VERSION "12.2.7"

NS_ :

BS_:

BU_: AMP CPD EASC HUD MHU XGW_Info PAS_Info PAS_LITE FCAM_Info

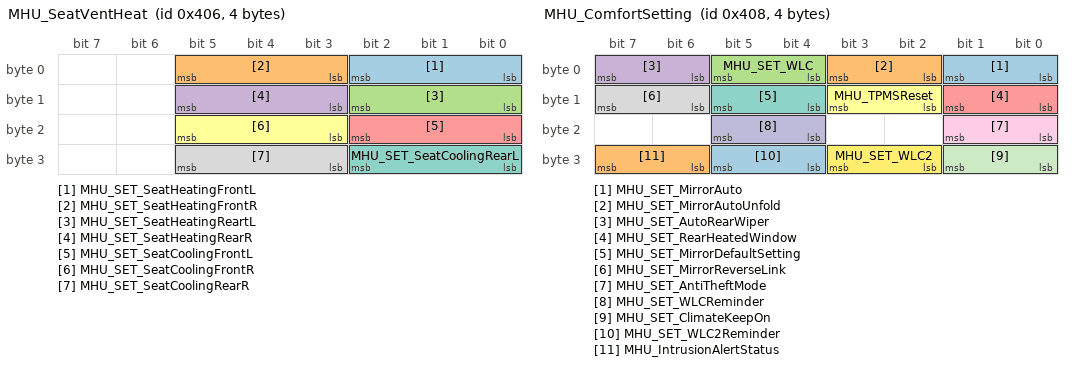
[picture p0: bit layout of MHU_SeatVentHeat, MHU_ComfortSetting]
BO_ 1030 MHU_SeatVentHeat: 4 MHU
  SG_ MHU_SET_SeatHeatingFrontL : 2|3@0+ (1,0) [0|7] "-" XGW_Info
  SG_ MHU_SET_SeatHeatingFrontR : 5|3@0+ (1,0) [0|7] "-" XGW_Info
  SG_ MHU_SET_SeatHeatingReartL : 10|3@0+ (1,0) [0|7] "-" XGW_Info
  SG_ MHU_SET_SeatHeatingRearR : 13|3@0+ (1,0) [0|7] "-" XGW_Info
  SG_ MHU_SET_SeatCoolingFrontL : 18|3@0+ (1,0) [0|7] "-" XGW_Info
  SG_ MHU_SET_SeatCoolingFrontR : 21|3@0+ (1,0) [0|7] "" XGW_Info
  SG_ MHU_SET_SeatCoolingRearL : 26|3@0+ (1,0) [0|7] "" XGW_Info
  SG_ MHU_SET_SeatCoolingRearR : 29|3@0+ (1,0) [0|7] "-" XGW_Info

BO_ 1032 MHU_ComfortSetting: 4 MHU
  SG_ MHU_SET_MirrorAuto : 1|2@0+ (1,0) [0|3] "" XGW_Info
  SG_ MHU_SET_MirrorAutoUnfold : 3|2@0+ (1,0) [0|3] "" XGW_Info
  SG_ MHU_SET_WLC : 5|2@0+ (1,0) [0|3] "-" XGW_Info
  SG_ MHU_SET_AutoRearWiper : 7|2@0+ (1,0) [0|3] "-" XGW_Info
  SG_ MHU_SET_RearHeatedWindow : 9|2@0+ (1,0) [0|3] "" XGW_Info
  SG_ MHU_TPMSReset : 11|2@0+ (1,0) [0|3] "" XGW_Info
  SG_ MHU_SET_MirrorDefaultSetting : 13|2@0+ (1,0) [0|3] "" XGW_Info
  SG_ MHU_SET_MirrorReverseLink : 15|2@0+ (1,0) [0|3] "-" XGW_Info
  SG_ MHU_SET_AntiTheftMode : 17|2@0+ (1,0) [0|3] "" XGW_Info
  SG_ MHU_SET_WLCReminder : 21|2@0+ (1,0) [0|3] "" XGW_Info
  SG_ MHU_SET_ClimateKeepOn : 25|2@0+ (1,0) [0|3] "" XGW_Info
  SG_ MHU_SET_WLC2 : 27|2@0+ (1,0) [0|3] "-" XGW_Info
  SG_ MHU_SET_WLC2Reminder : 29|2@0+ (1,0) [0|3] "-" XGW_Info
  SG_ MHU_IntrusionAlertStatus : 31|2@0+ (1,0) [0|3] "-" XGW_Info

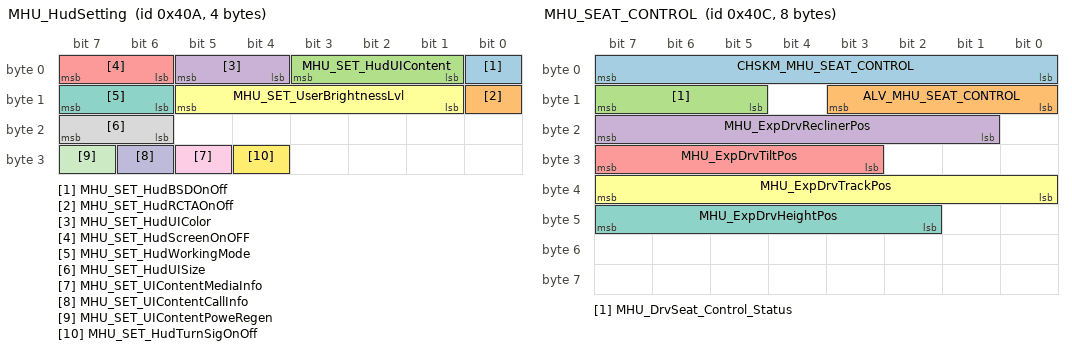
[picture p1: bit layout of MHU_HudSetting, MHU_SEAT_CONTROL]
BO_ 1034 MHU_HudSetting: 4 MHU
  SG_ MHU_SET_HudBSDOnOff : 0|1@0+ (1,0) [0|1] "" HUD
  SG_ MHU_SET_HudRCTAOnOff : 8|1@0+ (1,0) [0|1] "" HUD
  SG_ MHU_SET_HudUIContent : 3|3@0+ (1,0) [0|7] "-" HUD
  SG_ MHU_SET_HudUIColor : 5|2@0+ (1,0) [0|3] "-" HUD
  SG_ MHU_SET_HudScreenOnOFF : 7|2@0+ (1,0) [0|3] "-" HUD
  SG_ MHU_SET_UserBrightnessLvl : 13|5@0+ (1,0) [0|31] "-" HUD
  SG_ MHU_SET_HudWorkingMode : 15|2@0+ (1,0) [0|3] "-" HUD
  SG_ MHU_SET_HudUISize : 23|2@0+ (1,0) [0|3] "-" HUD
  SG_ MHU_SET_UIContentMediaInfo : 29|1@0+ (1,0) [0|1] "" HUD
  SG_ MHU_SET_UIContentCallInfo : 30|1@0+ (1,0) [0|1] "" HUD
  SG_ MHU_SET_UIContentPoweRegen : 31|1@0+ (1,0) [0|1] "" HUD
  SG_ MHU_SET_HudTurnSigOnOff : 28|1@0+ (1,0) [0|1] "" HUD

BO_ 1035 MHU_Avas_Setting: 1 MHU
  SG_ MHU_SET_AvasSound : 1|2@0+ (1,0) [0|3] "-" XGW_Info

BO_ 1036 MHU_SEAT_CONTROL: 8 MHU
  SG_ CHSKM_MHU_SEAT_CONTROL : 7|8@0+ (1,0) [0|255] "" XGW_Info
  SG_ ALV_MHU_SEAT_CONTROL : 11|4@0+ (1,0) [0|14] "" XGW_Info
  SG_ MHU_DrvSeat_Control_Status : 15|3@0+ (1,0) [0|7] "-" XGW_Info
  SG_ MHU_ExpDrvReclinerPos : 23|7@0+ (1,0) [0|127] "degree" XGW_Info
  SG_ MHU_ExpDrvTiltPos : 31|5@0+ (1,0) [0|31] "mm" XGW_Info
  SG_ MHU_ExpDrvTrackPos : 39|8@0+ (1,0) [0|255] "mm" XGW_Info
  SG_ MHU_ExpDrvHeightPos : 47|6@0+ (1,0) [0|63] "mm" XGW_Info

BO_ 1037 MHU_DIGIT_SPEED: 5 MHU
  SG_ CHKSM_MHU_DIGIT_SPEED : 7|8@0+ (1,0) [0|255] "" Vector__XXX,HUD,XGW_Info,PAS_Info,FCAM_Info,PAS_LITE
  SG_ ALV_MHU_DIGIT_SPEED : 11|4@0+ (1,0) [0|14] "" Vector__XXX,HUD,XGW_Info,PAS_Info,FCAM_Info,PAS_LITE
  SG_ MHU_DigitSpeed : 23|9@0+ (1,0) [0|300] "km/h" Vector__XXX,HUD,XGW_Info,PAS_Info,FCAM_Info,PAS_LITE

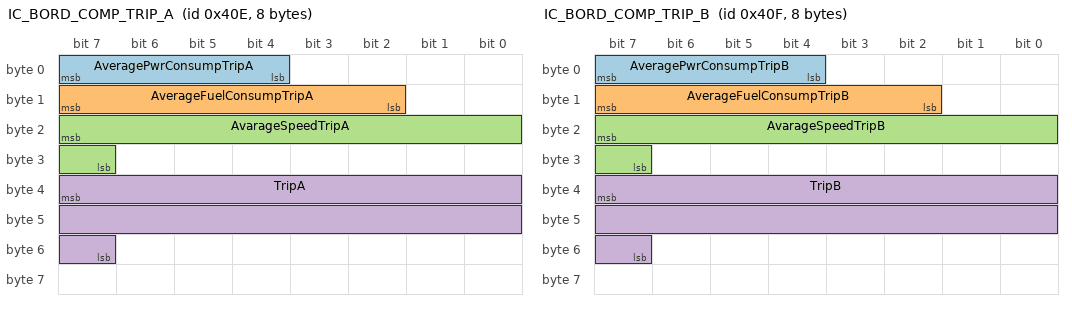
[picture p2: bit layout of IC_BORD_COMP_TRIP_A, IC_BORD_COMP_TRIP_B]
BO_ 1038 IC_BORD_COMP_TRIP_A: 8 MHU
  SG_ AveragePwrConsumpTripA : 7|4@0+ (1,0) [0|10] "km/kWh" Vector__XXX,XGW_Info
  SG_ AverageFuelConsumpTripA : 15|6@0+ (1,0) [0|51] "l/100Km" Vector__XXX,XGW_Info
  SG_ AvarageSpeedTripA : 23|9@0+ (1,0) [0|300] "kmh" Vector__XXX,XGW_Info
  SG_ TripA : 39|17@0+ (0.1,0) [0|9999.9] "km" Vector__XXX,XGW_Info

BO_ 1039 IC_BORD_COMP_TRIP_B: 8 MHU
  SG_ AveragePwrConsumpTripB : 7|4@0+ (1,0) [0|10] "km/kWh" Vector__XXX,XGW_Info
  SG_ AverageFuelConsumpTripB : 15|6@0+ (1,0) [0|51] "l/100Km" Vector__XXX,XGW_Info
  SG_ AvarageSpeedTripB : 23|9@0+ (1,0) [0|300] "kmh" Vector__XXX,XGW_Info
  SG_ TripB : 39|17@0+ (0.1,0) [0|9999.9] "km" Vector__XXX,XGW_Info

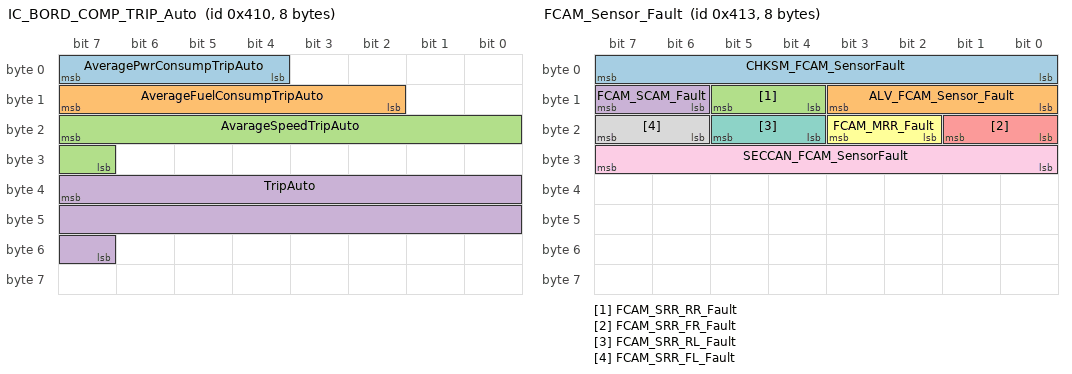
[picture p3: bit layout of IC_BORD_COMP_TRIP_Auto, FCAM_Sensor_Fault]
BO_ 1040 IC_BORD_COMP_TRIP_Auto: 8 MHU
  SG_ AveragePwrConsumpTripAuto : 7|4@0+ (1,0) [0|10] "km/kWh" Vector__XXX,XGW_Info
  SG_ AverageFuelConsumpTripAuto : 15|6@0+ (1,0) [0|51] "l/100Km" Vector__XXX,XGW_Info
  SG_ AvarageSpeedTripAuto : 23|9@0+ (1,0) [0|300] "kmh" Vector__XXX,XGW_Info
  SG_ TripAuto : 39|17@0+ (0.1,0) [0|9999.9] "km" Vector__XXX,XGW_Info

BO_ 1042 MHU_eCall_system_status: 8 MHU
 SG_ eCall_state : 2|3@0+ (1,0) [0|7] ""  XGW_Info,FCAM_Info

BO_ 1043 FCAM_Sensor_Fault: 8 FCAM_Info
 SG_ CHKSM_FCAM_SensorFault : 7|8@0+ (1,0) [0|255] ""  MHU
 SG_ ALV_FCAM_Sensor_Fault : 11|4@0+ (1,0) [0|14] ""  MHU
 SG_ FCAM_SRR_RR_Fault : 13|2@0+ (1,0) [0|3] ""  MHU
 SG_ FCAM_SCAM_Fault : 15|2@0+ (1,0) [0|3] ""  MHU
 SG_ FCAM_SRR_FR_Fault : 17|2@0+ (1,0) [0|3] ""  MHU
 SG_ FCAM_MRR_Fault : 19|2@0+ (1,0) [0|3] ""  MHU
 SG_ FCAM_SRR_RL_Fault : 21|2@0+ (1,0) [0|3] ""  MHU
 SG_ FCAM_SRR_FL_Fault : 23|2@0+ (1,0) [0|3] ""  MHU
 SG_ SECCAN_FCAM_SensorFault : 31|8@0+ (1,0) [0|255] ""  MHU

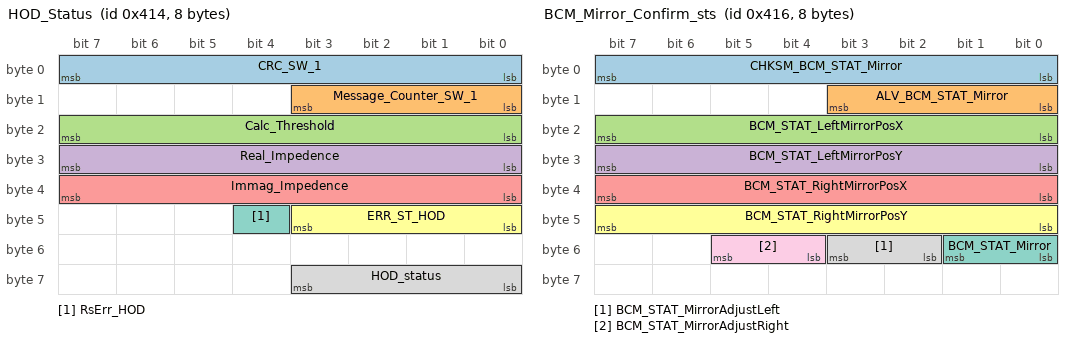
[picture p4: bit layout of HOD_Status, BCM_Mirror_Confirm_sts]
BO_ 1044 HOD_Status: 8 XGW_Info
 SG_ CRC_SW_1 : 7|8@0+ (1,0) [0|255] ""  FCAM_Info
 SG_ Message_Counter_SW_1 : 11|4@0+ (1,0) [0|14] ""  FCAM_Info
 SG_ Calc_Threshold : 23|8@0+ (1,0) [0|255] ""  Vector__XXX
 SG_ Real_Impedence : 31|8@0+ (1,0) [0|255] ""  Vector__XXX
 SG_ Immag_Impedence : 39|8@0+ (1,0) [0|255] ""  Vector__XXX
 SG_ ERR_ST_HOD : 43|4@0+ (1,0) [0|15] ""  FCAM_Info
 SG_ RsErr_HOD : 44|1@0+ (1,0) [0|1] ""  FCAM_Info
 SG_ HOD_status : 59|4@0+ (1,0) [0|15] ""  FCAM_Info

BO_ 1046 BCM_Mirror_Confirm_sts: 8 XGW_Info
  SG_ CHKSM_BCM_STAT_Mirror : 7|8@0+ (1,0) [0|255] ""  PAS_Info
  SG_ ALV_BCM_STAT_Mirror : 11|4@0+ (1,0) [0|14] ""  PAS_Info
  SG_ BCM_STAT_LeftMirrorPosX : 23|8@0+ (1,-15) [-15|15] "deg"  MHU,PAS_Info
  SG_ BCM_STAT_LeftMirrorPosY : 31|8@0+ (1,-15) [-15|15] "deg"  MHU,PAS_Info
  SG_ BCM_STAT_RightMirrorPosX : 39|8@0+ (1,-15) [-15|15] "deg"  MHU
  SG_ BCM_STAT_RightMirrorPosY : 47|8@0+ (1,-15) [-15|15] "deg"  MHU
  SG_ BCM_STAT_Mirror : 49|2@0+ (1,0) [0|3] ""  MHU,PAS_Info
  SG_ BCM_STAT_MirrorAdjustLeft : 51|2@0+ (1,0) [0|3] "-"  MHU
  SG_ BCM_STAT_MirrorAdjustRight : 53|2@0+ (1,0) [0|3] ""  MHU

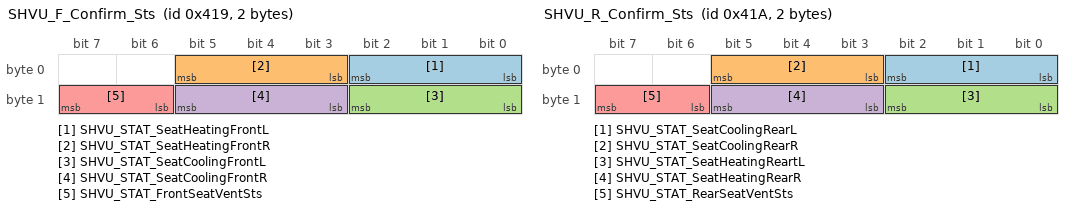
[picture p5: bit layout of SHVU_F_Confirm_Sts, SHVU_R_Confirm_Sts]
BO_ 1049 SHVU_F_Confirm_Sts: 2 XGW_Info
  SG_ SHVU_STAT_SeatHeatingFrontL : 2|3@0+ (1,0) [0|7] "-" MHU
  SG_ SHVU_STAT_SeatHeatingFrontR : 5|3@0+ (1,0) [0|7] "-" MHU
  SG_ SHVU_STAT_SeatCoolingFrontL : 10|3@0+ (1,0) [0|7] "-" MHU
  SG_ SHVU_STAT_SeatCoolingFrontR : 13|3@0+ (1,0) [0|7] "" MHU
  SG_ SHVU_STAT_FrontSeatVentSts : 15|2@0+ (1,0) [0|3] "" MHU

BO_ 1050 SHVU_R_Confirm_Sts: 2 XGW_Info
  SG_ SHVU_STAT_SeatCoolingRearL : 2|3@0+ (1,0) [0|7] "-" MHU
  SG_ SHVU_STAT_SeatCoolingRearR : 5|3@0+ (1,0) [0|7] "" MHU
  SG_ SHVU_STAT_SeatHeatingReartL : 10|3@0+ (1,0) [0|7] "" MHU
  SG_ SHVU_STAT_SeatHeatingRearR : 13|3@0+ (1,0) [0|7] "" MHU
  SG_ SHVU_STAT_RearSeatVentSts : 15|2@0+ (1,0) [0|3] "" MHU

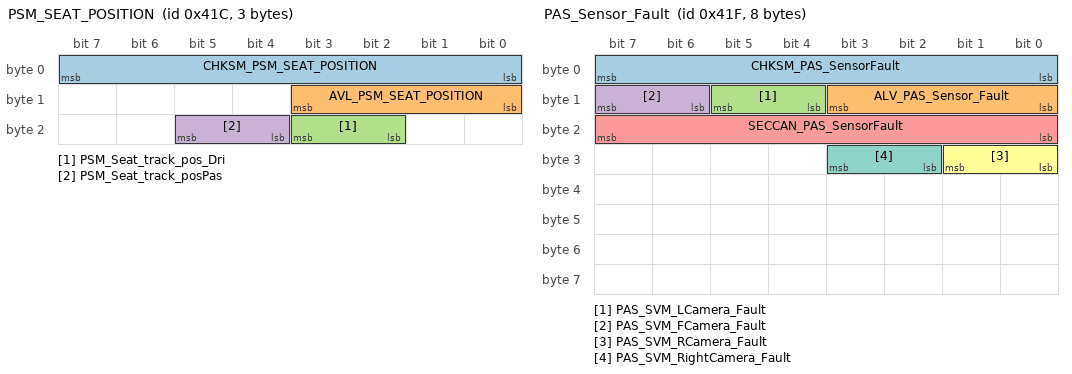
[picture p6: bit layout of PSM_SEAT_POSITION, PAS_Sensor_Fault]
BO_ 1052 PSM_SEAT_POSITION: 3 XGW_Info
  SG_ CHKSM_PSM_SEAT_POSITION : 7|8@0+ (1,0) [0|255] "" MHU
  SG_ AVL_PSM_SEAT_POSITION : 11|4@0+ (1,0) [0|14] "-" MHU
  SG_ PSM_Seat_track_pos_Dri : 19|2@0+ (1,0) [0|3] "" MHU
  SG_ PSM_Seat_track_posPas : 21|2@0+ (1,0) [0|3] "" MHU

BO_ 1053 BCM_Comfort_Confirm_sts: 8 XGW_Info
  SG_ BCM_STAT_AutoRearWiper : 1|2@0+ (1,0) [0|3] "-" MHU
  SG_ BCM_STAT_MirrorFoldSetting : 3|2@0+ (1,0) [0|3] "" MHU
  SG_ BCM_STAT_IMMO_KeyfobID2 : 7|3@0+ (1,0) [0|7] "" MHU
  SG_ BCM_STAT_MirrorAutoUnfold : 9|2@0+ (1,0) [0|3] "-" MHU
  SG_ BCM_STAT_MirrorReverseLink : 11|2@0+ (1,0) [0|3] "" MHU
  SG_ BCM_STAT_MirrorDefaultSTATting : 13|2@0+ (1,0) [0|3] "-" MHU
  SG_ BCM_STAT_WelcomeTriggerCondition : 15|2@0+ (1,0) [0|3] "" MHU
  SG_ BCM_STAT_FrontDomeLamp : 17|2@0+ (1,0) [0|3] "-" MHU
  SG_ BCM_STAT_FollowMeHome : 20|3@0+ (1,0) [0|7] "-" MHU
  SG_ BCM_STAT_ExteriorLight : 23|3@0+ (1,0) [0|7] "-" MHU
  SG_ BCM_STAT_RemoteLockFeedback : 26|3@0+ (1,0) [0|7] "-" MHU
  SG_ BCM_STAT_RemoteDoorUnlock : 28|2@0+ (1,0) [0|3] "" MHU
  SG_ BCM_STAT_AutoDoorUnlock : 30|2@0+ (1,0) [0|3] "" MHU
  SG_ BCM_STAT_WalkawayDoorLock : 31|1@0+ (1,0) [0|1] "" MHU
  SG_ BCM_STAT_AmbientLightBrighness : 39|7@0+ (1,0) [0|100] "%" MHU
  SG_ BCM_STAT_WiperServiceMode : 42|2@0+ (1,0) [0|3] "" MHU
  SG_ BCM_STAT_IMMO_KeyfobID : 45|2@0+ (1,0) [0|3] "" MHU
  SG_ BCM_STAT_RearHeatedWindowMirror : 47|2@0+ (1,0) [0|3] "" MHU
  SG_ BCM_STAT_AntiTheftMode : 50|3@0+ (1,0) [0|7] "-" MHU
  SG_ BCM_STAT_ClimateKeepOnSts : 53|2@0+ (1,0) [0|3] "" MHU
  SG_ BCM_STAT_FKSfeedback : 55|2@0+ (1,0) [0|3] "" MHU
  SG_ SECCAN_CmftCnfrm : 63|8@0+ (1,0) [0|255] "" MHU

BO_ 1054 HUD_State: 8 HUD
  SG_ HUD_BSDOnOff_Feed : 0|1@0+ (1,0) [0|1] "-" MHU
  SG_ HUD_RCTAOnOff_Feed : 8|1@0+ (1,0) [0|1] "-" MHU
  SG_ HUD_UIColor : 2|2@0+ (1,0) [0|3] "-" MHU
  SG_ HUD_UIContent : 5|3@0+ (1,0) [0|7] "-" MHU
  SG_ HUD_OperationState : 7|2@0+ (1,0) [0|3] "-" MHU
  SG_ HUD_HeightLvl : 13|5@0+ (1,0) [0|31] "-" MHU
  SG_ HUD_UI_Size : 15|2@0+ (1,0) [0|3] "-" MHU
  SG_ HUD_UIContentMediaInfo : 16|1@0+ (1,0) [0|1] "" MHU
  SG_ HUD_UIContentCallInfor : 17|1@0+ (1,0) [0|1] "" MHU
  SG_ HUD_UIContentPowerRegen : 18|1@0+ (1,0) [0|1] "" MHU
  SG_ HUD_UIModeSignal : 21|3@0+ (1,0) [0|7] "-" MHU
  SG_ HUD_WorkingMode : 23|2@0+ (1,0) [0|3] "-" MHU
  SG_ HUD_ActualBrightnes : 31|14@0+ (1,0) [0|12000] "cd/m2" MHU
  SG_ HUD_RotateAngleLvl : 42|4@0+ (1,0) [0|15] "-" MHU
  SG_ HUD_UserSetBrightnessLvl : 47|5@0+ (1,0) [0|31] "-" MHU
  SG_ HUD_Language : 54|5@0+ (1,0) [0|31] "-" MHU
  SG_ HUD_TurnSigOnOff_Feed : 56|1@0+ (1,0) [0|1] "-" MHU
  SG_ HUD_Mileage_Unit : 57|1@0+ (1,0) [0|1] "-" MHU
  SG_ HUD_UserProfileId : 61|4@0+ (1,0) [0|15] "-" MHU
  SG_ HUD_DimmingDelayTime : 63|2@0+ (1,0) [0|3] "-" MHU

BO_ 1055 PAS_Sensor_Fault: 8 PAS_Info
 SG_ CHKSM_PAS_SensorFault : 7|8@0+ (1,0) [0|255] ""  MHU
 SG_ ALV_PAS_Sensor_Fault : 11|4@0+ (1,0) [0|14] ""  MHU
 SG_ PAS_SVM_LCamera_Fault : 13|2@0+ (1,0) [0|3] ""  MHU
 SG_ PAS_SVM_FCamera_Fault : 15|2@0+ (1,0) [0|3] ""  MHU
 SG_ SECCAN_PAS_SensorFault : 23|8@0+ (1,0) [0|255] ""  MHU
 SG_ PAS_SVM_RCamera_Fault : 25|2@0+ (1,0) [0|3] ""  MHU
 SG_ PAS_SVM_RightCamera_Fault : 27|2@0+ (1,0) [0|3] ""  MHU

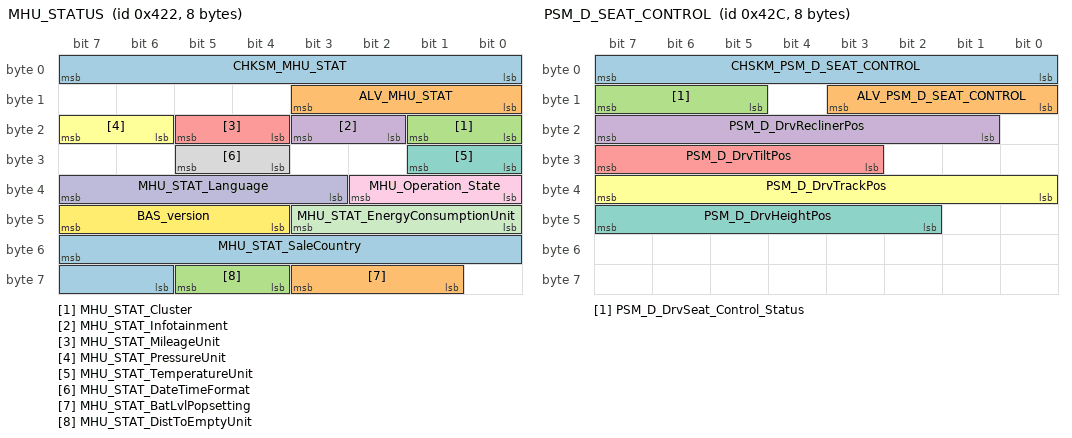
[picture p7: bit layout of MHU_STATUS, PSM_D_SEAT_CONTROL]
BO_ 1058 MHU_STATUS: 8 MHU
  SG_ CHKSM_MHU_STAT : 7|8@0+ (1,0) [0|255] "" Vector__XXX,HUD,XGW_Info,FCAM_Info
  SG_ ALV_MHU_STAT : 11|4@0+ (1,0) [0|14] "" Vector__XXX,HUD,XGW_Info,FCAM_Info
  SG_ MHU_STAT_Cluster : 17|2@0+ (1,0) [0|3] "-" Vector__XXX,HUD,XGW_Info,FCAM_Info
  SG_ MHU_STAT_Infotainment : 19|2@0+ (1,0) [0|3] "" Vector__XXX,HUD,XGW_Info,FCAM_Info
  SG_ MHU_STAT_MileageUnit : 21|2@0+ (1,0) [0|3] "" Vector__XXX,HUD,XGW_Info,FCAM_Info
  SG_ MHU_STAT_PressureUnit : 23|2@0+ (1,0) [0|3] "-" HUD,XGW_Info
  SG_ MHU_STAT_TemperatureUnit : 25|2@0+ (1,0) [0|3] "-" HUD,XGW_Info
  SG_ MHU_STAT_DateTimeFormat : 29|2@0+ (1,0) [0|3] "-" HUD,XGW_Info
  SG_ MHU_Operation_State : 34|3@0+ (1,0) [0|7] "" Vector__XXX,HUD,XGW_Info,FCAM_Info
  SG_ MHU_STAT_Language : 39|5@0+ (1,0) [0|31] "-" HUD,XGW_Info
  SG_ MHU_STAT_EnergyConsumptionUnit : 43|4@0+ (1,0) [0|15] "-" Vector__XXX,HUD,XGW_Info,FCAM_Info
  SG_ BAS_version : 47|4@0+ (1,0) [0|15] "" XGW_Info
  SG_ MHU_STAT_SaleCountry : 55|10@0+ (1,0) [0|1023] "-" Vector__XXX,HUD,XGW_Info,FCAM_Info
  SG_ MHU_STAT_BatLvlPopsetting : 59|3@0+ (1,0) [0|7] "-" HUD
  SG_ MHU_STAT_DistToEmptyUnit : 61|2@0+ (1,0) [0|3] "-" HUD

BO_ 1059 AVAS_STATUS: 8 XGW_Info
  SG_ AVAS_BatteryUnderVoltage : 0|1@0+ (1,0) [0|1] "-" MHU
  SG_ AVAS_BatteryOverVoltage : 1|1@0+ (1,0) [0|1] "-" MHU
  SG_ AVAS_VINInfoNotPrgm : 2|1@0+ (1,0) [0|1] "" MHU
  SG_ AVAS_AMPVoltSplDrvOperationFail : 3|1@0+ (1,0) [0|1] "-" MHU
  SG_ AVAS_AMPIntFaultOverCurr : 4|1@0+ (1,0) [0|1] "" MHU
  SG_ AVAS_AMPInternalFaultDCError : 5|1@0+ (1,0) [0|1] "" MHU
  SG_ AVAS_AMPInternalFaultOverTemp : 6|1@0+ (1,0) [0|1] "" MHU
  SG_ AVAS_AMPInternalFaultClockError : 7|1@0+ (1,0) [0|1] "-" MHU
  SG_ AVAS_SpkrMntPwrSwDrvHighFlt : 8|1@0+ (1,0) [0|1] "-" MHU
  SG_ AVAS_SpkrMntPwrSwDrvLowFlt : 9|1@0+ (1,0) [0|1] "-" MHU
  SG_ AVAS_InternalSpeakerOpen : 10|1@0+ (1,0) [0|1] "" MHU
  SG_ AVAS_ECUMalFlshOperationErr : 11|1@0+ (1,0) [0|1] "" MHU
  SG_ AVAS_ECUMalfunctionRamFailure : 12|1@0+ (1,0) [0|1] "-" MHU
  SG_ AVAS_ECUMalEEPROMFailure : 13|1@0+ (1,0) [0|1] "" MHU
  SG_ AVAS_CANBusOff : 14|1@0+ (1,0) [0|1] "-" MHU
  SG_ AVAS_LossCommVehicleSpeed : 15|1@0+ (1,0) [0|1] "" MHU
  SG_ AVAS_LossCommGearPosition : 16|1@0+ (1,0) [0|1] "-" MHU
  SG_ AVAS_LossCommAVASCloseCmd : 17|1@0+ (1,0) [0|1] "-" MHU

BO_ 1064 XGW_CH_1: 1 XGW_Info
 SG_ TRMFitted : 2|2@0+ (1,0) [0|3] "" PAS_LITE

BO_ 1068 PSM_D_SEAT_CONTROL: 8 XGW_Info
  SG_ CHSKM_PSM_D_SEAT_CONTROL : 7|8@0+ (1,0) [0|255] "" MHU
  SG_ ALV_PSM_D_SEAT_CONTROL : 11|4@0+ (1,0) [0|14] "" MHU
  SG_ PSM_D_DrvSeat_Control_Status : 15|3@0+ (1,0) [0|7] "" MHU
  SG_ PSM_D_DrvReclinerPos : 23|7@0+ (1,0) [0|127] "degree" MHU
  SG_ PSM_D_DrvTiltPos : 31|5@0+ (1,0) [0|31] "mm" MHU
  SG_ PSM_D_DrvTrackPos : 39|8@0+ (1,0) [0|255] "mm" MHU
  SG_ PSM_D_DrvHeightPos : 47|6@0+ (1,0) [0|63] "mm" MHU

BO_ 1069 XGW_Info_Collect: 3 XGW_Info
  SG_ XGW_WasherFluid_LevelSwitch : 1|2@0+ (1,0) [0|3] "Bit" MHU

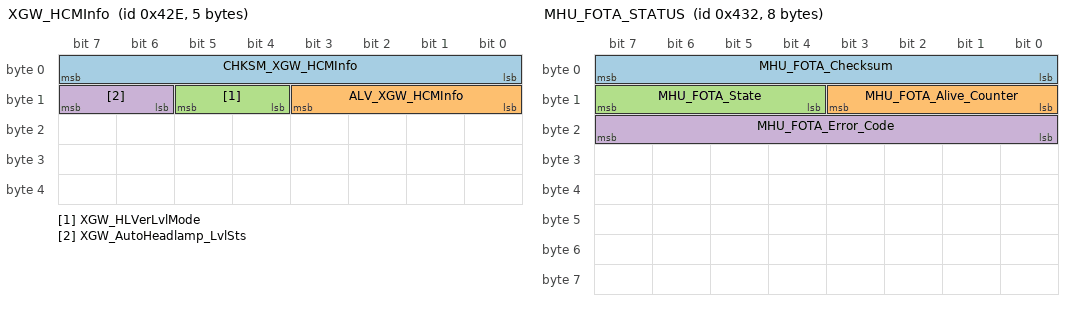
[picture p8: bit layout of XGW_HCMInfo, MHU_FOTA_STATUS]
BO_ 1070 XGW_HCMInfo: 5 XGW_Info
  SG_ CHKSM_XGW_HCMInfo : 7|8@0+ (1,0) [0|255] "" MHU
  SG_ ALV_XGW_HCMInfo : 11|4@0+ (1,0) [0|14] "" MHU
  SG_ XGW_HLVerLvlMode : 13|2@0+ (1,0) [0|3] "-" MHU
  SG_ XGW_AutoHeadlamp_LvlSts : 15|2@0+ (1,0) [0|3] "-" MHU

BO_ 1073 HUD_ECU_Status: 2 HUD
  SG_ HUD_ECU_Check : 7|8@0+ (1,0) [0|255] "-" XGW_Info
  SG_ HUD_ECU_Fault : 15|8@0+ (1,0) [0|255] "-" XGW_Info

BO_ 1074 MHU_FOTA_STATUS: 8 MHU
  SG_ MHU_FOTA_Checksum : 7|8@0+ (1,0) [0|255] "" AMP,FCAM_Info,CPD,EASC,HUD,PAS_Info,XGW_Info
  SG_ MHU_FOTA_Alive_Counter : 11|4@0+ (1,0) [0|14] "" AMP,FCAM_Info,CPD,EASC,HUD,PAS_Info,XGW_Info
  SG_ MHU_FOTA_State : 15|4@0+ (1,0) [0|14] "-" AMP,FCAM_Info,CPD,EASC,HUD,PAS_Info,XGW_Info
  SG_ MHU_FOTA_Error_Code : 23|8@0+ (1,0) [0|255] "-" AMP,FCAM_Info,CPD,EASC,HUD,PAS_Info,XGW_Info

BO_ 1075 MHU_HEADLAMP_CTL: 2 MHU
  SG_ MHU_Headlamp_Chksm : 7|8@0+ (1,0) [0|255] "-" XGW_Info
  SG_ MHU_Headlamp_Aliv : 11|4@0+ (1,0) [0|14] "-" XGW_Info
  SG_ MHU_HLVerLvlMode : 15|2@0+ (1,0) [0|3] "-" XGW_Info

BO_ 1077 BCM_SCM_LIN_Info: 1 XGW_Info
  SG_ BCM_SCM_BC_Button : 1|2@0+ (1,0) [0|3] "-" HUD,MHU

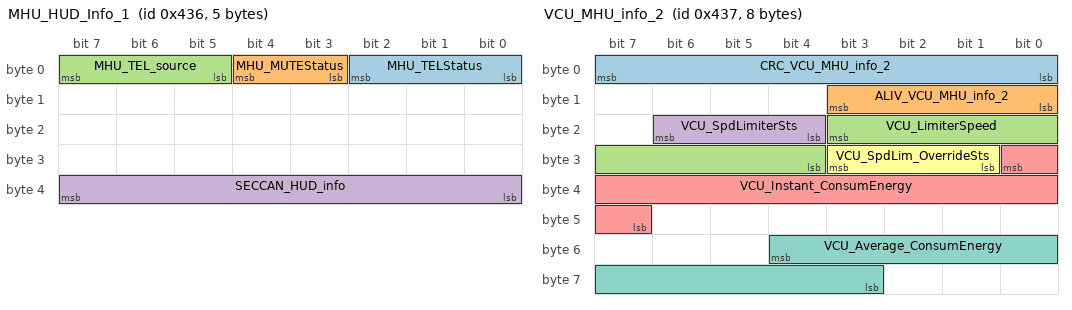
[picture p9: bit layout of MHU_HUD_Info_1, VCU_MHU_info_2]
BO_ 1078 MHU_HUD_Info_1: 5 MHU
  SG_ MHU_TELStatus : 2|3@0+ (1,0) [0|7] "-" HUD
  SG_ MHU_MUTEStatus : 4|2@0+ (1,0) [0|3] "-" HUD
  SG_ MHU_TEL_source : 7|3@0+ (1,0) [0|7] "-" HUD
  SG_ SECCAN_HUD_info : 39|8@0+ (1,0) [0|255] "" HUD

BO_ 1079 VCU_MHU_info_2: 8 XGW_Info
  SG_ CRC_VCU_MHU_info_2 : 7|8@0+ (1,0) [0|255] "" MHU,HUD
  SG_ ALIV_VCU_MHU_info_2 : 11|4@0+ (1,0) [0|14] "" MHU,HUD
  SG_ VCU_LimiterSpeed : 19|8@0+ (1,0) [0|200] "km/h"  MHU,HUD
  SG_ VCU_SpdLimiterSts : 22|3@0+ (1,0) [0|7] ""  MHU,HUD
  SG_ VCU_Instant_ConsumEnergy : 24|10@0+ (0.1,0) [0|100] "kWh/100km" MHU
  SG_ VCU_SpdLim_OverrideSts : 27|3@0+ (10,0) [0|30] "km/h"  MHU
  SG_ VCU_Average_ConsumEnergy : 52|10@0+ (0.1,0) [0|100] "kWh/100km" MHU

BO_ 1080 EDS_Error_FR_A: 8 XGW_Info
  SG_ CHKSM_EDS_Error_FR_A : 7|8@0+ (1,0) [0|255] "" MHU
  SG_ ALV_EDS_Error_FR_A : 11|4@0+ (1,0) [0|14] "" MHU
  SG_ EDS_FailNum_ERR_FWD : 23|8@0+ (1,0) [0|255] "" MHU
  SG_ EDS_FailGrade_ERR_FWD : 26|3@0+ (1,0) [0|7] "" MHU
  SG_ EDS_MotOverTempAlarm_FWD : 27|1@0+ (1,0) [0|1] "" MHU
  SG_ EDS_MotOverTempFault_FWD : 28|1@0+ (1,0) [0|1] "" MHU
  SG_ EDS_MotTempSenFault_FWD : 29|1@0+ (1,0) [0|1] "" MHU
  SG_ EDS_EDSOverTempUFault_FWD : 30|1@0+ (1,0) [0|1] "" MHU
  SG_ EDS_EDSOverTempVFault_FWD : 31|1@0+ (1,0) [0|1] "" MHU
  SG_ EDS_EDSOverTempWFault_FWD : 32|1@0+ (1,0) [0|1] "" MHU
  SG_ EDS_EDSOverTempAlarm_FWD : 33|1@0+ (1,0) [0|1] "" MHU
  SG_ EDS_TCoolantOvHi_FWD : 34|1@0+ (1,0) [0|1] "" MHU
  SG_ EDS_EDSTempCmpAlarm_FWD : 35|1@0+ (1,0) [0|1] "" MHU
  SG_ EDS_EDSPhaOvCurentHWFault_FWD : 36|1@0+ (1,0) [0|1] "" MHU
  SG_ EDS_EDSphaOffCalFault_FWD : 37|1@0+ (1,0) [0|1] "" MHU
  SG_ EDS_EDSOverIdcLnkAlarm_FWD : 38|1@0+ (1,0) [0|1] "" MHU
  SG_ EDS_EDSHVOverVoltageAlarm_FWD : 39|1@0+ (1,0) [0|1] "" MHU
  SG_ EDS_EDSHVOverVoltageFault_FWD : 40|1@0+ (1,0) [0|1] "" MHU
  SG_ EDS_EDSHVUnderVoltageAlarm_FWD : 41|1@0+ (1,0) [0|1] "" MHU
  SG_ EDS_EDSHVUnderVoltageFault_FWD : 42|1@0+ (1,0) [0|1] "" MHU
  SG_ EDS_RunToDischaErr_FWD : 43|1@0+ (1,0) [0|1] "" MHU
  SG_ EDS_12VOverVoltageAlarm_FWD : 44|1@0+ (1,0) [0|1] "" MHU
  SG_ EDS_12VUnderVoltageAlarm_FWD : 45|1@0+ (1,0) [0|1] "" MHU
  SG_ EDS_MotOverAlarm_FWD : 46|1@0+ (1,0) [0|1] "" MHU
  SG_ EDS_MotOverFault_FWD : 47|1@0+ (1,0) [0|1] "" MHU
  SG_ EDS_ResolverOffsetAngle_FWD : 48|1@0+ (1,0) [0|1] "" MHU
  SG_ SECCAN_EDS_Error_FR_A : 63|8@0+ (1,0) [0|255] "" MHU

BO_ 1081 EDS_Error_RR_A: 8 XGW_Info
  SG_ CHKSM_EDS_Error_RR_A : 7|8@0+ (1,0) [0|255] "" MHU
  SG_ ALV_EDS_Error_RR_A : 11|4@0+ (1,0) [0|14] "" MHU
  SG_ EDS_FailNum_ERR_RWD : 23|8@0+ (1,0) [0|255] "" MHU
  SG_ EDS_FailGrade_ERR_RWD : 26|3@0+ (1,0) [0|7] "" MHU
  SG_ EDS_MotOverTempAlarm_RWD : 27|1@0+ (1,0) [0|1] "" MHU
  SG_ EDS_MotOverTempFault_RWD : 28|1@0+ (1,0) [0|1] "" MHU
  SG_ EDS_MotTempSenFault_RWD : 29|1@0+ (1,0) [0|1] "" MHU
  SG_ EDS_EDSOverTempUFault_RWD : 30|1@0+ (1,0) [0|1] "" MHU
  SG_ EDS_EDSOverTempVFault_RWD : 31|1@0+ (1,0) [0|1] "" MHU
  SG_ EDS_EDSOverTempWFault_RWD : 32|1@0+ (1,0) [0|1] "" MHU
  SG_ EDS_EDSOverTempAlarm_RWD : 33|1@0+ (1,0) [0|1] "" MHU
  SG_ EDS_TCoolantOvHi_RWD : 34|1@0+ (1,0) [0|1] "" MHU
  SG_ EDS_EDSTempCmpAlarm_RWD : 35|1@0+ (1,0) [0|1] "" MHU
  SG_ EDS_EDSPhaOvCurentHWFault_RWD : 36|1@0+ (1,0) [0|1] "" MHU
  SG_ EDS_EDSphaOffCalFault_RWD : 37|1@0+ (1,0) [0|1] "" MHU
  SG_ EDS_EDSOverIdcLnkAlarm_RWD : 38|1@0+ (1,0) [0|1] "" MHU
  SG_ EDS_EDSHVOverVoltageAlarm_RWD : 39|1@0+ (1,0) [0|1] "" MHU
  SG_ EDS_EDSHVOverVoltageFault_RWD : 40|1@0+ (1,0) [0|1] "" MHU
  SG_ EDS_EDSHVUnderVoltageAlarm_RWD : 41|1@0+ (1,0) [0|1] "" MHU
  SG_ EDS_EDSHVUnderVoltageFault_RWD : 42|1@0+ (1,0) [0|1] "" MHU
  SG_ EDS_RunToDischaErr_RWD : 43|1@0+ (1,0) [0|1] "" MHU
  SG_ EDS_12VOverVoltageAlarm_RWD : 44|1@0+ (1,0) [0|1] "" MHU
  SG_ EDS_12VUnderVoltageAlarm_RWD : 45|1@0+ (1,0) [0|1] "" MHU
  SG_ EDS_MotOverAlarm_RWD : 46|1@0+ (1,0) [0|1] "" MHU
  SG_ EDS_MotOverFault_RWD : 47|1@0+ (1,0) [0|1] "" MHU
  SG_ EDS_ResolverOffsetAngle_RWD : 48|1@0+ (1,0) [0|1] "" MHU
  SG_ SECCAN_EDS_Error_RR_A : 63|8@0+ (1,0) [0|255] "" MHU

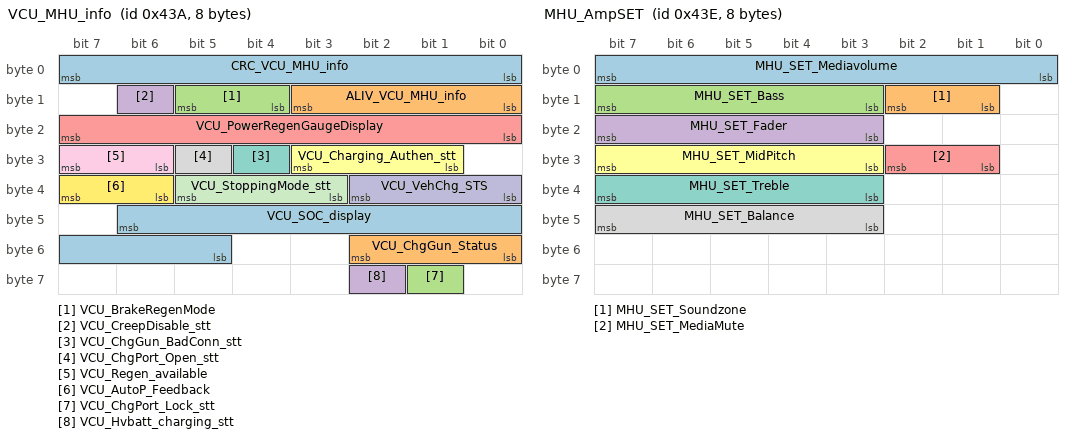
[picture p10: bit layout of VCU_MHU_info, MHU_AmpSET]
BO_ 1082 VCU_MHU_info: 8 XGW_Info
  SG_ CRC_VCU_MHU_info : 7|8@0+ (1,0) [0|255] "" HUD,MHU
  SG_ ALIV_VCU_MHU_info : 11|4@0+ (1,0) [0|14] "" HUD,MHU
  SG_ VCU_BrakeRegenMode : 13|2@0+ (1,0) [0|3] "-" HUD,MHU
  SG_ VCU_CreepDisable_stt : 14|1@0+ (1,0) [0|1] "" HUD,MHU
  SG_ VCU_PowerRegenGaugeDisplay : 23|8@0+ (1,-100) [-100|100] "%" HUD,MHU
  SG_ VCU_Charging_Authen_stt : 27|3@0+ (1,0) [0|7] "-" HUD,MHU
  SG_ VCU_ChgGun_BadConn_stt : 28|1@0+ (1,0) [0|1] "" HUD,MHU
  SG_ VCU_ChgPort_Open_stt : 29|1@0+ (1,0) [0|1] "" HUD,MHU
  SG_ VCU_Regen_available : 31|2@0+ (1,0) [0|3] "" HUD,MHU
  SG_ VCU_VehChg_STS : 34|3@0+ (1,0) [0|7] "" HUD,MHU
  SG_ VCU_StoppingMode_stt : 37|3@0+ (1,0) [0|7] "" MHU
  SG_ VCU_AutoP_Feedback : 39|2@0+ (1,0) [0|3] ""  MHU
  SG_ VCU_SOC_display : 46|10@0+ (0.1,0) [0|100] "%" HUD,MHU
  SG_ VCU_ChgGun_Status : 50|3@0+ (1,0) [0|7] "" HUD,MHU
  SG_ VCU_ChgPort_Lock_stt : 57|1@0+ (1,0) [0|1] "" HUD,MHU
  SG_ VCU_Hvbatt_charging_stt : 58|1@0+ (1,0) [0|1] "-" HUD,MHU

BO_ 1083 MHU_SteeringAdjust: 3 MHU
  SG_ MHU_SET_TiltPos : 7|8@0+ (1,0) [0|100] "%" EASC
  SG_ MHU_SET_TelePos : 15|8@0+ (1,0) [0|100] "%" EASC
  SG_ MHU_SET_SteeringAdjust : 23|2@0+ (1,0) [0|3] "-" EASC

BO_ 1084 EASC_Confirm_sts: 3 EASC
  SG_ EASC_TiltPos : 7|8@0+ (1,0) [0|100] "%" MHU
  SG_ EASC_TelePos : 15|8@0+ (1,0) [0|100] "%" MHU
  SG_ EASC_SteeringAdjust : 23|2@0+ (1,0) [0|3] "-" MHU

BO_ 1086 MHU_AmpSET: 8 MHU
  SG_ MHU_SET_Mediavolume : 7|8@0+ (1,0) [0|40] "-" AMP
  SG_ MHU_SET_Soundzone : 10|2@0+ (1,0) [0|3] "-" AMP
  SG_ MHU_SET_Bass : 15|5@0+ (1,-6) [-6|6] "-" AMP
  SG_ MHU_SET_Fader : 23|5@0+ (1,-10) [-10|10] "-" AMP
  SG_ MHU_SET_MediaMute : 26|2@0+ (1,0) [1|3] "-" AMP
  SG_ MHU_SET_MidPitch : 31|5@0+ (1,-6) [-6|6] "-" AMP
  SG_ MHU_SET_Treble : 39|5@0+ (1,-6) [-6|6] "-" AMP
  SG_ MHU_SET_Balance : 47|5@0+ (1,-10) [-10|10] "-" AMP

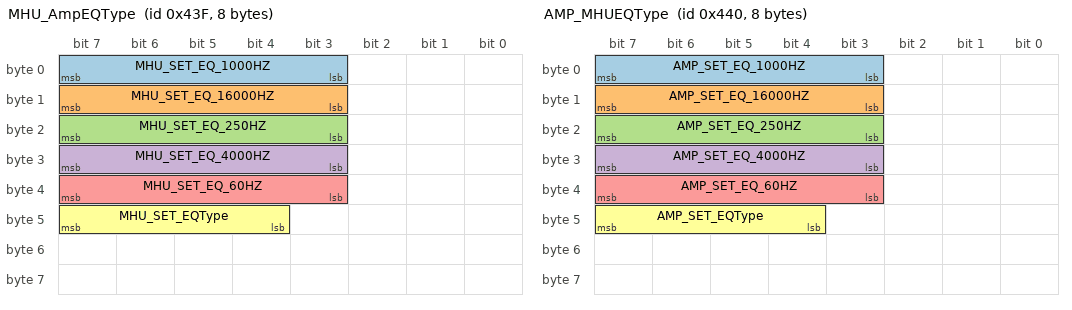
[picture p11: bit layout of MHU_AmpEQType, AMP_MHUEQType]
BO_ 1087 MHU_AmpEQType: 8 MHU
  SG_ MHU_SET_EQ_1000HZ : 7|5@0+ (1,-6) [-6|6] "-" AMP
  SG_ MHU_SET_EQ_16000HZ : 15|5@0+ (1,-6) [-6|6] "-" AMP
  SG_ MHU_SET_EQ_250HZ : 23|5@0+ (1,-6) [-6|6] "-" AMP
  SG_ MHU_SET_EQ_4000HZ : 31|5@0+ (1,-6) [-6|6] "-" AMP
  SG_ MHU_SET_EQ_60HZ : 39|5@0+ (1,-6) [-6|6] "-" AMP
  SG_ MHU_SET_EQType : 47|4@0+ (1,0) [0|15] "-" AMP

BO_ 1088 AMP_MHUEQType: 8 AMP
  SG_ AMP_SET_EQ_1000HZ : 7|5@0+ (1,-6) [-6|6] "-" MHU
  SG_ AMP_SET_EQ_16000HZ : 15|5@0+ (1,-6) [-6|6] "-" MHU
  SG_ AMP_SET_EQ_250HZ : 23|5@0+ (1,-6) [-6|6] "-" MHU
  SG_ AMP_SET_EQ_4000HZ : 31|5@0+ (1,-6) [-6|6] "-" MHU
  SG_ AMP_SET_EQ_60HZ : 39|5@0+ (1,-6) [-6|6] "-" MHU
  SG_ AMP_SET_EQType : 47|4@0+ (1,0) [0|15] "-" MHU

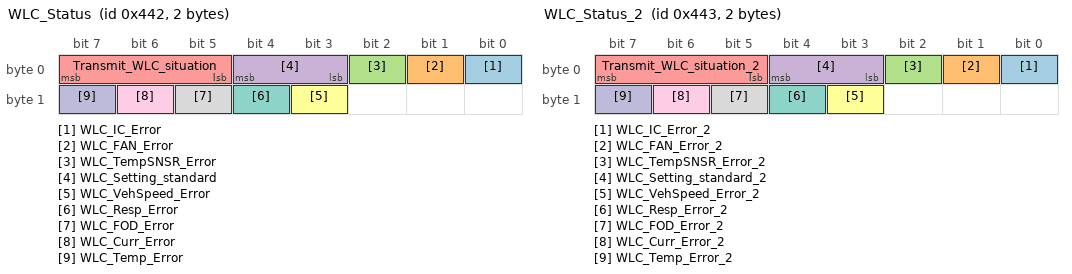
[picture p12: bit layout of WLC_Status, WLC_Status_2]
BO_ 1090 WLC_Status: 2 XGW_Info
  SG_ WLC_IC_Error : 0|1@0+ (1,0) [0|1] "" MHU
  SG_ WLC_FAN_Error : 1|1@0+ (1,0) [0|1] "-" MHU
  SG_ WLC_TempSNSR_Error : 2|1@0+ (1,0) [0|1] "-" MHU
  SG_ WLC_Setting_standard : 4|2@0+ (1,0) [0|3] "-" MHU
  SG_ Transmit_WLC_situation : 7|3@0+ (1,0) [0|7] "" MHU
  SG_ WLC_VehSpeed_Error : 11|1@0+ (1,0) [0|1] "" MHU
  SG_ WLC_Resp_Error : 12|1@0+ (1,0) [0|1] "" MHU
  SG_ WLC_FOD_Error : 13|1@0+ (1,0) [0|1] "-" MHU
  SG_ WLC_Curr_Error : 14|1@0+ (1,0) [0|1] "-" MHU
  SG_ WLC_Temp_Error : 15|1@0+ (1,0) [0|1] "" MHU

BO_ 1091 WLC_Status_2: 2 XGW_Info
  SG_ WLC_IC_Error_2 : 0|1@0+ (1,0) [0|1] "-" MHU
  SG_ WLC_FAN_Error_2 : 1|1@0+ (1,0) [0|1] "" MHU
  SG_ WLC_TempSNSR_Error_2 : 2|1@0+ (1,0) [0|1] "-" MHU
  SG_ WLC_Setting_standard_2 : 4|2@0+ (1,0) [0|3] "" MHU
  SG_ Transmit_WLC_situation_2 : 7|3@0+ (1,0) [0|7] "" MHU
  SG_ WLC_VehSpeed_Error_2 : 11|1@0+ (1,0) [0|1] "" MHU
  SG_ WLC_Resp_Error_2 : 12|1@0+ (1,0) [0|1] "-" MHU
  SG_ WLC_FOD_Error_2 : 13|1@0+ (1,0) [0|1] "-" MHU
  SG_ WLC_Curr_Error_2 : 14|1@0+ (1,0) [0|1] "-" MHU
  SG_ WLC_Temp_Error_2 : 15|1@0+ (1,0) [0|1] "" MHU

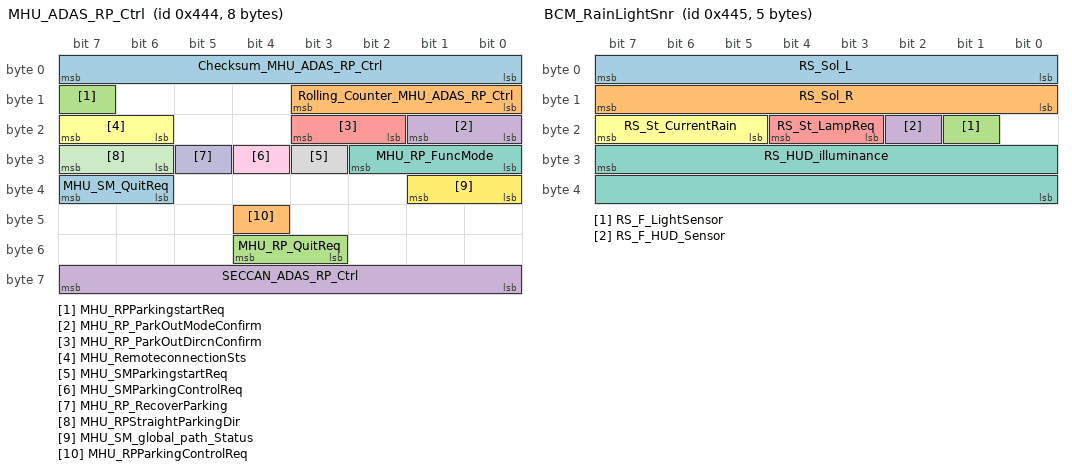
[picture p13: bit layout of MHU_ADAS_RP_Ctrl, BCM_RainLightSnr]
BO_ 1092 MHU_ADAS_RP_Ctrl: 8 MHU
  SG_ Checksum_MHU_ADAS_RP_Ctrl : 7|8@0+ (1,0) [0|255] "" Vector__XXX,PAS_Info
  SG_ Rolling_Counter_MHU_ADAS_RP_Ctrl : 11|4@0+ (1,0) [0|14] "" Vector__XXX,PAS_Info
  SG_ MHU_RPParkingstartReq : 15|1@0+ (1,0) [0|1] "-" Vector__XXX,PAS_Info
  SG_ MHU_RP_ParkOutModeConfirm : 17|2@0+ (1,0) [0|3] "-" Vector__XXX,PAS_Info
  SG_ MHU_RP_ParkOutDircnConfirm : 19|2@0+ (1,0) [0|3] "-" Vector__XXX,PAS_Info
  SG_ MHU_RemoteconnectionSts : 23|2@0+ (1,0) [0|3] "-" Vector__XXX,PAS_Info
  SG_ MHU_RP_FuncMode : 26|3@0+ (1,0) [0|7] "-" Vector__XXX,PAS_Info
  SG_ MHU_SMParkingstartReq : 27|1@0+ (1,0) [0|1] "" Vector__XXX,PAS_Info
  SG_ MHU_SMParkingControlReq : 28|1@0+ (1,0) [0|1] "" Vector__XXX,PAS_Info
  SG_ MHU_RP_RecoverParking : 29|1@0+ (1,0) [0|1] "-" Vector__XXX,PAS_Info
  SG_ MHU_RPStraightParkingDir : 31|2@0+ (1,0) [0|3] "-" Vector__XXX,PAS_Info
  SG_ MHU_SM_global_path_Status : 33|2@0+ (1,0) [0|3] "" Vector__XXX,PAS_Info
  SG_ MHU_SM_QuitReq : 39|2@0+ (1,0) [0|3] "" Vector__XXX,PAS_Info
  SG_ MHU_RPParkingControlReq : 44|1@0+ (1,0) [0|1] "-" Vector__XXX,PAS_Info
  SG_ MHU_RP_QuitReq : 52|2@0+ (1,0) [0|3] "-" Vector__XXX,PAS_Info
  SG_ SECCAN_ADAS_RP_Ctrl : 63|8@0+ (1,0) [0|255] "" Vector__XXX,PAS_Info

BO_ 1093 BCM_RainLightSnr: 5 XGW_Info
  SG_ RS_Sol_L : 7|8@0+ (5,0) [0|1000] "W/m^2" MHU
  SG_ RS_Sol_R : 15|8@0+ (5,0) [0|1000] "W/m^2" MHU
  SG_ RS_F_LightSensor : 17|1@0+ (1,0) [0|1] "" HUD,MHU
  SG_ RS_F_HUD_Sensor : 18|1@0+ (1,0) [0|1] "cd/m2" HUD,MHU
  SG_ RS_St_LampReq : 20|2@0+ (1,0) [0|3] "" MHU
  SG_ RS_St_CurrentRain : 23|3@0+ (1,0) [0|7] "" MHU
  SG_ RS_HUD_illuminance : 31|16@0+ (1,0) [0|10000] "cd/m2" HUD,MHU

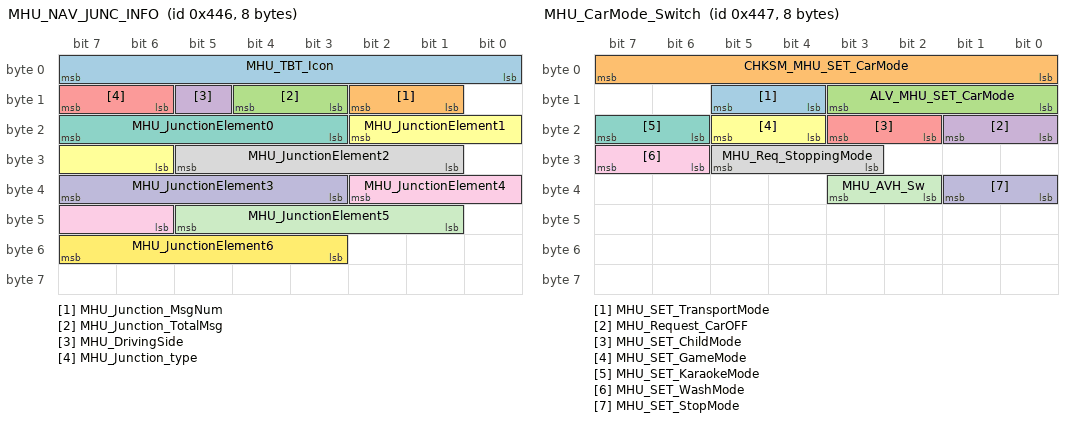
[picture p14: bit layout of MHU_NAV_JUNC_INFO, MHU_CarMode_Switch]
BO_ 1094 MHU_NAV_JUNC_INFO: 8 MHU
  SG_ MHU_TBT_Icon : 7|8@0+ (1,0) [0|255] "-" HUD
  SG_ MHU_Junction_MsgNum : 10|2@0+ (1,0) [0|3] "-" HUD
  SG_ MHU_Junction_TotalMsg : 12|2@0+ (1,0) [0|3] "-" HUD
  SG_ MHU_DrivingSide : 13|1@0+ (1,0) [0|1] "-" HUD
  SG_ MHU_Junction_type : 15|2@0+ (1,0) [0|3] "-" HUD
  SG_ MHU_JunctionElement1 : 18|5@0+ (1,0) [0|31] "-" HUD
  SG_ MHU_JunctionElement0 : 23|5@0+ (1,0) [0|31] "-" HUD
  SG_ MHU_JunctionElement2 : 29|5@0+ (1,0) [0|31] "-" HUD
  SG_ MHU_JunctionElement4 : 34|5@0+ (1,0) [0|31] "-" HUD
  SG_ MHU_JunctionElement3 : 39|5@0+ (1,0) [0|31] "-" HUD
  SG_ MHU_JunctionElement5 : 45|5@0+ (1,0) [0|31] "-" HUD
  SG_ MHU_JunctionElement6 : 55|5@0+ (1,0) [0|31] "-" HUD

BO_ 1095 MHU_CarMode_Switch: 8 MHU
  SG_ MHU_SET_TransportMode : 13|2@0+ (1,0) [0|3] ""  XGW_Info
  SG_ CHKSM_MHU_SET_CarMode : 7|8@0+ (1,0) [0|255] "" XGW_Info,PAS_LITE,PAS_Info
  SG_ ALV_MHU_SET_CarMode : 11|4@0+ (1,0) [0|14] "" XGW_Info,PAS_LITE,PAS_Info
  SG_ MHU_Request_CarOFF : 17|2@0+ (1,0) [0|3] "-" XGW_Info
  SG_ MHU_SET_ChildMode : 19|2@0+ (1,0) [0|3] "" XGW_Info
  SG_ MHU_SET_GameMode : 21|2@0+ (1,0) [0|3] "" XGW_Info
  SG_ MHU_SET_KaraokeMode : 23|2@0+ (1,0) [0|3] "" XGW_Info
  SG_ MHU_Req_StoppingMode : 29|3@0+ (1,0) [0|7] "" XGW_Info
  SG_ MHU_SET_WashMode : 31|2@0+ (1,0) [0|3] "" XGW_Info,PAS_LITE,PAS_Info
  SG_ MHU_SET_StopMode : 33|2@0+ (1,0) [0|3] "" XGW_Info
  SG_ MHU_AVH_Sw : 35|2@0+ (1,0) [0|3] "" XGW_Info

BO_ 1096 EDS_Error_FR_B: 8 XGW_Info
  SG_ CHKSM_EDS_Error_FR_B : 7|8@0+ (1,0) [0|255] "" MHU
  SG_ ALV_EDS_Error_FR_B : 11|4@0+ (1,0) [0|14] "" MHU
  SG_ EDS_iDcLnkOvCLimFail_FWD : 16|1@0+ (1,0) [0|1] "" MHU
  SG_ EDS_MotBlockedFault_FWD : 17|1@0+ (1,0) [0|1] "" MHU
  SG_ EDS_RSLErr_FWD : 18|1@0+ (1,0) [0|1] "" MHU
  SG_ EDS_MotTrqLimFault_FWD : 19|1@0+ (1,0) [0|1] "" MHU
  SG_ EDS_VCUChksumFault_FWD : 20|1@0+ (1,0) [0|1] "" MHU
  SG_ EDS_IGBTFault_FWD : 22|1@0+ (1,0) [0|1] "" MHU
  SG_ EDS_CANBusoffFault_FWD : 23|1@0+ (1,0) [0|1] "" MHU
  SG_ EDS_TDrvBoardOvHiWarn_FWD : 24|1@0+ (1,0) [0|1] "" MHU
  SG_ EDS_TIGBTOvHiFault_FWD : 25|1@0+ (1,0) [0|1] "" MHU
  SG_ EDS_TIGBTOvHiWarn_FWD : 26|1@0+ (1,0) [0|1] "" MHU
  SG_ EDS_IOHWABSampFail_FWD : 27|1@0+ (1,0) [0|1] "" MHU
  SG_ EDS_EDSOpenFault_FWD : 28|1@0+ (1,0) [0|1] "" MHU
  SG_ EDS_MotorOpenFault_FWD : 29|1@0+ (1,0) [0|1] "" MHU
  SG_ EDS_EparkSampFail_FWD : 30|1@0+ (1,0) [0|1] "" MHU
  SG_ EDS_EmacBlkdWarn_FWD : 31|1@0+ (1,0) [0|1] "" MHU
  SG_ EDS_VerMatchFailureErr_FWD : 32|1@0+ (1,0) [0|1] "" MHU
  SG_ EDS_DiashCirNoPsblErr_FWD : 33|1@0+ (1,0) [0|1] "" MHU
  SG_ EDS_OperOutdRngErr_FWD : 34|1@0+ (1,0) [0|1] "" MHU
  SG_ EDS_PhaseLossFaultErr_FWD : 35|1@0+ (1,0) [0|1] "" MHU
  SG_ EDS_CPLDFault_FWD : 36|1@0+ (1,0) [0|1] "" MHU
  SG_ EDS_CPLDFaultBaseSpd_FWD : 37|1@0+ (1,0) [0|1] "" MHU
  SG_ EDS_IOHWABNen33Fail_FWD : 38|1@0+ (1,0) [0|1] "" MHU
  SG_ EDS_HvMcuSlightFault_FWD : 39|1@0+ (1,0) [0|1] "" MHU
  SG_ EDS_HvMcuSevFault_FWD : 40|1@0+ (1,0) [0|1] "" MHU
  SG_ EDS_EDSPhaSampHWFault_FWD : 41|1@0+ (1,0) [0|1] "" MHU
  SG_ EDS_IsOvHiErr_FWD : 42|1@0+ (1,0) [0|1] "" MHU
  SG_ EDS_CanRollingCounterErr_FWD : 43|1@0+ (1,0) [0|1] "" MHU
  SG_ EDS_CanTimeoutErr_FWD : 44|1@0+ (1,0) [0|1] "" MHU
  SG_ EDS_CrashFault_FWD : 45|1@0+ (1,0) [0|1] "" MHU
  SG_ EDS_PCFSlightFault_FWD : 46|1@0+ (1,0) [0|1] "" MHU
  SG_ EDS_PCFSerFault_FWD : 47|1@0+ (1,0) [0|1] "" MHU
  SG_ SECCAN_EDS_Error_FR_B : 63|8@0+ (1,0) [0|255] "" MHU

BO_ 1097 EDS_Error_RR_B: 8 XGW_Info
  SG_ CHKSM_EDS_Error_RR_B : 7|8@0+ (1,0) [0|255] "" MHU
  SG_ ALV_EDS_Error_RR_B : 11|4@0+ (1,0) [0|14] "" MHU
  SG_ EDS_iDcLnkOvCLimFail_RWD : 16|1@0+ (1,0) [0|1] "" MHU
  SG_ EDS_MotBlockedFault_RWD : 17|1@0+ (1,0) [0|1] "" MHU
  SG_ EDS_RSLErr_RWD : 18|1@0+ (1,0) [0|1] "" MHU
  SG_ EDS_MotTrqLimFault_RWD : 19|1@0+ (1,0) [0|1] "" MHU
  SG_ EDS_VCUChksumFault_RWD : 20|1@0+ (1,0) [0|1] "" MHU
  SG_ EDS_IGBTFault_RWD : 22|1@0+ (1,0) [0|1] "" MHU
  SG_ EDS_CANBusoffFault_RWD : 23|1@0+ (1,0) [0|1] "" MHU
  SG_ EDS_TDrvBoardOvHiWarn_RWD : 24|1@0+ (1,0) [0|1] "" MHU
  SG_ EDS_TIGBTOvHiFault_RWD : 25|1@0+ (1,0) [0|1] "" MHU
  SG_ EDS_TIGBTOvHiWarn_RWD : 26|1@0+ (1,0) [0|1] "" MHU
  SG_ EDS_IOHWABSampFail_RWD : 27|1@0+ (1,0) [0|1] "" MHU
  SG_ EDS_EDSOpenFault_RWD : 28|1@0+ (1,0) [0|1] "" MHU
  SG_ EDS_MotorOpenFault_RWD : 29|1@0+ (1,0) [0|1] "" MHU
  SG_ EDS_EparkSampFail_RWD : 30|1@0+ (1,0) [0|1] "" MHU
  SG_ EDS_EmacBlkdWarn_RWD : 31|1@0+ (1,0) [0|1] "" MHU
  SG_ EDS_VerMatchFailureErr_RWD : 32|1@0+ (1,0) [0|1] "" MHU
  SG_ EDS_DiashCirNoPsblErr_RWD : 33|1@0+ (1,0) [0|1] "" MHU
  SG_ EDS_OperOutdRngErr_RWD : 34|1@0+ (1,0) [0|1] "" MHU
  SG_ EDS_PhaseLossFaultErr_RWD : 35|1@0+ (1,0) [0|1] "" MHU
  SG_ EDS_CPLDFault_RWD : 36|1@0+ (1,0) [0|1] "" MHU
  SG_ EDS_CPLDFaultBaseSpd_RWD : 37|1@0+ (1,0) [0|1] "" MHU
  SG_ EDS_IOHWABNen33Fail_RWD : 38|1@0+ (1,0) [0|1] "" MHU
  SG_ EDS_HvMcuSlightFault_RWD : 39|1@0+ (1,0) [0|1] "" MHU
  SG_ EDS_HvMcuSevFault_RWD : 40|1@0+ (1,0) [0|1] "" MHU
  SG_ EDS_EDSPhaSampHWFault_RWD : 41|1@0+ (1,0) [0|1] "" MHU
  SG_ EDS_IsOvHiErr_RWD : 42|1@0+ (1,0) [0|1] "" MHU
  SG_ EDS_CanRollingCounterErr_RWD : 43|1@0+ (1,0) [0|1] "" MHU
  SG_ EDS_CanTimeoutErr_RWD : 44|1@0+ (1,0) [0|1] "" MHU
  SG_ EDS_CrashFault_RWD : 45|1@0+ (1,0) [0|1] "" MHU
  SG_ EDS_PCFSlightFault_RWD : 46|1@0+ (1,0) [0|1] "" MHU
  SG_ EDS_PCFSerFault_RWD : 47|1@0+ (1,0) [0|1] "" MHU

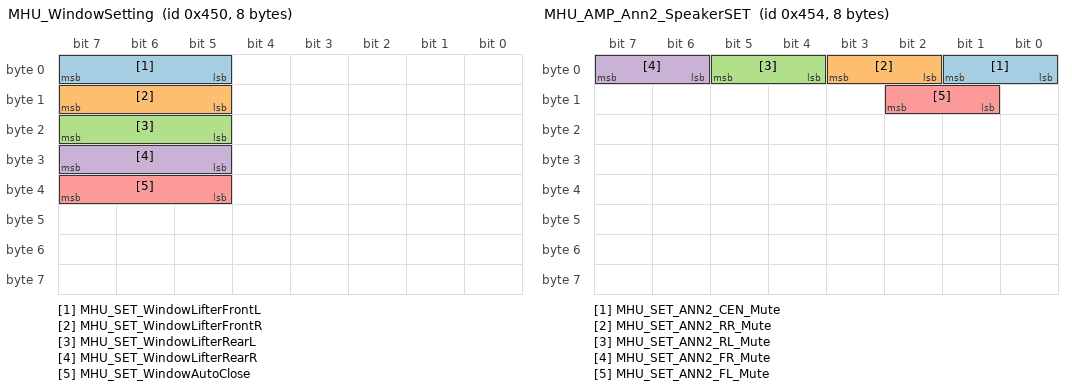
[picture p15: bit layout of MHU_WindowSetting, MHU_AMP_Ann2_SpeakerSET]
BO_ 1104 MHU_WindowSetting: 8 MHU
  SG_ MHU_SET_WindowLifterFrontL : 7|3@0+ (1,0) [0|7] "" XGW_Info
  SG_ MHU_SET_WindowLifterFrontR : 15|3@0+ (1,0) [0|7] "" XGW_Info
  SG_ MHU_SET_WindowLifterRearL : 23|3@0+ (1,0) [0|7] "" XGW_Info
  SG_ MHU_SET_WindowLifterRearR : 31|3@0+ (1,0) [0|7] "" XGW_Info
  SG_ MHU_SET_WindowAutoClose : 39|3@0+ (1,0) [0|3] "" XGW_Info

BO_ 1105 MHU_ADAS_RSSI: 8 MHU
  SG_ Checksum_RSSI : 7|8@0+ (1,0) [0|255] "" Vector__XXX,FCAM_Info
  SG_ Rolling_Counter_RSSI : 11|4@0+ (1,0) [0|14] "" Vector__XXX,FCAM_Info
  SG_ RSSI_Value : 23|8@0+ (1,0) [0|255] "" Vector__XXX,FCAM_Info
  SG_ SECCAN_RSSI : 63|8@0+ (1,0) [0|255] "" Vector__XXX,FCAM_Info

BO_ 1106 MHU_AMP_Ann1_ModeSET: 8 MHU
  SG_ MHU_SET_ANN1_MODE : 7|2@0+ (1,0) [0|3] "" AMP

BO_ 1107 MHU_AMP_Ann1_PromptsSET: 8 MHU
  SG_ MHU_SET_ANN1_PROMPTS_SPEAKER : 7|3@0+ (1,0) [0|6] "" AMP

BO_ 1108 MHU_AMP_Ann2_SpeakerSET: 8 MHU
  SG_ MHU_SET_ANN2_CEN_Mute : 1|2@0+ (1,0) [0|2] "" AMP
  SG_ MHU_SET_ANN2_RR_Mute : 3|2@0+ (1,0) [0|2] "" AMP
  SG_ MHU_SET_ANN2_RL_Mute : 5|2@0+ (1,0) [0|2] "" AMP
  SG_ MHU_SET_ANN2_FR_Mute : 7|2@0+ (1,0) [0|2] "" AMP
  SG_ MHU_SET_ANN2_FL_Mute : 10|2@0+ (1,0) [0|2] "" AMP

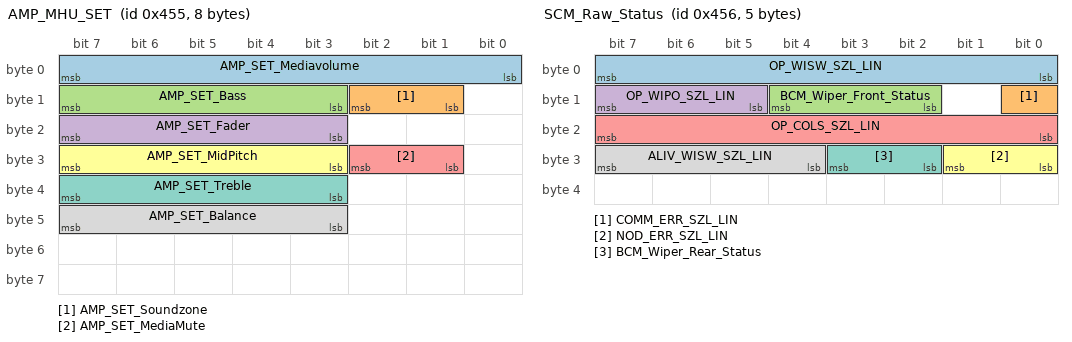
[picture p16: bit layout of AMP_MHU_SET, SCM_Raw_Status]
BO_ 1109 AMP_MHU_SET: 8 AMP
  SG_ AMP_SET_Mediavolume : 7|8@0+ (1,0) [0|40] "-" MHU
  SG_ AMP_SET_Soundzone : 10|2@0+ (1,0) [0|3] "-" MHU
  SG_ AMP_SET_Bass : 15|5@0+ (1,-6) [-6|6] "-" MHU
  SG_ AMP_SET_Fader : 23|5@0+ (1,-10) [-10|10] "-" MHU
  SG_ AMP_SET_MediaMute : 26|2@0+ (1,0) [0|3] "-" MHU
  SG_ AMP_SET_MidPitch : 31|5@0+ (1,-6) [-6|6] "-" MHU
  SG_ AMP_SET_Treble : 39|5@0+ (1,-6) [-6|6] "-" MHU
  SG_ AMP_SET_Balance : 47|5@0+ (1,-10) [-10|10] "-" MHU

BO_ 1110 SCM_Raw_Status: 5 XGW_Info
  SG_ OP_WISW_SZL_LIN : 7|8@0+ (1,0) [0|255] "" HUD,MHU,FCAM_Info
  SG_ COMM_ERR_SZL_LIN : 8|1@0+ (1,0) [0|1] "" HUD,MHU
  SG_ BCM_Wiper_Front_Status : 12|3@0+ (1,0) [0|7] "" HUD,MHU,FCAM_Info
  SG_ OP_WIPO_SZL_LIN : 15|3@0+ (1,0) [0|7] "-" HUD,MHU,FCAM_Info
  SG_ OP_COLS_SZL_LIN : 23|8@0+ (1,0) [0|255] "-" HUD,MHU,FCAM_Info
  SG_ NOD_ERR_SZL_LIN : 25|2@0+ (1,0) [0|3] "" HUD,MHU,FCAM_Info
  SG_ BCM_Wiper_Rear_Status : 27|2@0+ (1,0) [0|3] "" MHU
  SG_ ALIV_WISW_SZL_LIN : 31|4@0+ (1,0) [0|14] "" HUD,MHU,FCAM_Info

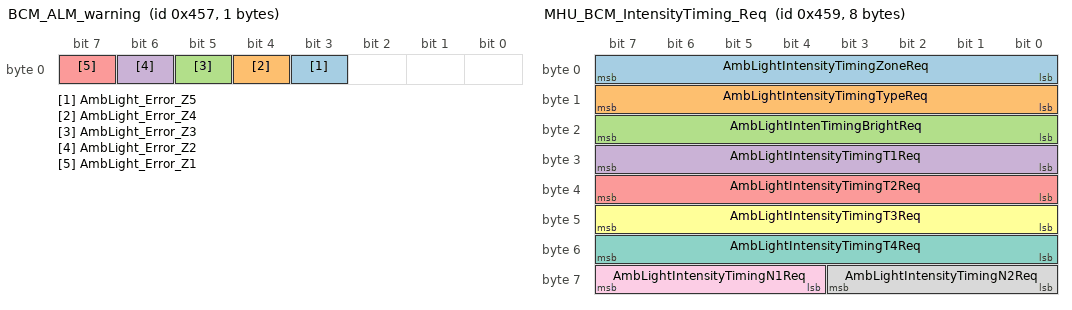
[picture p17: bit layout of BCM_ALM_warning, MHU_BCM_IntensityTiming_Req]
BO_ 1111 BCM_ALM_warning: 1 XGW_Info
  SG_ AmbLight_Error_Z5 : 3|1@0+ (1,0) [0|1] "-" MHU
  SG_ AmbLight_Error_Z4 : 4|1@0+ (1,0) [0|1] "" MHU
  SG_ AmbLight_Error_Z3 : 5|1@0+ (1,0) [0|1] "-" MHU
  SG_ AmbLight_Error_Z2 : 6|1@0+ (1,0) [0|1] "" MHU
  SG_ AmbLight_Error_Z1 : 7|1@0+ (1,0) [0|1] "" MHU

BO_ 1115 ADAS_HOD: 8 FCAM_Info
 SG_ HOD_steering_wheel_type : 5|4@0+ (1,0) [0|15] ""  XGW_Info
 SG_ HOD_vehicle_type : 15|8@0+ (1,0) [0|255] ""  XGW_Info
 SG_ ADAS_HOD_state_requesting : 57|2@0+ (1,-0) [0|3] ""  XGW_Info

BO_ 1112 MHU_BCM_Color_Req: 8 MHU
  SG_ AmbLightColorZoneReq : 7|8@0+ (1,0) [0|31] "-" XGW_Info
  SG_ AmbLightColorRed : 15|8@0+ (1,0) [0|255] "" XGW_Info
  SG_ AmbLightColorGreen : 23|8@0+ (1,0) [0|255] "-" XGW_Info
  SG_ AmbLightColorBlue : 31|8@0+ (1,0) [0|255] "-" XGW_Info
  SG_ SECCAN_BCM_Clr_Rq : 63|8@0+ (1,0) [0|255] "" XGW_Info

BO_ 1113 MHU_BCM_IntensityTiming_Req: 8 MHU
  SG_ AmbLightIntensityTimingZoneReq : 7|8@0+ (1,0) [0|31] "" XGW_Info
  SG_ AmbLightIntensityTimingTypeReq : 15|8@0+ (1,0) [0|5] "" XGW_Info
  SG_ AmbLightIntenTimingBrightReq : 23|8@0+ (1,0) [0|100] "" XGW_Info
  SG_ AmbLightIntensityTimingT1Req : 31|8@0+ (0.1,0) [0|25.5] "s" XGW_Info
  SG_ AmbLightIntensityTimingT2Req : 39|8@0+ (0.1,0) [0|25.5] "s" XGW_Info
  SG_ AmbLightIntensityTimingT3Req : 47|8@0+ (0.1,0) [0|25.5] "s" XGW_Info
  SG_ AmbLightIntensityTimingT4Req : 55|8@0+ (0.1,0) [0|25.5] "s" XGW_Info
  SG_ AmbLightIntensityTimingN2Req : 59|4@0+ (1,0) [0|15] "-" XGW_Info
  SG_ AmbLightIntensityTimingN1Req : 63|4@0+ (1,0) [0|15] "" XGW_Info

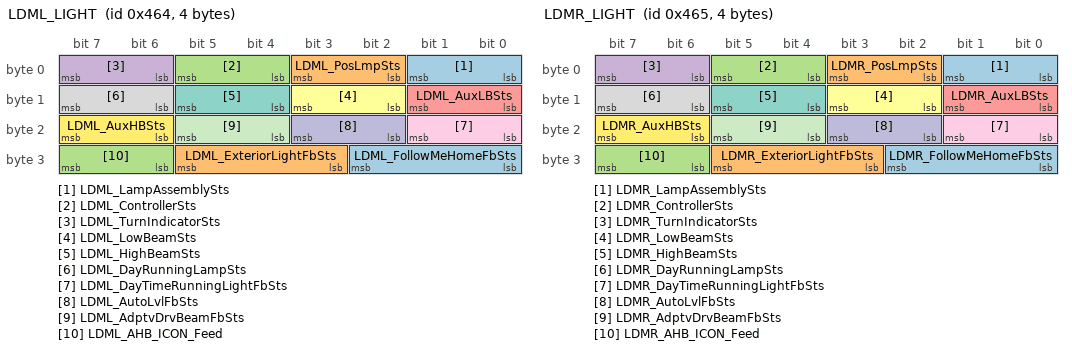
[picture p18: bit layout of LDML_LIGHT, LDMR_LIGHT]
BO_ 1124 LDML_LIGHT: 4 XGW_Info
  SG_ LDML_LampAssemblySts : 1|2@0+ (1,0) [0|3] "-" HUD,MHU
  SG_ LDML_PosLmpSts : 3|2@0+ (1,0) [0|3] "" HUD,MHU
  SG_ LDML_ControllerSts : 5|2@0+ (1,0) [0|3] "" HUD,MHU
  SG_ LDML_TurnIndicatorSts : 7|2@0+ (1,0) [0|3] "" HUD,MHU
  SG_ LDML_AuxLBSts : 9|2@0+ (1,0) [0|3] "-" HUD,MHU
  SG_ LDML_LowBeamSts : 11|2@0+ (1,0) [0|3] "-" HUD,MHU
  SG_ LDML_HighBeamSts : 13|2@0+ (1,0) [0|3] "" HUD,MHU
  SG_ LDML_DayRunningLampSts : 15|2@0+ (1,0) [0|3] "" HUD,MHU
  SG_ LDML_DayTimeRunningLightFbSts : 17|2@0+ (1,0) [0|3] "" HUD,MHU
  SG_ LDML_AutoLvlFbSts : 19|2@0+ (1,0) [0|3] "" HUD,MHU
  SG_ LDML_AdptvDrvBeamFbSts : 21|2@0+ (1,0) [0|3] "-" HUD,MHU
  SG_ LDML_AuxHBSts : 23|2@0+ (1,0) [0|3] "-" HUD,MHU
  SG_ LDML_FollowMeHomeFbSts : 26|3@0+ (1,0) [0|5] "-" HUD,MHU
  SG_ LDML_ExteriorLightFbSts : 29|3@0+ (1,0) [0|4] "-" HUD,MHU
  SG_ LDML_AHB_ICON_Feed : 31|2@0+ (1,0) [0|3] "" HUD,MHU

BO_ 1125 LDMR_LIGHT: 4 XGW_Info
  SG_ LDMR_LampAssemblySts : 1|2@0+ (1,0) [0|3] "" HUD,MHU
  SG_ LDMR_PosLmpSts : 3|2@0+ (1,0) [0|3] "-" HUD,MHU
  SG_ LDMR_ControllerSts : 5|2@0+ (1,0) [0|3] "" HUD,MHU
  SG_ LDMR_TurnIndicatorSts : 7|2@0+ (1,0) [0|3] "-" HUD,MHU
  SG_ LDMR_AuxLBSts : 9|2@0+ (1,0) [0|3] "-" HUD,MHU
  SG_ LDMR_LowBeamSts : 11|2@0+ (1,0) [0|3] "-" HUD,MHU
  SG_ LDMR_HighBeamSts : 13|2@0+ (1,0) [0|3] "" HUD,MHU
  SG_ LDMR_DayRunningLampSts : 15|2@0+ (1,0) [0|3] "" HUD,MHU
  SG_ LDMR_DayTimeRunningLightFbSts : 17|2@0+ (1,0) [0|3] "-" HUD,MHU
  SG_ LDMR_AutoLvlFbSts : 19|2@0+ (1,0) [0|3] "-" HUD,MHU
  SG_ LDMR_AdptvDrvBeamFbSts : 21|2@0+ (1,0) [0|3] "" HUD,MHU
  SG_ LDMR_AuxHBSts : 23|2@0+ (1,0) [0|3] "-" HUD,MHU
  SG_ LDMR_FollowMeHomeFbSts : 26|3@0+ (1,0) [0|5] "" HUD,MHU
  SG_ LDMR_ExteriorLightFbSts : 29|3@0+ (1,0) [0|4] "-" HUD,MHU
  SG_ LDMR_AHB_ICON_Feed : 31|2@0+ (1,0) [0|3] "" HUD,MHU

BO_ 1136 AMP_MHU_Ann1_ModeSET: 8 AMP
  SG_ AMP_SET_ANN1_MODE : 15|2@0+ (1,0) [0|3] "" MHU

BO_ 1137 AMP_MHU_Ann1_PromptsSET: 8 AMP
  SG_ AMP_SET_ANN1_PROMPTS_SPEAKER : 13|3@0+ (1,0) [0|6] "" MHU

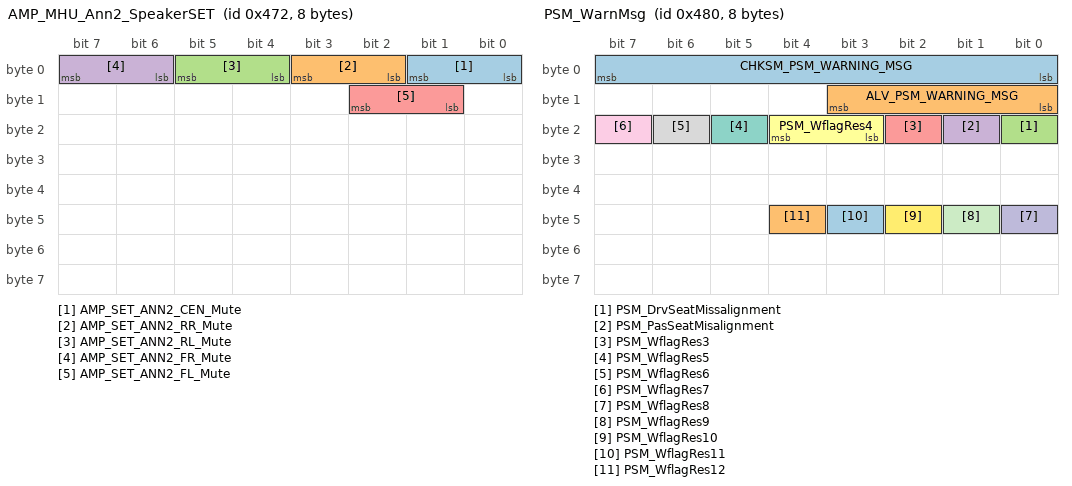
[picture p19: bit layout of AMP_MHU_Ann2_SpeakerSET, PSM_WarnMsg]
BO_ 1138 AMP_MHU_Ann2_SpeakerSET: 8 AMP
  SG_ AMP_SET_ANN2_CEN_Mute : 1|2@0+ (1,0) [0|3] "" MHU
  SG_ AMP_SET_ANN2_RR_Mute : 3|2@0+ (1,0) [0|3] "" MHU
  SG_ AMP_SET_ANN2_RL_Mute : 5|2@0+ (1,0) [0|3] "" MHU
  SG_ AMP_SET_ANN2_FR_Mute : 7|2@0+ (1,0) [0|3] "" MHU
  SG_ AMP_SET_ANN2_FL_Mute : 10|2@0+ (1,0) [0|3] "" MHU

BO_ 1152 PSM_WarnMsg: 8 XGW_Info
  SG_ CHKSM_PSM_WARNING_MSG : 7|8@0+ (1,0) [0|255] "" MHU
  SG_ ALV_PSM_WARNING_MSG : 11|4@0+ (1,0) [0|14] "" MHU
  SG_ PSM_DrvSeatMissalignment : 16|1@0+ (1,0) [0|1] "" MHU
  SG_ PSM_PasSeatMisalignment : 17|1@0+ (1,0) [0|1] "Bit" MHU
  SG_ PSM_WflagRes3 : 18|1@0+ (1,0) [0|1] "Bit" MHU
  SG_ PSM_WflagRes4 : 20|2@0+ (1,0) [0|3] "Bit" MHU
  SG_ PSM_WflagRes5 : 21|1@0+ (1,0) [0|1] "-" MHU
  SG_ PSM_WflagRes6 : 22|1@0+ (1,0) [0|1] "-" MHU
  SG_ PSM_WflagRes7 : 23|1@0+ (1,0) [0|1] "-" MHU
  SG_ PSM_WflagRes8 : 40|1@0+ (1,0) [0|1] "" MHU
  SG_ PSM_WflagRes9 : 41|1@0+ (1,0) [0|1] "" MHU
  SG_ PSM_WflagRes10 : 42|1@0+ (1,0) [0|1] "-" MHU
  SG_ PSM_WflagRes11 : 43|1@0+ (1,0) [0|1] "-" MHU
  SG_ PSM_WflagRes12 : 44|1@0+ (1,0) [0|1] "-" MHU

CM_ BO_ 1030 "MHU Seat Vent Heat";
CM_ BO_ 1032 "MHU Comfort Setting";
CM_ BO_ 1034 "MHU HudSetting";
CM_ BO_ 1035 "MHU Avas Setting";
CM_ BO_ 1036 "MHU_SEAT_CONTROL";
CM_ BO_ 1037 "Display Vehicle speed CAN Signal sent by MHU";
CM_ BO_ 1038 "IC BORD COMP TRIP B";
CM_ BO_ 1039 "IC BORD COMP TRIP B";
CM_ BO_ 1040 "IC_BORD_COMP_TRIP_Auto";
CM_ BO_ 1043 "FCAM Sensor_Fault";
CM_ BO_ 1044 "HOD_status";
CM_ BO_ 1046 "BCM Mirror Confirm Sts";
CM_ BO_ 1049 "SHVU F Confirm Sts";
CM_ BO_ 1050 "SHVU R Confirm Sts";
CM_ BO_ 1052 "PSM seat position";
CM_ BO_ 1053 "BCM Comfortable Confirm status";
CM_ BO_ 1054 "HUD State feedback";
CM_ BO_ 1055 "PAS Sensor_Fault";
CM_ BO_ 1058 "MHU Status";
CM_ BO_ 1059 "AVAS STATUS";
CM_ BO_ 1064 "TRM fitted status and keyfob left the car warning";
CM_ BO_ 1068 "PSM Control Status";
CM_ BO_ 1069 "Information collected by XGW";
CM_ BO_ 1070 "XGW send this message for pitch angle";
CM_ BO_ 1073 "HUD ECU Status";
CM_ BO_ 1074 "MHU_FOTA_STATUS";
CM_ BO_ 1075 "MHU_HEADLAMP_CTL";
CM_ BO_ 1077 "Information transmit from SCM to BCM to CAN Network";
CM_ BO_ 1078 "The communication between MHU and HUC";
CM_ BO_ 1079 "VCU MHU Information";
CM_ BO_ 1080 "MCU Front Error";
CM_ BO_ 1081 "MCU Rear Error";
CM_ BO_ 1082 "VCU MHU Information";
CM_ BO_ 1083 "MHU Steering Adjust";
CM_ BO_ 1084 "EASC Confirm Status";
CM_ BO_ 1086 "MHU_Amplifier Set Info";
CM_ BO_ 1087 "MHU_Amplifier EQType";
CM_ BO_ 1088 "Amplifier MHU  EQType";
CM_ BO_ 1090 "Wireless Charge Status";
CM_ BO_ 1091 "Wireless Charge Status 2";
CM_ BO_ 1092 "MHU ADAS RP Control status ";
CM_ BO_ 1093 "Rain light sensor";
CM_ BO_ 1094 "Junction element ";
CM_ BO_ 1095 "MHU_CarMode_Switch";
CM_ BO_ 1096 "MCU Front Error";
CM_ BO_ 1097 "MCU Rear Error";
CM_ BO_ 1104 "MHU Window Setting";
CM_ BO_ 1105 "ADAS RSSI Value";
CM_ BO_ 1106 "MHU_AMP_Ann1_ModeSET";
CM_ BO_ 1107 "MHU_AMP_Ann1_PromptsSET";
CM_ BO_ 1108 "MHU_AMP_Ann2_SpeakerSET";
CM_ BO_ 1109 "Amplifier MHU  Set Info";
CM_ BO_ 1110 "SCM_Raw_Status";
CM_ BO_ 1111 "BCM_ALM_warning";
CM_ BO_ 1112 "MHU_BCM_Color_Req";
CM_ BO_ 1113 "MHU_BCM_IntensityTiming_Req";
CM_ BO_ 1115 "ADAS_HOD_state_requesting";
CM_ BO_ 1124 "LDM_L Light Status";
CM_ BO_ 1125 "LDM_R Light Status";
CM_ BO_ 1136 "AMP_MHU_Ann1_ModeSET";
CM_ BO_ 1137 "AMP_MHU_Ann1_PromptsSET";
CM_ BO_ 1138 "AMP_MHU_Ann2_SpeakerSET";
CM_ BO_ 1152 "PSM WarnMsg";
CM_ SG_ 1030 MHU_SET_SeatHeatingFrontL "Change seat heating with 3 level";
CM_ SG_ 1030 MHU_SET_SeatHeatingFrontR "Change seat heating with 3 level";
CM_ SG_ 1030 MHU_SET_SeatHeatingReartL "Change seat heating with 3 level";
CM_ SG_ 1030 MHU_SET_SeatHeatingRearR "Change seat heating with 3 level";
CM_ SG_ 1030 MHU_SET_SeatCoolingFrontL "Change seat cooling with 3 level";
CM_ SG_ 1030 MHU_SET_SeatCoolingFrontR "Change seat cooling with 3 level";
CM_ SG_ 1030 MHU_SET_SeatCoolingRearL "Change seat cooling with 3 level";
CM_ SG_ 1030 MHU_SET_SeatCoolingRearR "Change seat cooling with 3 level";
CM_ SG_ 1032 MHU_SET_MirrorAuto "Change mirror auto mode";
CM_ SG_ 1032 MHU_SET_MirrorAutoUnfold "setting Mirror Auto unfold mode";
CM_ SG_ 1032 MHU_SET_WLC "On Off wireless charger";
CM_ SG_ 1032 MHU_SET_AutoRearWiper "On Off Auto rear wiper";
CM_ SG_ 1032 MHU_SET_RearHeatedWindow "On Off Rear window heating";
CM_ SG_ 1032 MHU_TPMSReset "Request reset the TPMS";
CM_ SG_ 1032 MHU_SET_MirrorDefaultSetting "Trigger the default Mirror setting";
CM_ SG_ 1032 MHU_SET_MirrorReverseLink "Mirror Auto Tilt On Reverse Mode";
CM_ SG_ 1032 MHU_SET_AntiTheftMode "setting Anti-theft mode ";
CM_ SG_ 1032 MHU_SET_WLCReminder "On Off WLC reminder";
CM_ SG_ 1032 MHU_SET_ClimateKeepOn "Keep power for climate PET/CAMP mode";
CM_ SG_ 1032 MHU_SET_WLC2 "On Off wireless charger rear";
CM_ SG_ 1032 MHU_SET_WLC2Reminder "On Off WLC rear reminder";
CM_ SG_ 1032 MHU_IntrusionAlertStatus "Detection of Intrusion Alert in the MHU";
CM_ SG_ 1034 MHU_SET_HudUIContent "Set HUD content";
CM_ SG_ 1034 MHU_SET_HudTurnSigOnOff "Turn On/Off TurnSignal’s display on HUD";
CM_ SG_ 1034 MHU_SET_HudBSDOnOff  "Turn On/Off BSD’s display on HUD";
CM_ SG_ 1034 MHU_SET_HudRCTAOnOff "Turn On/Off RCTA’s display on HUD";
CM_ SG_ 1034 MHU_SET_HudUIColor "Set the HUD UI Color";
CM_ SG_ 1034 MHU_SET_HudScreenOnOFF "On Off HUD screen";
CM_ SG_ 1034 MHU_SET_UserBrightnessLvl "Set the HUD brightness";
CM_ SG_ 1034 MHU_SET_HudWorkingMode "Set HUD working mode: Normal mode or Position adjustment mode";
CM_ SG_ 1034 MHU_SET_HudUISize "Set the HUD UI Size";
CM_ SG_ 1034 MHU_SET_UIContentMediaInfo "Set ON/OFF HUD UI content for Radio/Media information";
CM_ SG_ 1034 MHU_SET_UIContentCallInfo "Set ON/OFF HUD UI Content for Incomming call information";
CM_ SG_ 1034 MHU_SET_UIContentPoweRegen "Set ON/OFF HUD UI Content for Power Regen gauge";
CM_ SG_ 1035 MHU_SET_AvasSound "Change the Engine Sound Volume";
CM_ SG_ 1036 CHSKM_MHU_SEAT_CONTROL "Checksum";
CM_ SG_ 1036 ALV_MHU_SEAT_CONTROL "Alive Counter";
CM_ SG_ 1036 MHU_DrvSeat_Control_Status "MHU driver seat control status";
CM_ SG_ 1036 MHU_ExpDrvReclinerPos "Expected recliner position of driver seat requested by MHU";
CM_ SG_ 1036 MHU_ExpDrvTiltPos "Expected tilt position of driver seat requested by MHU";
CM_ SG_ 1036 MHU_ExpDrvTrackPos "Expected track position of driver seat requested by MHU";
CM_ SG_ 1036 MHU_ExpDrvHeightPos "Expected height position of driver seat requested by MHU";
CM_ SG_ 1037 CHKSM_MHU_DIGIT_SPEED "Checksum";
CM_ SG_ 1037 ALV_MHU_DIGIT_SPEED "Alive Counter";
CM_ SG_ 1037 MHU_DigitSpeed "This signal represents the digital speed and is displayed; values between 301 and 511 are invalid.";
CM_ SG_ 1038 AveragePwrConsumpTripA "Average Power consumption for trip A, Max value ";
CM_ SG_ 1038 AverageFuelConsumpTripA "Average Fuel consumption for Trip A, Max value 51";
CM_ SG_ 1038 AvarageSpeedTripA "Average speed information for trip A; values between 301 and 511 are invalid.";
CM_ SG_ 1038 TripA "Information for trip A; values between 10001 and 13107.1 are invalid";
CM_ SG_ 1039 AveragePwrConsumpTripB "Average Power consumption for trip B, Max value ";
CM_ SG_ 1039 AverageFuelConsumpTripB "Average Fuel consumption for Trip B, Max value 51";
CM_ SG_ 1039 AvarageSpeedTripB "Average speed information for trip B; values between 301 and 511 are invalid.";
CM_ SG_ 1039 TripB "Information for trip B; values between 10001 and 13107.1 are invalid";
CM_ SG_ 1040 AveragePwrConsumpTripAuto "Average Power consumption for trip Auto, Max value ";
CM_ SG_ 1040 AverageFuelConsumpTripAuto "Average Fuel consumption for Trip Auto, Max value 51";
CM_ SG_ 1040 AvarageSpeedTripAuto "Average speed information for trip Auto; values between 301 and 511 are invalid.";
CM_ SG_ 1040 TripAuto "Information for trip Auto; values between 10001 and 13107.1 are invalid";
CM_ SG_ 1042 eCall_state "eCall Status.";
CM_ SG_ 1043 CHKSM_FCAM_SensorFault "Checksum";
CM_ SG_ 1043 ALV_FCAM_Sensor_Fault "Alive counter";
CM_ SG_ 1043 FCAM_SRR_RR_Fault "This signal to indicate Rear Right SRR error";
CM_ SG_ 1043 FCAM_SCAM_Fault "This signal to indicate SCAM/FCAM error";
CM_ SG_ 1043 FCAM_SRR_FR_Fault "This signal to indicate Front Right SRR error";
CM_ SG_ 1043 FCAM_MRR_Fault "This signal to indicate MRR error";
CM_ SG_ 1043 FCAM_SRR_RL_Fault "This signal to indicate Rear Left SRR error";
CM_ SG_ 1043 FCAM_SRR_FL_Fault "This signal to indicate Front Left SRR error";
CM_ SG_ 1043 SECCAN_FCAM_SensorFault "Seed generated from Secure CAN algorithm";
CM_ SG_ 1044 CRC_SW_1 "This signal includes a CRC checksum value which has for purpose of securing the communication path end to end (E2E).";
CM_ SG_ 1044 Message_Counter_SW_1 "This signal includes a counter value which has for purpose of securing the communication path end to end (E2E).";
CM_ SG_ 1044 Calc_Threshold "The signal represents the calculated threshold value for the hands-off detection.";
CM_ SG_ 1044 Real_Impedence "The signal represents the currently measured real part value";
CM_ SG_ 1044 Immag_Impedence "The signal represents the currently measured imaginary part value.";
CM_ SG_ 1044 ERR_ST_HOD "The signal includes the error information of the HOD.";
CM_ SG_ 1044 RsErr_HOD "The signal represents the standard communication error bit as specified in the LIN protocol.";
CM_ SG_ 1044 HOD_status "The signal includes the information, whether the driver touches the steering wheel or not.";
CM_ SG_ 1046 CHKSM_BCM_STAT_Mirror "Checksum";
CM_ SG_ 1046 ALV_BCM_STAT_Mirror "Alive Counter";
CM_ SG_ 1046 BCM_STAT_LeftMirrorPosX "Set left mirror left right position";
CM_ SG_ 1046 BCM_STAT_LeftMirrorPosY "Set left mirror up/down position";
CM_ SG_ 1046 BCM_STAT_RightMirrorPosX "Set right mirror left right position";
CM_ SG_ 1046 BCM_STAT_RightMirrorPosY "Set right mirror up down position";
CM_ SG_ 1046 BCM_STAT_Mirror "Represent the status of Mirror Fold/Unfold";
CM_ SG_ 1046 BCM_STAT_MirrorAdjustLeft "Enter setting Mirror position mode";
CM_ SG_ 1046 BCM_STAT_MirrorAdjustRight "Enter setting Mirror position mode";
CM_ SG_ 1049 SHVU_STAT_SeatHeatingFrontL "Change Seat heating with 3 level";
CM_ SG_ 1049 SHVU_STAT_SeatHeatingFrontR "Change Seat heating with 3 level";
CM_ SG_ 1049 SHVU_STAT_SeatCoolingFrontL "Change Seat cooling with 3 level";
CM_ SG_ 1049 SHVU_STAT_SeatCoolingFrontR "Change Seat cooling with 3 level";
CM_ SG_ 1049 SHVU_STAT_FrontSeatVentSts "Indicate current status of front seat ventilation system";
CM_ SG_ 1050 SHVU_STAT_SeatCoolingRearL "Change Seat cooling with 3 level";
CM_ SG_ 1050 SHVU_STAT_SeatCoolingRearR "Change Seat cooling with 3 level";
CM_ SG_ 1050 SHVU_STAT_SeatHeatingReartL "Change Seat heating with 3 level";
CM_ SG_ 1050 SHVU_STAT_SeatHeatingRearR "Change Seat heating with 3 level";
CM_ SG_ 1050 SHVU_STAT_RearSeatVentSts "Indicate current status of rear seat ventilation system";
CM_ SG_ 1052 CHKSM_PSM_SEAT_POSITION "Checksum";
CM_ SG_ 1052 AVL_PSM_SEAT_POSITION "Alive Counter";
CM_ SG_ 1052 PSM_Seat_track_pos_Dri "PSM Seat track position driver";
CM_ SG_ 1052 PSM_Seat_track_posPas "PSM Seat track position front passenger";
CM_ SG_ 1053 BCM_STAT_AutoRearWiper "On/Off Auto rear wiper";
CM_ SG_ 1053 BCM_STAT_MirrorFoldSetting "Status MirrorFold Default value =  0x1 Auto Fold ON/Invalid value = 3";
CM_ SG_ 1053 BCM_STAT_IMMO_KeyfobID2 "console as per request of a MHU to link keyfob to a profile - improvement signal";
CM_ SG_ 1053 BCM_STAT_MirrorAutoUnfold "Change Mirror Auto unfold mode";
CM_ SG_ 1053 BCM_STAT_MirrorReverseLink "Mirror Auto Tilt On Reverse Feedback";
CM_ SG_ 1053 BCM_STAT_MirrorDefaultSTATting "Trigger the default Mirror setting";
CM_ SG_ 1053 BCM_STAT_WelcomeTriggerCondition "Confirm Welcome trigger condition";
CM_ SG_ 1053 BCM_STAT_FrontDomeLamp "Confirm setting On/Off/Auto Front Dome Lamp";
CM_ SG_ 1053 BCM_STAT_FollowMeHome "Change follow me home headlamp mode and delay";
CM_ SG_ 1053 BCM_STAT_ExteriorLight "Change Exterior light mode";
CM_ SG_ 1053 BCM_STAT_RemoteLockFeedback "Remote Lock dback: customer can choose light feedback when lock the door with remote key";
CM_ SG_ 1053 BCM_STAT_RemoteDoorUnlock "Settings for Door lock unlock conditions";
CM_ SG_ 1053 BCM_STAT_AutoDoorUnlock "Auto door unlock: When the car is stopped and the shift lever is in ?P? position, selected doors will be unlocked automatically";
CM_ SG_ 1053 BCM_STAT_WalkawayDoorLock "Walk away lock State";
CM_ SG_ 1053 BCM_STAT_AmbientLightBrighness "Change Ambient light brighness percent";
CM_ SG_ 1053 BCM_STAT_WiperServiceMode "console as per request of a MHU to link keybof to a";
CM_ SG_ 1053 BCM_STAT_IMMO_KeyfobID "console as per request of a MHU to link keybof to a";
CM_ SG_ 1053 BCM_STAT_RearHeatedWindowMirror "This signal is necessary for the activation or deactivation of the rear screen heating for the rear window and the mirrors.Invalid value = 3";
CM_ SG_ 1053 BCM_STAT_AntiTheftMode "Confirm of setting Anti-theft mode ";
CM_ SG_ 1053 BCM_STAT_ClimateKeepOnSts "Climate keep ON feedback status
";
CM_ SG_ 1053 BCM_STAT_FKSfeedback "BCM_STAT_FKSfeedback";
CM_ SG_ 1053 SECCAN_CmftCnfrm "Secret portion from Secure CAN algorithm";
CM_ SG_ 1054 HUD_UIColor "HUD Icon Text color";
CM_ SG_ 1054 HUD_UIContent "HUD Content";
CM_ SG_ 1054 HUD_OperationState "Operation state of HUD";
CM_ SG_ 1054 HUD_HeightLvl "HUD height level ";
CM_ SG_ 1054 HUD_UI_Size "HUD UI Size";
CM_ SG_ 1054 HUD_UIContentMediaInfo "ON/OFF status of Incomming call information in HUD UI Content";
CM_ SG_ 1054 HUD_UIContentCallInfor "ON/OFF status of Incomming call information in HUD UI Content";
CM_ SG_ 1054 HUD_UIContentPowerRegen "ON/OFF status of Power Regen in HUD UI Content";
CM_ SG_ 1054 HUD_UIModeSignal "Driver display drive mode status ";
CM_ SG_ 1054 HUD_WorkingMode "Flag to confirm HUD is in User config mode to change Position, rotation";
CM_ SG_ 1054 HUD_ActualBrightnes "HUD actual brightness value by nit . AutoLvl: Decided by light sensor.";
CM_ SG_ 1054 HUD_RotateAngleLvl "Rotation Angle Level of HUD";
CM_ SG_ 1054 HUD_UserSetBrightnessLvl "User set brightness level ";
CM_ SG_ 1054 HUD_Language "Current HUD language";
CM_ SG_ 1054 HUD_TurnSigOnOff_Feed "HUD Feedback TurnSignal ON/OFF to MHU";
CM_ SG_ 1054 HUD_BSDOnOff_Feed "HUD Feedback BSD ON/OFF to MHU";
CM_ SG_ 1054 HUD_RCTAOnOff_Feed "HUD Feedback RCTA ON/OFF to MHU";
CM_ SG_ 1054 HUD_Mileage_Unit "Current HUD Milage unit";
CM_ SG_ 1054 HUD_UserProfileId "Current HUD Userprofile ID, HUD supports up to 10 user profiles, 0xF is invalid signal";
CM_ SG_ 1054 HUD_DimmingDelayTime "calibration parameters of time in second, to smooth/delay the HUD dimming control base on road/light condition";
CM_ SG_ 1055 CHKSM_PAS_SensorFault "Checksum.";
CM_ SG_ 1055 ALV_PAS_Sensor_Fault "Alive counter.";
CM_ SG_ 1055 PAS_SVM_LCamera_Fault "This signal to indicate Left SVM Camera error.";
CM_ SG_ 1055 PAS_SVM_FCamera_Fault "This signal to indicate Front SVM Camera error.";
CM_ SG_ 1055 SECCAN_PAS_SensorFault "Seed generated from Secure CAN algorithm.";
CM_ SG_ 1055 PAS_SVM_RCamera_Fault "This signal to indicate Rear SVM Camera error.";
CM_ SG_ 1055 PAS_SVM_RightCamera_Fault "This signal to indicate Right SVM Camera error.";
CM_ SG_ 1058 CHKSM_MHU_STAT "Checksum";
CM_ SG_ 1058 ALV_MHU_STAT "Alive Counter";
CM_ SG_ 1058 MHU_STAT_Cluster "State of Cluster screen for serving Fail-save mode";
CM_ SG_ 1058 MHU_STAT_Infotainment "State of Infotainment screen for serving Fail-save mode";
CM_ SG_ 1058 MHU_STAT_MileageUnit "Indicate current unit of mileage display in Screen (Km or Miles)";
CM_ SG_ 1058 MHU_STAT_PressureUnit "Indicate current unit of Pressure(psi, Bar, kPa)";
CM_ SG_ 1058 MHU_STAT_TemperatureUnit "Indicate current unit of Temperature (C, F)";
CM_ SG_ 1058 MHU_STAT_DateTimeFormat "Indicate current date time format (12H and 24H)";
CM_ SG_ 1058 MHU_Operation_State "Operation state of MHU
";
CM_ SG_ 1058 MHU_STAT_Language "Indicate current Language";
CM_ SG_ 1058 MHU_STAT_EnergyConsumptionUnit "Indicate current unit of Enery Consumption (KWH per 100Km)";
CM_ SG_ 1058 BAS_version "BAS version";
CM_ SG_ 1058 MHU_STAT_SaleCountry "Current Sale Country by Map engine - encode by ISO 3166-1 numeric";
CM_ SG_ 1058 MHU_STAT_BatLvlPopsetting "MHU_STAT_BatLvlPopsetting";
CM_ SG_ 1058 MHU_STAT_DistToEmptyUnit "Battery unit";
CM_ SG_ 1059 AVAS_BatteryUnderVoltage "Battery voltage below threshold
";
CM_ SG_ 1059 AVAS_BatteryOverVoltage "Battery voltage over threshold
";
CM_ SG_ 1059 AVAS_VINInfoNotPrgm "VIN code is not saved";
CM_ SG_ 1059 AVAS_AMPVoltSplDrvOperationFail "AMP voltage supply drive operation fail
";
CM_ SG_ 1059 AVAS_AMPIntFaultOverCurr "Amplifier internal overcurrent fail";
CM_ SG_ 1059 AVAS_AMPInternalFaultDCError "Amplifier internal DC fault";
CM_ SG_ 1059 AVAS_AMPInternalFaultOverTemp "Amplifier internal over-temperature fault";
CM_ SG_ 1059 AVAS_AMPInternalFaultClockError "Amplifier internal clock fault
";
CM_ SG_ 1059 AVAS_SpkrMntPwrSwDrvHighFlt "Speaker monitor power switch drive high fault
";
CM_ SG_ 1059 AVAS_SpkrMntPwrSwDrvLowFlt "speaker power switch drive low fault
";
CM_ SG_ 1059 AVAS_InternalSpeakerOpen "Internal speaker open";
CM_ SG_ 1059 AVAS_ECUMalFlshOperationErr "ECU malfunction : flash operation error";
CM_ SG_ 1059 AVAS_ECUMalfunctionRamFailure "ECU malfunction : RAM failure
";
CM_ SG_ 1059 AVAS_ECUMalEEPROMFailure "EEPROM operation fail";
CM_ SG_ 1059 AVAS_CANBusOff "CAN Bus off
";
CM_ SG_ 1059 AVAS_LossCommVehicleSpeed "Loss Communication with vehicle speed signal";
CM_ SG_ 1059 AVAS_LossCommGearPosition "Loss Communication with gear position signal";
CM_ SG_ 1059 AVAS_LossCommAVASCloseCmd "Loss Communication with avas close command signal";
CM_ SG_ 1064 TRMFitted "Signal indicating that TRM is fitted or not. Signal is copy of H16 parameter in the VOD setting withing XGW";
CM_ SG_ 1068 CHSKM_PSM_D_SEAT_CONTROL "Checksum";
CM_ SG_ 1068 ALV_PSM_D_SEAT_CONTROL "Alive Counter";
CM_ SG_ 1068 PSM_D_DrvSeat_Control_Status "PSM_D driver seat control status";
CM_ SG_ 1068 PSM_D_DrvReclinerPos "Current recliner position of driver seat";
CM_ SG_ 1068 PSM_D_DrvTiltPos "Current tilt position of driver seat";
CM_ SG_ 1068 PSM_D_DrvTrackPos "Current track position of driver seat";
CM_ SG_ 1068 PSM_D_DrvHeightPos "Current height position of driver seat";
CM_ SG_ 1069 XGW_WasherFluid_LevelSwitch "Washer Fluid Level Switch";
CM_ SG_ 1070 CHKSM_XGW_HCMInfo "Checksum";
CM_ SG_ 1070 ALV_XGW_HCMInfo "Alive counter";
CM_ SG_ 1070 XGW_HLVerLvlMode "Head lamp level of control mode";
CM_ SG_ 1070 XGW_AutoHeadlamp_LvlSts "Status of the function headlamp vertical levelling";
CM_ SG_ 1073 HUD_ECU_Check "HUD ECU fault type";
CM_ SG_ 1073 HUD_ECU_Fault "HUD ECU fault state";
CM_ SG_ 1074 MHU_FOTA_Checksum "FOTA global status message checksum";
CM_ SG_ 1074 MHU_FOTA_Alive_Counter "FOTA global status message alive counter";
CM_ SG_ 1074 MHU_FOTA_State "FOTA global status";
CM_ SG_ 1074 MHU_FOTA_Error_Code "FOTA Error Code";
CM_ SG_ 1075 MHU_Headlamp_Chksm "Head lamp control message checksum";
CM_ SG_ 1075 MHU_Headlamp_Aliv "Head lamp control message alive counter";
CM_ SG_ 1075 MHU_HLVerLvlMode "Head lamp level of control mode";
CM_ SG_ 1077 BCM_SCM_BC_Button "Status of Board Computer buton";
CM_ SG_ 1078 MHU_TELStatus "Represent the telephone status";
CM_ SG_ 1078 MHU_MUTEStatus "MUTE Status";
CM_ SG_ 1078 MHU_TEL_source "Represent the telephone source";
CM_ SG_ 1078 SECCAN_HUD_info "Seed generated from Secure CAN algorithm";
CM_ SG_ 1079 CRC_VCU_MHU_info_2 "Checksum";
CM_ SG_ 1079 ALIV_VCU_MHU_info_2 "Alive Counter";
CM_ SG_ 1079 VCU_Instant_ConsumEnergy "Instant Consumption Energy";
CM_ SG_ 1079 VCU_Average_ConsumEnergy "Average Consumption Energy";
CM_ SG_ 1079 VCU_SpdLimiterSts "Speed Limiter state";
CM_ SG_ 1079 VCU_LimiterSpeed "Set Limiter Speed";
CM_ SG_ 1079 VCU_SpdLim_OverrideSts "Extra Override Speed in Speed Limiter";
CM_ SG_ 1080 CHKSM_EDS_Error_FR_A "Check sum";
CM_ SG_ 1080 ALV_EDS_Error_FR_A "Alive Counter";
CM_ SG_ 1080 EDS_FailNum_ERR_FWD "FaultNumber";
CM_ SG_ 1080 EDS_FailGrade_ERR_FWD "Fault level of EDS system";
CM_ SG_ 1080 EDS_MotOverTempAlarm_FWD "Motor over temperture alarm ";
CM_ SG_ 1080 EDS_MotOverTempFault_FWD "Motor over temperture fault ";
CM_ SG_ 1080 EDS_MotTempSenFault_FWD "Motor temperature sensor fault ";
CM_ SG_ 1080 EDS_EDSOverTempUFault_FWD "EDS Upha Over temperature fault ";
CM_ SG_ 1080 EDS_EDSOverTempVFault_FWD "EDS Vpha Over temperature fault ";
CM_ SG_ 1080 EDS_EDSOverTempWFault_FWD "EDS Wpha Over temperature fault ";
CM_ SG_ 1080 EDS_EDSOverTempAlarm_FWD "EDS over temperture alarm ";
CM_ SG_ 1080 EDS_TCoolantOvHi_FWD " Alarm  when Cooling water temperature is too high ";
CM_ SG_ 1080 EDS_EDSTempCmpAlarm_FWD "EDS temp offset checkout alarm ";
CM_ SG_ 1080 EDS_EDSPhaOvCurentHWFault_FWD "Phase Current Overcurrent hardware fault ";
CM_ SG_ 1080 EDS_EDSphaOffCalFault_FWD "EDS phase Current Offset Calibration Fault";
CM_ SG_ 1080 EDS_EDSOverIdcLnkAlarm_FWD "EDS IdcLnk Overcurrent alarm";
CM_ SG_ 1080 EDS_EDSHVOverVoltageAlarm_FWD "EDS high voltage over voltage alarm ";
CM_ SG_ 1080 EDS_EDSHVOverVoltageFault_FWD "EDS high voltage over voltage fault ";
CM_ SG_ 1080 EDS_EDSHVUnderVoltageAlarm_FWD "EDS high voltage under voltage alarm";
CM_ SG_ 1080 EDS_EDSHVUnderVoltageFault_FWD "EDS high voltage under voltage fault ";
CM_ SG_ 1080 EDS_RunToDischaErr_FWD "Stateflow fail to enter avtive discharge ";
CM_ SG_ 1080 EDS_12VOverVoltageAlarm_FWD "12V Power over voltage alarm";
CM_ SG_ 1080 EDS_12VUnderVoltageAlarm_FWD "12V Power under voltage alarm ";
CM_ SG_ 1080 EDS_MotOverAlarm_FWD "Motor overspeed fault alarm ";
CM_ SG_ 1080 EDS_MotOverFault_FWD "Motor overspeed fault fault ";
CM_ SG_ 1080 EDS_ResolverOffsetAngle_FWD "EDS offset angle check fault
";
CM_ SG_ 1080 SECCAN_EDS_Error_FR_A "Seed generated from Secure CAN algorithm
";
CM_ SG_ 1081 CHKSM_EDS_Error_RR_A "Check sum";
CM_ SG_ 1081 ALV_EDS_Error_RR_A "Alive Counter";
CM_ SG_ 1081 EDS_FailNum_ERR_RWD "FaultNumber";
CM_ SG_ 1081 EDS_FailGrade_ERR_RWD "Fault level of EDS system";
CM_ SG_ 1081 EDS_MotOverTempAlarm_RWD "Motor over temperture alarm ";
CM_ SG_ 1081 EDS_MotOverTempFault_RWD "Motor over temperture fault ";
CM_ SG_ 1081 EDS_MotTempSenFault_RWD "Motor temperature sensor fault ";
CM_ SG_ 1081 EDS_EDSOverTempUFault_RWD "EDS Upha Over temperature fault ";
CM_ SG_ 1081 EDS_EDSOverTempVFault_RWD "EDS Vpha Over temperature fault ";
CM_ SG_ 1081 EDS_EDSOverTempWFault_RWD "EDS Wpha Over temperature fault ";
CM_ SG_ 1081 EDS_EDSOverTempAlarm_RWD "EDS over temperture alarm ";
CM_ SG_ 1081 EDS_TCoolantOvHi_RWD " Alarm  when Cooling water temperature is too high ";
CM_ SG_ 1081 EDS_EDSTempCmpAlarm_RWD "EDS temp offset checkout alarm ";
CM_ SG_ 1081 EDS_EDSPhaOvCurentHWFault_RWD "Phase Current Overcurrent hardware fault ";
CM_ SG_ 1081 EDS_EDSphaOffCalFault_RWD "EDS phase Current Offset Calibration Fault";
CM_ SG_ 1081 EDS_EDSOverIdcLnkAlarm_RWD "EDS IdcLnk Overcurrent alarm";
CM_ SG_ 1081 EDS_EDSHVOverVoltageAlarm_RWD "EDS high voltage over voltage alarm ";
CM_ SG_ 1081 EDS_EDSHVOverVoltageFault_RWD "EDS high voltage over voltage fault ";
CM_ SG_ 1081 EDS_EDSHVUnderVoltageAlarm_RWD "EDS high voltage under voltage alarm";
CM_ SG_ 1081 EDS_EDSHVUnderVoltageFault_RWD "EDS high voltage under voltage fault ";
CM_ SG_ 1081 EDS_RunToDischaErr_RWD "Stateflow fail to enter avtive discharge ";
CM_ SG_ 1081 EDS_12VOverVoltageAlarm_RWD "12V Power over voltage alarm";
CM_ SG_ 1081 EDS_12VUnderVoltageAlarm_RWD "12V Power under voltage alarm ";
CM_ SG_ 1081 EDS_MotOverAlarm_RWD "Motor overspeed fault alarm ";
CM_ SG_ 1081 EDS_MotOverFault_RWD "Motor overspeed fault fault ";
CM_ SG_ 1081 EDS_ResolverOffsetAngle_RWD "EDS offset angle check fault
";
CM_ SG_ 1081 SECCAN_EDS_Error_RR_A "Seed generated from Secure CAN algorithm
";
CM_ SG_ 1082 VCU_AutoP_Feedback "VCU feedback Auto P Setting status";
CM_ SG_ 1082 CRC_VCU_MHU_info "Checksum";
CM_ SG_ 1082 ALIV_VCU_MHU_info "Alive counter";
CM_ SG_ 1082 VCU_BrakeRegenMode "VCU Brake regenerative mode";
CM_ SG_ 1082 VCU_CreepDisable_stt "Feedback for Creep disable request";
CM_ SG_ 1082 VCU_PowerRegenGaugeDisplay "Power Regen gauge display, plus vaue is power level, minus value is regen level. ";
CM_ SG_ 1082 VCU_Charging_Authen_stt "Authentication status with chg. station ( for display only)";
CM_ SG_ 1082 VCU_ChgGun_BadConn_stt "Charging gun bad connection status";
CM_ SG_ 1082 VCU_ChgPort_Open_stt "Open status of charging port";
CM_ SG_ 1082 VCU_Regen_available "When braking / coasting regeneration system not available or regeneration system capability = 0 or regeneration system = failed.";
CM_ SG_ 1082 VCU_VehChg_STS "Vehicle Charging Status";
CM_ SG_ 1082 VCU_StoppingMode_stt "Stopping mode status";
CM_ SG_ 1082 VCU_SOC_display "HV battery SOC for displaying only - for VCU strategy";
CM_ SG_ 1082 VCU_ChgGun_Status "Charging gun status";
CM_ SG_ 1082 VCU_ChgPort_Lock_stt "Lock status of chaging port";
CM_ SG_ 1082 VCU_Hvbatt_charging_stt "HV battery charging - not charging status,for displaying only ( for both regen/ charging )";
CM_ SG_ 1083 MHU_SET_TiltPos "Current Steering Tilt Position";
CM_ SG_ 1083 MHU_SET_TelePos "Current Steering Tele Position";
CM_ SG_ 1083 MHU_SET_SteeringAdjust "Enter setting Steering position mode";
CM_ SG_ 1084 EASC_TiltPos "Current Steering Tilt Position";
CM_ SG_ 1084 EASC_TelePos "Current Steering Tele Position";
CM_ SG_ 1084 EASC_SteeringAdjust "Enter setting Steering position mode";
CM_ SG_ 1086 MHU_SET_Mediavolume "0
1
...
40
FF - Invalid
";
CM_ SG_ 1086 MHU_SET_Soundzone "0 - Invalid
1 - Front
2 - Rear
3 - ALL";
CM_ SG_ 1086 MHU_SET_Bass "Accuracy     -  1
Range High  - 12
Range Low   - 0
Conversion  - (D)-6
Unit            - /
Signal Age   - /
Invalid        - 1F";
CM_ SG_ 1086 MHU_SET_Fader "Accuracy   -     1
Range High -   20
Range Low  -    0
Conversion  -  (D)-10
Unit            -  /
Signal Age   -  /
Invalid        - 1F";
CM_ SG_ 1086 MHU_SET_MediaMute "0 - Invalid
1 - Mute
2 - Unmute
3 - Reserved";
CM_ SG_ 1086 MHU_SET_MidPitch "Accuracy     -  1
Range High  - 12
Range Low   - 0
Conversion  - (D)-6
Unit            - /
Signal Age   - /
Invalid        - 1F";
CM_ SG_ 1086 MHU_SET_Treble "Accuracy     -  1
Range High  - 12
Range Low   - 0
Conversion  - (D)-6
Unit            - /
Signal Age   - /
Invalid        - 1F";
CM_ SG_ 1086 MHU_SET_Balance "Accuracy   -     1
Range High -   20
Range Low  -    0
Conversion  -  (D)-10
Unit            -  /
Signal Age   -  /
Invalid        - 1F";
CM_ SG_ 1087 MHU_SET_EQ_1000HZ "Accuracy     -  1
Range High  - 12
Range Low   - 0
Conversion  - (D)-6
Unit            - /
Signal Age   - /
Invalid        - 1F";
CM_ SG_ 1087 MHU_SET_EQ_16000HZ "Accuracy     -  1
Range High  - 12
Range Low   - 0
Conversion  - (D)-6
Unit            - /
Signal Age   - /
Invalid        - 1F";
CM_ SG_ 1087 MHU_SET_EQ_250HZ "Accuracy     -  1
Range High  - 12
Range Low   - 0
Conversion  - (D)-6
Unit            - /
Signal Age   - /
Invalid        - 1F";
CM_ SG_ 1087 MHU_SET_EQ_4000HZ "Accuracy     -  1
Range High  - 12
Range Low   - 0
Conversion  - (D)-6
Unit            - /
Signal Age   - /
Invalid        - 1F";
CM_ SG_ 1087 MHU_SET_EQ_60HZ "Accuracy     -  1
Range High  - 12
Range Low   - 0
Conversion  - (D)-6
Unit            - /
Signal Age   - /
Invalid        - 1F";
CM_ SG_ 1087 MHU_SET_EQType "Flat - 0
Pop - 1
Rock - 2
Jazz  - 3
Classic - 4
Vocal - 5
Custom - 6
Invalid - F";
CM_ SG_ 1088 AMP_SET_EQ_1000HZ "Accuracy     -  1
Range High  - 12
Range Low   - 0
Conversion  - (D)-6
Unit            - /
Signal Age   - /
Invalid        - 1F";
CM_ SG_ 1088 AMP_SET_EQ_16000HZ "Accuracy     -  1
Range High  - 12
Range Low   - 0
Conversion  - (D)-6
Unit            - /
Signal Age   - /
Invalid        - 1F";
CM_ SG_ 1088 AMP_SET_EQ_250HZ "Accuracy     -  1
Range High  - 12
Range Low   - 0
Conversion  - (D)-6
Unit            - /
Signal Age   - /
Invalid        - 1F";
CM_ SG_ 1088 AMP_SET_EQ_4000HZ "Accuracy     -  1
Range High  - 12
Range Low   - 0
Conversion  - (D)-6
Unit            - /
Signal Age   - /
Invalid        - 1F";
CM_ SG_ 1088 AMP_SET_EQ_60HZ "Accuracy     -  1
Range High  - 12
Range Low   - 0
Conversion  - (D)-6
Unit            - /
Signal Age   - /
Invalid        - 1F";
CM_ SG_ 1088 AMP_SET_EQType "Flat - 0
Pop - 1
Rock - 2
Jazz  - 3
Classic - 4
Vocal - 5
Custom - 6
Invalid - F";
CM_ SG_ 1090 WLC_IC_Error "Internal Error (Charging IC)";
CM_ SG_ 1090 WLC_FAN_Error "FAN fault";
CM_ SG_ 1090 WLC_TempSNSR_Error "Temperature sensor fault";
CM_ SG_ 1090 WLC_Setting_standard "Need to transmit information on WPC ON/OFF Setting standard or Set standard";
CM_ SG_ 1090 Transmit_WLC_situation "Need to transmit WPC situation signal ";
CM_ SG_ 1090 WLC_VehSpeed_Error "Maximum vehicle speed over error (> 300 km/h)";
CM_ SG_ 1090 WLC_Resp_Error "Any error from WLC side";
CM_ SG_ 1090 WLC_FOD_Error "FOD error, Foreign Object detection";
CM_ SG_ 1090 WLC_Curr_Error "Over current";
CM_ SG_ 1090 WLC_Temp_Error "Over temperature";
CM_ SG_ 1091 WLC_IC_Error_2 "Internal Error (Charging IC)";
CM_ SG_ 1091 WLC_FAN_Error_2 "FAN fault";
CM_ SG_ 1091 WLC_TempSNSR_Error_2 "Temperature sensor fault";
CM_ SG_ 1091 WLC_Setting_standard_2 "Need to transmit information on WPC ON/OFF Setting standard or Set standard";
CM_ SG_ 1091 Transmit_WLC_situation_2 "Need to transmit WPC situation signal ";
CM_ SG_ 1091 WLC_VehSpeed_Error_2 "Maximum vehicle speed over error (> 300 km/h)";
CM_ SG_ 1091 WLC_Resp_Error_2 "Any error from WLC side";
CM_ SG_ 1091 WLC_FOD_Error_2 "FOD error, Foreign Object detection";
CM_ SG_ 1091 WLC_Curr_Error_2 "Over current";
CM_ SG_ 1091 WLC_Temp_Error_2 "Over temperature";
CM_ SG_ 1092 Checksum_MHU_ADAS_RP_Ctrl "Checksum";
CM_ SG_ 1092 Rolling_Counter_MHU_ADAS_RP_Ctrl "Roling counter
";
CM_ SG_ 1092 MHU_RPParkingstartReq "APP remote start auto parking";
CM_ SG_ 1092 MHU_RP_ParkOutModeConfirm "RP park out mode confirmation";
CM_ SG_ 1092 MHU_RP_ParkOutDircnConfirm "park out direction is confirmed ";
CM_ SG_ 1092 MHU_RemoteconnectionSts "MHU remote connection status ";
CM_ SG_ 1092 MHU_RP_FuncMode "Functional mode request";
CM_ SG_ 1092 MHU_SMParkingstartReq "APP remote start SM";
CM_ SG_ 1092 MHU_SMParkingControlReq "APP SM request(handshake)";
CM_ SG_ 1092 MHU_RP_RecoverParking "RP Parking Recovery Request";
CM_ SG_ 1092 MHU_RPStraightParkingDir "Straight in and straight out of the form direction";
CM_ SG_ 1092 MHU_SM_global_path_Status "Reserved for SM (current not use)";
CM_ SG_ 1092 MHU_SM_QuitReq "SM exit request";
CM_ SG_ 1092 MHU_RPParkingControlReq "APP remote control parking request(handshake)";
CM_ SG_ 1092 MHU_RP_QuitReq "RP exit request";
CM_ SG_ 1092 SECCAN_ADAS_RP_Ctrl "Seed portion from Secure CAN algorithm";
CM_ SG_ 1093 RS_Sol_L "Left Solar sensor values for the CCU";
CM_ SG_ 1093 RS_Sol_R "Right Solar sensor values for the CCU";
CM_ SG_ 1093 RS_F_LightSensor "Light sensor HW error";
CM_ SG_ 1093 RS_F_HUD_Sensor "HUD HW error";
CM_ SG_ 1093 RS_St_LampReq "Rain light sensor lamp request";
CM_ SG_ 1093 RS_St_CurrentRain "Represents the intensity of rain from RLS";
CM_ SG_ 1093 RS_HUD_illuminance "HUD sensor input";
CM_ SG_ 1094 MHU_TBT_Icon "Turn by Turn Icon";
CM_ SG_ 1094 MHU_Junction_MsgNum "Message order, start from 1";
CM_ SG_ 1094 MHU_Junction_TotalMsg "Total Junction message, default value is 1";
CM_ SG_ 1094 MHU_DrivingSide "Driving handside (Left hand side and Drive Hand side)";
CM_ SG_ 1094 MHU_Junction_type "Junction type";
CM_ SG_ 1094 MHU_JunctionElement1 "Junction element 1 (value 1-21)";
CM_ SG_ 1094 MHU_JunctionElement0 "Junction element 0, if MsgNum =1, it's exit junciton (value 1-21), if MsgNum >1, it's normal junction";
CM_ SG_ 1094 MHU_JunctionElement2 "Junction element 2 (value 1-21)";
CM_ SG_ 1094 MHU_JunctionElement4 "Junction element 4 (value 1-21)";
CM_ SG_ 1094 MHU_JunctionElement3 "Junction element 3 (value 1-21)";
CM_ SG_ 1094 MHU_JunctionElement5 "Junction element 5 (value 1-21)";
CM_ SG_ 1094 MHU_JunctionElement6 "Junction element 6 (value 1-21)";
CM_ SG_ 1095 MHU_SET_TransportMode "Enable/Disable Transport mode via MHU";
CM_ SG_ 1095 CHKSM_MHU_SET_CarMode "Checksum";
CM_ SG_ 1095 ALV_MHU_SET_CarMode "Alive counter";
CM_ SG_ 1095 MHU_Request_CarOFF "MHU request Car go to OFF state";
CM_ SG_ 1095 MHU_SET_ChildMode "Set Car in Child mode which keep climate control running and delay CPD (EU NCAP requirement)";
CM_ SG_ 1095 MHU_SET_GameMode "Set Car in Game mode";
CM_ SG_ 1095 MHU_SET_KaraokeMode "Set Car in Karaoket mode";
CM_ SG_ 1095 MHU_Req_StoppingMode "Stopping mode request";
CM_ SG_ 1095 MHU_SET_WashMode "Set Car in Wash mode";
CM_ SG_ 1095 MHU_SET_StopMode "Set Car Stop mode";
CM_ SG_ 1095 MHU_AVH_Sw "Set Car Auto vehicle hold (AVH) mode";
CM_ SG_ 1096 CHKSM_EDS_Error_FR_B "Check sum";
CM_ SG_ 1096 ALV_EDS_Error_FR_B "Alive Counter";
CM_ SG_ 1096 EDS_iDcLnkOvCLimFail_FWD "Bus current over-current fault";
CM_ SG_ 1096 EDS_MotBlockedFault_FWD "Motor blocked fault ";
CM_ SG_ 1096 EDS_RSLErr_FWD "Rotary transformer signal fault ";
CM_ SG_ 1096 EDS_MotTrqLimFault_FWD "Motor torque limit fault";
CM_ SG_ 1096 EDS_VCUChksumFault_FWD "VCU CheckSum fault ";
CM_ SG_ 1096 EDS_IGBTFault_FWD "IGBT fault ";
CM_ SG_ 1096 EDS_CANBusoffFault_FWD "CAN busoff fault ";
CM_ SG_ 1096 EDS_TDrvBoardOvHiWarn_FWD "Alarm when drive plate temperature is too high";
CM_ SG_ 1096 EDS_TIGBTOvHiFault_FWD "IGBT junction temperature over temperature fault";
CM_ SG_ 1096 EDS_TIGBTOvHiWarn_FWD "IGBT junction temperature over temperature alarm";
CM_ SG_ 1096 EDS_IOHWABSampFail_FWD "Chip control power sampling failure ";
CM_ SG_ 1096 EDS_EDSOpenFault_FWD "EDS open plate fault ";
CM_ SG_ 1096 EDS_MotorOpenFault_FWD "Motor open plate fault ";
CM_ SG_ 1096 EDS_EparkSampFail_FWD "EPP position sampling fault";
CM_ SG_ 1096 EDS_EmacBlkdWarn_FWD "Motor locked rotor warning ";
CM_ SG_ 1096 EDS_VerMatchFailureErr_FWD "EDS Software Version match Failure Fault ";
CM_ SG_ 1096 EDS_DiashCirNoPsblErr_FWD "Unable to active short circuit fault ";
CM_ SG_ 1096 EDS_OperOutdRngErr_FWD "Short circuit over temperature operation diagnosis ";
CM_ SG_ 1096 EDS_PhaseLossFaultErr_FWD "Missing phase fault ";
CM_ SG_ 1096 EDS_CPLDFault_FWD "CPLD Fault";
CM_ SG_ 1096 EDS_CPLDFaultBaseSpd_FWD "CPLD enter ASC fault based on motor speed";
CM_ SG_ 1096 EDS_IOHWABNen33Fail_FWD "Feedback NEN33 fault";
CM_ SG_ 1096 EDS_HvMcuSlightFault_FWD "HvMcu Slight fault";
CM_ SG_ 1096 EDS_HvMcuSevFault_FWD "HvMcu serious fault";
CM_ SG_ 1096 EDS_EDSPhaSampHWFault_FWD "UVW phase current monitoring sampling hard wire fault";
CM_ SG_ 1096 EDS_IsOvHiErr_FWD "Phase current overcurrent diagnosis";
CM_ SG_ 1096 EDS_CanRollingCounterErr_FWD "Receive count error ";
CM_ SG_ 1096 EDS_CanTimeoutErr_FWD " Receive timeout error";
CM_ SG_ 1096 EDS_CrashFault_FWD "Crash signal fault";
CM_ SG_ 1096 EDS_PCFSlightFault_FWD "PCF EPP slight fault";
CM_ SG_ 1096 EDS_PCFSerFault_FWD "PCF EPP serious fault";
CM_ SG_ 1096 SECCAN_EDS_Error_FR_B "Seed generated from Secure CAN algorithm
";
CM_ SG_ 1097 CHKSM_EDS_Error_RR_B "Check sum";
CM_ SG_ 1097 ALV_EDS_Error_RR_B "Alive Counter";
CM_ SG_ 1097 EDS_iDcLnkOvCLimFail_RWD "Bus current over-current fault";
CM_ SG_ 1097 EDS_MotBlockedFault_RWD "Motor blocked fault ";
CM_ SG_ 1097 EDS_RSLErr_RWD "Rotary transformer signal fault ";
CM_ SG_ 1097 EDS_MotTrqLimFault_RWD "Motor torque limit fault";
CM_ SG_ 1097 EDS_VCUChksumFault_RWD "VCU CheckSum fault ";
CM_ SG_ 1097 EDS_IGBTFault_RWD "IGBT fault ";
CM_ SG_ 1097 EDS_CANBusoffFault_RWD "CAN busoff fault ";
CM_ SG_ 1097 EDS_TDrvBoardOvHiWarn_RWD "Alarm when drive plate temperature is too high";
CM_ SG_ 1097 EDS_TIGBTOvHiFault_RWD "IGBT junction temperature over temperature fault";
CM_ SG_ 1097 EDS_TIGBTOvHiWarn_RWD "IGBT junction temperature over temperature alarm";
CM_ SG_ 1097 EDS_IOHWABSampFail_RWD "Chip control power sampling failure ";
CM_ SG_ 1097 EDS_EDSOpenFault_RWD "EDS open plate fault ";
CM_ SG_ 1097 EDS_MotorOpenFault_RWD "Motor open plate fault ";
CM_ SG_ 1097 EDS_EparkSampFail_RWD "EPP position sampling fault";
CM_ SG_ 1097 EDS_EmacBlkdWarn_RWD "Motor locked rotor warning ";
CM_ SG_ 1097 EDS_VerMatchFailureErr_RWD "EDS Software Version match Failure Fault ";
CM_ SG_ 1097 EDS_DiashCirNoPsblErr_RWD "Unable to active short circuit fault ";
CM_ SG_ 1097 EDS_OperOutdRngErr_RWD "Short circuit over temperature operation diagnosis ";
CM_ SG_ 1097 EDS_PhaseLossFaultErr_RWD "Missing phase fault ";
CM_ SG_ 1097 EDS_CPLDFault_RWD "CPLD Fault";
CM_ SG_ 1097 EDS_CPLDFaultBaseSpd_RWD "CPLD enter ASC fault based on motor speed";
CM_ SG_ 1097 EDS_IOHWABNen33Fail_RWD "Feedback NEN33 fault";
CM_ SG_ 1097 EDS_HvMcuSlightFault_RWD "HvMcu Slight fault";
CM_ SG_ 1097 EDS_HvMcuSevFault_RWD "HvMcu serious fault";
CM_ SG_ 1097 EDS_EDSPhaSampHWFault_RWD "UVW phase current monitoring sampling hard wire fault";
CM_ SG_ 1097 EDS_IsOvHiErr_RWD "Phase current overcurrent diagnosis";
CM_ SG_ 1097 EDS_CanRollingCounterErr_RWD "Receive count error ";
CM_ SG_ 1097 EDS_CanTimeoutErr_RWD " Receive timeout error";
CM_ SG_ 1097 EDS_CrashFault_RWD "Crash signal fault";
CM_ SG_ 1097 EDS_PCFSlightFault_RWD "PCF EPP slight fault";
CM_ SG_ 1097 EDS_PCFSerFault_RWD "PCF EPP serious fault";
CM_ SG_ 1104 MHU_SET_WindowLifterFrontL "Window lifter Front Driver";
CM_ SG_ 1104 MHU_SET_WindowLifterFrontR "Window lifter Front Passenger";
CM_ SG_ 1104 MHU_SET_WindowLifterRearL "Window lifter Rear Left";
CM_ SG_ 1104 MHU_SET_WindowLifterRearR "Window lifter Rear Right";
CM_ SG_ 1104 MHU_SET_WindowAutoClose "Auto close windows when doors are locked";
CM_ SG_ 1105 Checksum_RSSI "Checksum";
CM_ SG_ 1105 Rolling_Counter_RSSI "Roling counter";
CM_ SG_ 1105 RSSI_Value "RSSI value";
CM_ SG_ 1105 SECCAN_RSSI "Seed portion from Secure CAN algorithm";
CM_ SG_ 1106 MHU_SET_ANN1_MODE "0 - Invalid
1 - Navigation
2 - Telephone
3 - Prompts";
CM_ SG_ 1107 MHU_SET_ANN1_PROMPTS_SPEAKER "0 - Invalid
1 - Select FL_FR
2 - Select CEN
3 - Select FL_FR_CEN
4 - Select RL_RR
5- Select All
6- Reserved";
CM_ SG_ 1108 MHU_SET_ANN2_CEN_Mute "0 - Invalid
1 - Mute ANN2 Center
2 - Unmute ANN2 Center";
CM_ SG_ 1108 MHU_SET_ANN2_RR_Mute "0 - Invalid
1 - Mute ANN2 Rear Right
2 - Unmute ANN2 Rear Right";
CM_ SG_ 1108 MHU_SET_ANN2_RL_Mute "0 - Invalid
1 - Mute ANN2 Rear Left
2 - Unmute ANN2 Rear Left";
CM_ SG_ 1108 MHU_SET_ANN2_FR_Mute "0 - Invalid
1 - Mute ANN2 Front Right
2 - Unmute ANN2 Front Right";
CM_ SG_ 1108 MHU_SET_ANN2_FL_Mute "0 - Invalid
1 - Mute ANN2 Front Left
2 - Unmute ANN2 Front Left";
CM_ SG_ 1109 AMP_SET_Mediavolume "0
1
...
40
FF - Invalid
";
CM_ SG_ 1109 AMP_SET_Soundzone "0 - Invalid
1 - Front
2 - Rear
3 - ALL";
CM_ SG_ 1109 AMP_SET_Bass "Accuracy     -  1
Range High  - 12
Range Low   - 0
Conversion  - (D)-6
Unit            - /
Signal Age   - /
Invalid        - 1F";
CM_ SG_ 1109 AMP_SET_Fader "Accuracy   -     1
Range High -   20
Range Low  -    0
Conversion  -  (D)-10
Unit            -  /
Signal Age   -  /
Invalid        - 1F";
CM_ SG_ 1109 AMP_SET_MediaMute "0 - Invalid
1 - Mute
2 - Unmute
3 - Reserved";
CM_ SG_ 1109 AMP_SET_MidPitch "Accuracy     -  1
Range High  - 12
Range Low   - 0
Conversion  - (D)-6
Unit            - /
Signal Age   - /
Invalid        - 1F";
CM_ SG_ 1109 AMP_SET_Treble "Accuracy     -  1
Range High  - 12
Range Low   - 0
Conversion  - (D)-6
Unit            - /
Signal Age   - /
Invalid        - 1F";
CM_ SG_ 1109 AMP_SET_Balance "Accuracy   -     1
Range High -   20
Range Low  -    0
Conversion  -  (D)-10
Unit            -  /
Signal Age   -  /
Invalid        - 1F";
CM_ SG_ 1110 OP_WISW_SZL_LIN "Wiper Status Signal (Right Stalk)
Bit 0~1 : Switch status on Automatic wiping, Wiper step 1, Wiper step 2 switch status
Bit 2: Not used.(this bit is always 0.)
Bit 3: Front mist switch status
Bit 4: Front washer switch status
Bit 5: Not used.(this bit is always 0.)
Bit 6: Rear wiping switch status
Bit 7: Rear washing switch status
* 1111 1111: Signal Invalid
";
CM_ SG_ 1110 COMM_ERR_SZL_LIN "This signal showes if there is or was a communication error.";
CM_ SG_ 1110 BCM_Wiper_Front_Status "Front Wiper Motor Feedback of status";
CM_ SG_ 1110 OP_WIPO_SZL_LIN "Wiper Step (Right Stalk)
0x0: Step 1
0x1: Step 2
0x2: Step 3
0x4: Step 4
0x7: signal invalid
";
CM_ SG_ 1110 OP_COLS_SZL_LIN "Left Stalk Lever Signal (Light function)
*the status of each bit follows this: (0: Off, 1: ON)
Bit 0: Highway flashing right indicator status
Bit 1: Flashing right indicator status
Bit 2: Highway flashing left indicator status
Bit 3: Flashing left indicator status
Bit 4: High-beam light status
Bit 5: High-beam light flashing status
Bit 6: Reserved
Bit 7: Not used.(this value is always ?0?)
* 1111 1111: Signal Invalid";
CM_ SG_ 1110 NOD_ERR_SZL_LIN "If SCM detects any error (any error status occurred), SCM sends this signal as ?error active?.";
CM_ SG_ 1110 BCM_Wiper_Rear_Status "Rear wiper status check";
CM_ SG_ 1110 ALIV_WISW_SZL_LIN "Standard Alive-counter for validation of the transmission between SCM and Master ECU.";
CM_ SG_ 1111 AmbLight_Error_Z5 "Status of Ambient Light ColorZone 5";
CM_ SG_ 1111 AmbLight_Error_Z4 "Status of Ambient Light ColorZone 4";
CM_ SG_ 1111 AmbLight_Error_Z3 "Status of Ambient Light ColorZone 3";
CM_ SG_ 1111 AmbLight_Error_Z2 "Status of Ambient Light ColorZone 2";
CM_ SG_ 1111 AmbLight_Error_Z1 "Status of Ambient Light ColorZone 1";
CM_ SG_ 1112 AmbLightColorZoneReq "Zone identifier for interior ambient lighting colour.
Allows smart LED module to take into account messages addressed to
their zone when colour value are received.";
CM_ SG_ 1112 AmbLightColorRed "Requested Ambient Lighting Red Intensity";
CM_ SG_ 1112 AmbLightColorGreen "Requested Ambient Lighting Green Intensity";
CM_ SG_ 1112 AmbLightColorBlue "Requested Ambient Lighting Blue Intensity";
CM_ SG_ 1112 SECCAN_BCM_Clr_Rq "Seed generated from Secure CAN algorithm";
CM_ SG_ 1113 AmbLightIntensityTimingZoneReq "Zone identifier for interior ambient lighting intensity. Allows smart LED module to take into account messages addressed to their zone when intensity value are received.";
CM_ SG_ 1113 AmbLightIntensityTimingTypeReq "Zone identifier for interior ambient lighting intensity.
Allows smart LED module to take into account messages about Type of Timing to used.";
CM_ SG_ 1113 AmbLightIntenTimingBrightReq "Intensity (brightness) of interior ambient lighting.";
CM_ SG_ 1113 AmbLightIntensityTimingT1Req "Blinking: Ton; Wave: Tfade; Morse: Ton1; Fading: Tfade";
CM_ SG_ 1113 AmbLightIntensityTimingT2Req "Blinking: Toff; Wave: not used; Morse: Toff1, Fading: not used";
CM_ SG_ 1113 AmbLightIntensityTimingT3Req "Blinking: not used; Wave: not used; Morse: Ton2, Fading: not used";
CM_ SG_ 1113 AmbLightIntensityTimingT4Req "Blinking: not used; Wave: not used; Morse: Toff2, Fading: not used";
CM_ SG_ 1113 AmbLightIntensityTimingN2Req "Morse: number of repetitions for Ton2";
CM_ SG_ 1113 AmbLightIntensityTimingN1Req "Morse: number of repetitions for Ton1";
CM_ SG_ 1115 HOD_steering_wheel_type "Adas inform HOD about steering wheel type";
CM_ SG_ 1115 HOD_vehicle_type "Adas inform HOD about vehicle type";
CM_ SG_ 1115 ADAS_HOD_state_requesting "Adas requesting HOD state";
CM_ SG_ 1124 LDML_LampAssemblySts "Left Combined Lamp Module Failure Status";
CM_ SG_ 1124 LDML_PosLmpSts "Left Position light output Status";
CM_ SG_ 1124 LDML_ControllerSts "Left Light Driving Module Controller Failure Status";
CM_ SG_ 1124 LDML_TurnIndicatorSts "Left Turn light output  Status";
CM_ SG_ 1124 LDML_AuxLBSts "Left Auxiliary low beam output  Status";
CM_ SG_ 1124 LDML_LowBeamSts "Left Low beam output  Status";
CM_ SG_ 1124 LDML_HighBeamSts "Left High beam output Status";
CM_ SG_ 1124 LDML_DayRunningLampSts "Left DayRunning Lamp output Status";
CM_ SG_ 1124 LDML_DayTimeRunningLightFbSts "The Feedback Status of On/Off DayTime Running Light switch";
CM_ SG_ 1124 LDML_AutoLvlFbSts "The Feedback Status of On/Off Auto-leveling switch";
CM_ SG_ 1124 LDML_AdptvDrvBeamFbSts "The Feedback Status of On/Off Adaptive Driving Beam switch";
CM_ SG_ 1124 LDML_AuxHBSts "Left Auxiliary high beam output  Status";
CM_ SG_ 1124 LDML_FollowMeHomeFbSts "The Feedback Status of Follow Me Home mode switch";
CM_ SG_ 1124 LDML_ExteriorLightFbSts "The Feedback Status of Exterior Light mode switch";
CM_ SG_ 1125 LDMR_LampAssemblySts "Right Combined Lamp Module Failure Status";
CM_ SG_ 1125 LDMR_PosLmpSts "Right Position light output Status";
CM_ SG_ 1125 LDMR_ControllerSts "Right Light Driving Module Controller Failure Status";
CM_ SG_ 1125 LDMR_TurnIndicatorSts "Right Turn light output  Status";
CM_ SG_ 1125 LDMR_AuxLBSts "Right Auxiliary low beam output  Status";
CM_ SG_ 1125 LDMR_LowBeamSts "Right Low beam output  Status";
CM_ SG_ 1125 LDMR_HighBeamSts "Right High beam output Status";
CM_ SG_ 1125 LDMR_DayRunningLampSts "Right DayRunning Lamp output Status";
CM_ SG_ 1125 LDMR_DayTimeRunningLightFbSts "The Feedback Status of On/Off DayTime Running Light switch
";
CM_ SG_ 1125 LDMR_AutoLvlFbSts "The Feedback Status of On/Off Auto-leveling switch
";
CM_ SG_ 1125 LDMR_AdptvDrvBeamFbSts "The Feedback Status of On/Off Adaptive Driving Beam switch";
CM_ SG_ 1125 LDMR_AuxHBSts "Right Auxiliary high beam output  Status";
CM_ SG_ 1125 LDMR_FollowMeHomeFbSts "The Feedback Status of Follow Me Home mode switch";
CM_ SG_ 1125 LDMR_ExteriorLightFbSts "The Feedback Status of Exterior Light mode switch";
CM_ SG_ 1136 AMP_SET_ANN1_MODE "0 - Invalid
1 - Navigation
2 - Telephone
3 - Prompts";
CM_ SG_ 1137 AMP_SET_ANN1_PROMPTS_SPEAKER "0 - Invalid
1 - Select FL_FR
2 - Select CEN
3 - Select FL_FR_CEN
4 - Select RL_RR
5- Select All
6- Reserved";
CM_ SG_ 1138 AMP_SET_ANN2_CEN_Mute "0 - Invalid
1 - Mute ANN2 Center
2 - Unmute ANN2 Center";
CM_ SG_ 1138 AMP_SET_ANN2_RR_Mute "0 - Invalid
1 - Mute ANN2 Rear Right
2 - Unmute ANN2 Rear Right";
CM_ SG_ 1138 AMP_SET_ANN2_RL_Mute "0 - Invalid
1 - Mute ANN2 Rear Left
2 - Unmute ANN2 Rear Left";
CM_ SG_ 1138 AMP_SET_ANN2_FR_Mute "0 - Invalid
1 - Mute ANN2 Front Right
2 - Unmute ANN2 Front Right";
CM_ SG_ 1138 AMP_SET_ANN2_FL_Mute "0 - Invalid
1 - Mute ANN2 Front Left
2 - Unmute ANN2 Front Left";
CM_ SG_ 1152 CHKSM_PSM_WARNING_MSG "Checksum for PSM warning message";
CM_ SG_ 1152 ALV_PSM_WARNING_MSG "Alive counter for PSM warning message";
CM_ SG_ 1152 PSM_DrvSeatMissalignment "Driver Seat Misalignment";
CM_ SG_ 1152 PSM_PasSeatMisalignment "Passenger Seat Misalignment";
CM_ SG_ 1152 PSM_WflagRes3 "Warning Flag Reserved Bit 3";
CM_ SG_ 1152 PSM_WflagRes4 "Warning Flag Reserved Bit 4";
CM_ SG_ 1152 PSM_WflagRes5 "Warning Flag Reserved Bit 5";
CM_ SG_ 1152 PSM_WflagRes6 "Warning Flag Reserved Bit 6";
CM_ SG_ 1152 PSM_WflagRes7 "Warning Flag Reserved Bit 7";
CM_ SG_ 1152 PSM_WflagRes8 "Warning Flag Reserved Bit 8";
CM_ SG_ 1152 PSM_WflagRes9 "Warning Flag Reserved Bit 9";
CM_ SG_ 1152 PSM_WflagRes10 "Warning Flag Reserved Bit 10";
CM_ SG_ 1152 PSM_WflagRes11 "Warning Flag Reserved Bit 11";
CM_ SG_ 1152 PSM_WflagRes12 "Warning Flag Reserved Bit 12";

BA_DEF_ BO_  "GenMsgSendType" ENUM "Cyclic","NotUsed","NotUsed","NotUsed","NotUsed","NotUsed","NotUsed","IfActive","NoMsgSendType","NotUsed";
BA_DEF_ BO_  "GenMsgILSupport" ENUM "No","Yes";
BA_DEF_ BO_  "DiagResponse" ENUM "No","Yes";
BA_DEF_ BO_  "DiagRequest" ENUM "No","Yes";
BA_DEF_ BO_  "NmAsrMessage" ENUM "No","Yes";
BA_DEF_ BO_  "DiagState" ENUM "No","Yes";
BA_DEF_ BO_  "DiagUudtResponse" ENUM "False","True";
BA_DEF_ BO_  "GenMsgStartDelayTime" INT 0 65535;
BA_DEF_ BO_  "GenMsgDelayTime" INT 0 0;
BA_DEF_ BO_  "GenMsgNrOfRepetition" INT 0 0;
BA_DEF_ BO_  "GenMsgCycleTimeFast" INT 0 0;
BA_DEF_ BO_  "GenMsgCycleTime" INT 0 0;
BA_DEF_ SG_  "GenSigSendType" ENUM "Cyclic","OnWrite","OnWriteWithRepetition","OnChange","OnChangeWithRepetition","IfActive","IfActiveWithRepetition","NoSigSendType","NotUsed","NotUsed","NotUsed","NotUsed","NotUsed";
BA_DEF_ SG_  "InvalidValue" STRING;
BA_DEF_ SG_  "GenSigStartValue" INT 0 0;
BA_DEF_ SG_  "GenSigTimeoutTime_ALL" INT 0 65535;
BA_DEF_DEF_  "DiagRequest" "No";
BA_DEF_DEF_  "DiagResponse" "No";
BA_DEF_DEF_  "DiagState" "No";
BA_DEF_DEF_  "DiagUudtResponse" "False";
BA_DEF_DEF_  "GenMsgCycleTime" 0;
BA_DEF_DEF_  "GenMsgCycleTimeFast" 0;
BA_DEF_DEF_  "GenMsgDelayTime" 0;
BA_DEF_DEF_  "GenMsgILSupport" "Yes";
BA_DEF_DEF_  "GenMsgNrOfRepetition" 0;
BA_DEF_DEF_  "GenMsgSendType" "NoMsgSendType";
BA_DEF_DEF_  "GenMsgStartDelayTime" 0;
BA_DEF_DEF_  "GenSigSendType" "Cyclic";
BA_DEF_DEF_  "GenSigStartValue" 0;
BA_DEF_DEF_  "GenSigTimeoutTime_ALL" 0;
BA_DEF_DEF_  "NmAsrMessage" "No";
BA_ "GenMsgCycleTimeFast" BO_ 1030 100;
BA_ "GenMsgNrOfRepetition" BO_ 1030 3;
BA_ "GenMsgCycleTimeFast" BO_ 1032 100;
BA_ "GenMsgNrOfRepetition" BO_ 1032 3;
BA_ "GenMsgCycleTimeFast" BO_ 1034 25;
BA_ "GenMsgNrOfRepetition" BO_ 1034 3;
BA_ "GenMsgCycleTimeFast" BO_ 1035 100;
BA_ "GenMsgNrOfRepetition" BO_ 1035 3;
BA_ "GenMsgCycleTime" BO_ 1036 200;
BA_ "GenMsgSendType" BO_ 1036 0;
BA_ "GenMsgCycleTime" BO_ 1037 120;
BA_ "GenMsgSendType" BO_ 1037 0;
BA_ "GenMsgCycleTime" BO_ 1038 1000;
BA_ "GenMsgSendType" BO_ 1038 0;
BA_ "GenMsgCycleTime" BO_ 1039 1000;
BA_ "GenMsgSendType" BO_ 1039 0;
BA_ "GenMsgCycleTime" BO_ 1040 1000;
BA_ "GenMsgSendType" BO_ 1040 0;
BA_ "GenMsgSendType" BO_ 1042 0;
BA_ "GenMsgCycleTime" BO_ 1042 400;
BA_ "GenMsgSendType" BO_ 1043 0;
BA_ "GenMsgCycleTime" BO_ 1043 300;
BA_ "GenMsgSendType" BO_ 1044 0;
BA_ "GenMsgCycleTime" BO_ 1044 500;
BA_ "GenMsgCycleTime" BO_ 1046 100;
BA_ "GenMsgSendType" BO_ 1046 0;
BA_ "GenMsgCycleTime" BO_ 1052 1000;
BA_ "GenMsgSendType" BO_ 1052 0;
BA_ "GenMsgCycleTime" BO_ 1053 100;
BA_ "GenMsgSendType" BO_ 1053 0;
BA_ "GenMsgCycleTime" BO_ 1054 300;
BA_ "GenMsgCycleTimeFast" BO_ 1054 25;
BA_ "GenMsgNrOfRepetition" BO_ 1054 3;
BA_ "GenMsgSendType" BO_ 1054 0;
BA_ "GenMsgSendType" BO_ 1055 0;
BA_ "GenMsgCycleTime" BO_ 1055 300;
BA_ "GenMsgCycleTime" BO_ 1058 1000;
BA_ "GenMsgSendType" BO_ 1058 0;
BA_ "GenMsgCycleTime" BO_ 1059 1000;
BA_ "GenMsgSendType" BO_ 1059 0;
BA_ "GenMsgCycleTime" BO_ 1064 200;
BA_ "GenMsgSendType" BO_ 1064 0;
BA_ "GenMsgCycleTime" BO_ 1068 200;
BA_ "GenMsgSendType" BO_ 1068 0;
BA_ "GenMsgCycleTimeFast" BO_ 1069 500;
BA_ "GenMsgNrOfRepetition" BO_ 1069 3;
BA_ "GenMsgCycleTime" BO_ 1070 100;
BA_ "GenMsgSendType" BO_ 1070 0;
BA_ "GenMsgCycleTime" BO_ 1073 100;
BA_ "GenMsgSendType" BO_ 1073 0;
BA_ "GenMsgCycleTime" BO_ 1074 500;
BA_ "GenMsgSendType" BO_ 1074 0;
BA_ "GenMsgCycleTime" BO_ 1075 500;
BA_ "GenMsgSendType" BO_ 1075 0;
BA_ "GenMsgCycleTimeFast" BO_ 1077 100;
BA_ "GenMsgNrOfRepetition" BO_ 1077 3;
BA_ "GenMsgCycleTimeFast" BO_ 1078 50;
BA_ "GenMsgNrOfRepetition" BO_ 1078 2;
BA_ "GenMsgCycleTime" BO_ 1079 100;
BA_ "GenMsgSendType" BO_ 1079 0;
BA_ "GenMsgCycleTime" BO_ 1080 100;
BA_ "GenMsgSendType" BO_ 1080 0;
BA_ "GenMsgCycleTime" BO_ 1081 100;
BA_ "GenMsgSendType" BO_ 1081 0;
BA_ "GenMsgCycleTime" BO_ 1082 100;
BA_ "GenMsgSendType" BO_ 1082 0;
BA_ "GenMsgCycleTimeFast" BO_ 1083 50;
BA_ "GenMsgNrOfRepetition" BO_ 1083 2;
BA_ "GenMsgCycleTimeFast" BO_ 1084 100;
BA_ "GenMsgNrOfRepetition" BO_ 1084 2;
BA_ "GenMsgCycleTime" BO_ 1086 100;
BA_ "GenMsgSendType" BO_ 1086 0;
BA_ "GenMsgCycleTime" BO_ 1087 100;
BA_ "GenMsgSendType" BO_ 1087 0;
BA_ "GenMsgCycleTime" BO_ 1088 100;
BA_ "GenMsgSendType" BO_ 1088 0;
BA_ "GenMsgCycleTime" BO_ 1090 500;
BA_ "GenMsgSendType" BO_ 1090 0;
BA_ "GenMsgCycleTime" BO_ 1091 500;
BA_ "GenMsgSendType" BO_ 1091 0;
BA_ "GenMsgCycleTime" BO_ 1092 100;
BA_ "GenMsgSendType" BO_ 1092 0;
BA_ "GenMsgCycleTime" BO_ 1093 100;
BA_ "GenMsgSendType" BO_ 1093 0;
BA_ "GenMsgCycleTime" BO_ 1095 200;
BA_ "GenMsgSendType" BO_ 1095 0;
BA_ "GenMsgCycleTime" BO_ 1096 100;
BA_ "GenMsgSendType" BO_ 1096 0;
BA_ "GenMsgCycleTime" BO_ 1097 100;
BA_ "GenMsgSendType" BO_ 1097 0;
BA_ "GenMsgCycleTimeFast" BO_ 1104 100;
BA_ "GenMsgNrOfRepetition" BO_ 1104 3;
BA_ "GenMsgCycleTime" BO_ 1105 100;
BA_ "GenMsgSendType" BO_ 1105 0;
BA_ "GenMsgCycleTime" BO_ 1106 100;
BA_ "GenMsgSendType" BO_ 1106 0;
BA_ "GenMsgCycleTime" BO_ 1107 100;
BA_ "GenMsgSendType" BO_ 1107 0;
BA_ "GenMsgCycleTime" BO_ 1108 100;
BA_ "GenMsgSendType" BO_ 1108 0;
BA_ "GenMsgCycleTime" BO_ 1109 100;
BA_ "GenMsgSendType" BO_ 1109 0;
BA_ "GenMsgCycleTimeFast" BO_ 1112 100;
BA_ "GenMsgNrOfRepetition" BO_ 1112 3;
BA_ "GenMsgCycleTimeFast" BO_ 1113 100;
BA_ "GenMsgNrOfRepetition" BO_ 1113 3;
BA_ "GenMsgSendType" BO_ 1115 0;
BA_ "GenMsgCycleTime" BO_ 1115 500;
BA_ "GenMsgCycleTime" BO_ 1124 50;
BA_ "GenMsgSendType" BO_ 1124 0;
BA_ "GenMsgCycleTime" BO_ 1125 50;
BA_ "GenMsgSendType" BO_ 1125 0;
BA_ "GenMsgCycleTime" BO_ 1136 100;
BA_ "GenMsgSendType" BO_ 1136 0;
BA_ "GenMsgCycleTime" BO_ 1137 100;
BA_ "GenMsgSendType" BO_ 1137 0;
BA_ "GenMsgCycleTime" BO_ 1138 100;
BA_ "GenMsgSendType" BO_ 1138 0;
BA_ "GenMsgCycleTime" BO_ 1152 1000;
BA_ "GenMsgCycleTimeFast" BO_ 1152 100;
BA_ "GenMsgNrOfRepetition" BO_ 1152 2;
BA_ "GenMsgSendType" BO_ 1152 0;
BA_ "GenSigSendType" SG_ 1030 MHU_SET_SeatHeatingFrontL 2;
BA_ "InvalidValue" SG_ 1030 MHU_SET_SeatHeatingFrontL "4h";
BA_ "GenSigSendType" SG_ 1030 MHU_SET_SeatHeatingFrontR 2;
BA_ "InvalidValue" SG_ 1030 MHU_SET_SeatHeatingFrontR "4h";
BA_ "GenSigSendType" SG_ 1030 MHU_SET_SeatHeatingReartL 2;
BA_ "InvalidValue" SG_ 1030 MHU_SET_SeatHeatingReartL "4h";
BA_ "GenSigSendType" SG_ 1030 MHU_SET_SeatHeatingRearR 2;
BA_ "InvalidValue" SG_ 1030 MHU_SET_SeatHeatingRearR "4h";
BA_ "GenSigSendType" SG_ 1030 MHU_SET_SeatCoolingFrontL 2;
BA_ "InvalidValue" SG_ 1030 MHU_SET_SeatCoolingFrontL "4h";
BA_ "GenSigSendType" SG_ 1030 MHU_SET_SeatCoolingFrontR 2;
BA_ "InvalidValue" SG_ 1030 MHU_SET_SeatCoolingFrontR "4h";
BA_ "GenSigSendType" SG_ 1030 MHU_SET_SeatCoolingRearL 2;
BA_ "InvalidValue" SG_ 1030 MHU_SET_SeatCoolingRearL "4h";
BA_ "GenSigSendType" SG_ 1030 MHU_SET_SeatCoolingRearR 2;
BA_ "InvalidValue" SG_ 1030 MHU_SET_SeatCoolingRearR "4h";
BA_ "GenSigSendType" SG_ 1032 MHU_SET_MirrorAuto 2;
BA_ "GenSigStartValue" SG_ 1032 MHU_SET_MirrorAuto 3;
BA_ "InvalidValue" SG_ 1032 MHU_SET_MirrorAuto "3h";
BA_ "GenSigSendType" SG_ 1032 MHU_SET_MirrorAutoUnfold 2;
BA_ "GenSigStartValue" SG_ 1032 MHU_SET_MirrorAutoUnfold 3;
BA_ "InvalidValue" SG_ 1032 MHU_SET_MirrorAutoUnfold "3h";
BA_ "GenSigSendType" SG_ 1032 MHU_SET_WLC 2;
BA_ "GenSigStartValue" SG_ 1032 MHU_SET_WLC 3;
BA_ "InvalidValue" SG_ 1032 MHU_SET_WLC "3h";
BA_ "GenSigSendType" SG_ 1032 MHU_SET_AutoRearWiper 2;
BA_ "GenSigStartValue" SG_ 1032 MHU_SET_AutoRearWiper 3;
BA_ "InvalidValue" SG_ 1032 MHU_SET_AutoRearWiper "3h";
BA_ "GenSigSendType" SG_ 1032 MHU_SET_RearHeatedWindow 2;
BA_ "InvalidValue" SG_ 1032 MHU_SET_RearHeatedWindow "3h";
BA_ "GenSigSendType" SG_ 1032 MHU_TPMSReset 2;
BA_ "InvalidValue" SG_ 1032 MHU_TPMSReset "3h";
BA_ "GenSigSendType" SG_ 1032 MHU_SET_MirrorDefaultSetting 2;
BA_ "GenSigStartValue" SG_ 1032 MHU_SET_MirrorDefaultSetting 3;
BA_ "InvalidValue" SG_ 1032 MHU_SET_MirrorDefaultSetting "3h";
BA_ "GenSigSendType" SG_ 1032 MHU_SET_MirrorReverseLink 2;
BA_ "GenSigSendType" SG_ 1032 MHU_SET_AntiTheftMode 2;
BA_ "GenSigStartValue" SG_ 1032 MHU_SET_AntiTheftMode 3;
BA_ "InvalidValue" SG_ 1032 MHU_SET_AntiTheftMode "3h";
BA_ "GenSigSendType" SG_ 1032 MHU_SET_WLCReminder 2;
BA_ "GenSigStartValue" SG_ 1032 MHU_SET_WLCReminder 1;
BA_ "InvalidValue" SG_ 1032 MHU_SET_WLCReminder "3h";
BA_ "GenSigSendType" SG_ 1032 MHU_SET_ClimateKeepOn 2;
BA_ "InvalidValue" SG_ 1032 MHU_SET_ClimateKeepOn "null";
BA_ "GenSigSendType" SG_ 1032 MHU_SET_WLC2 2;
BA_ "GenSigStartValue" SG_ 1032 MHU_SET_WLC2 1;
BA_ "InvalidValue" SG_ 1032 MHU_SET_WLC2 "3h";
BA_ "GenSigSendType" SG_ 1032 MHU_SET_WLC2Reminder 2;
BA_ "GenSigStartValue" SG_ 1032 MHU_SET_WLC2Reminder 1;
BA_ "InvalidValue" SG_ 1032 MHU_SET_WLC2Reminder "3h";
BA_ "GenSigSendType" SG_ 1032 MHU_IntrusionAlertStatus 2;
BA_ "GenSigStartValue" SG_ 1032 MHU_IntrusionAlertStatus 3;
BA_ "InvalidValue" SG_ 1032 MHU_IntrusionAlertStatus "3h";
BA_ "GenSigSendType" SG_ 1034 MHU_SET_HudUIContent 2;
BA_ "InvalidValue" SG_ 1034 MHU_SET_HudUIContent "7h";
BA_ "GenSigSendType" SG_ 1034 MHU_SET_HudUIColor 2;
BA_ "GenSigSendType" SG_ 1034 MHU_SET_HudScreenOnOFF 2;
BA_ "GenSigStartValue" SG_ 1034 MHU_SET_HudScreenOnOFF 1;
BA_ "InvalidValue" SG_ 1034 MHU_SET_HudScreenOnOFF "3h";
BA_ "GenSigSendType" SG_ 1034 MHU_SET_UserBrightnessLvl 2;
BA_ "InvalidValue" SG_ 1034 MHU_SET_UserBrightnessLvl "Fh";
BA_ "GenSigSendType" SG_ 1034 MHU_SET_HudWorkingMode 2;
BA_ "InvalidValue" SG_ 1034 MHU_SET_HudWorkingMode "3h";
BA_ "GenSigSendType" SG_ 1034 MHU_SET_HudUISize 2;
BA_ "GenSigSendType" SG_ 1034 MHU_SET_UIContentMediaInfo 2;
BA_ "GenSigSendType" SG_ 1034 MHU_SET_UIContentCallInfo 2;
BA_ "GenSigSendType" SG_ 1034 MHU_SET_UIContentPoweRegen 2;
BA_ "GenSigSendType" SG_ 1034 MHU_SET_HudTurnSigOnOff 4;
BA_ "GenSigSendType" SG_ 1034 MHU_SET_HudBSDOnOff 4;
BA_ "GenSigSendType" SG_ 1034 MHU_SET_HudRCTAOnOff 4;
BA_ "GenSigSendType" SG_ 1035 MHU_SET_AvasSound 2;
BA_ "GenSigStartValue" SG_ 1035 MHU_SET_AvasSound 1;
BA_ "GenSigTimeoutTime_ALL" SG_ 1036 CHSKM_MHU_SEAT_CONTROL 1000;
BA_ "InvalidValue" SG_ 1036 CHSKM_MHU_SEAT_CONTROL "null";
BA_ "GenSigTimeoutTime_ALL" SG_ 1036 ALV_MHU_SEAT_CONTROL 1000;
BA_ "InvalidValue" SG_ 1036 ALV_MHU_SEAT_CONTROL "Fh";
BA_ "GenSigTimeoutTime_ALL" SG_ 1036 MHU_DrvSeat_Control_Status 1000;
BA_ "InvalidValue" SG_ 1036 MHU_DrvSeat_Control_Status "7h";
BA_ "GenSigTimeoutTime_ALL" SG_ 1036 MHU_ExpDrvReclinerPos 1000;
BA_ "InvalidValue" SG_ 1036 MHU_ExpDrvReclinerPos "7Fh";
BA_ "GenSigTimeoutTime_ALL" SG_ 1036 MHU_ExpDrvTiltPos 1000;
BA_ "InvalidValue" SG_ 1036 MHU_ExpDrvTiltPos "1Fh";
BA_ "GenSigTimeoutTime_ALL" SG_ 1036 MHU_ExpDrvTrackPos 1000;
BA_ "InvalidValue" SG_ 1036 MHU_ExpDrvTrackPos "FFh";
BA_ "GenSigTimeoutTime_ALL" SG_ 1036 MHU_ExpDrvHeightPos 1000;
BA_ "InvalidValue" SG_ 1036 MHU_ExpDrvHeightPos "3Fh";
BA_ "GenSigTimeoutTime_ALL" SG_ 1037 CHKSM_MHU_DIGIT_SPEED 1500;
BA_ "GenSigTimeoutTime_ALL" SG_ 1037 ALV_MHU_DIGIT_SPEED 1500;
BA_ "InvalidValue" SG_ 1037 ALV_MHU_DIGIT_SPEED "Fh";
BA_ "GenSigTimeoutTime_ALL" SG_ 1037 MHU_DigitSpeed 1500;
BA_ "InvalidValue" SG_ 1037 MHU_DigitSpeed "1FFh";
BA_ "GenSigTimeoutTime_ALL" SG_ 1038 AveragePwrConsumpTripA 5000;
BA_ "GenSigTimeoutTime_ALL" SG_ 1038 AverageFuelConsumpTripA 5000;
BA_ "GenSigTimeoutTime_ALL" SG_ 1038 AvarageSpeedTripA 5000;
BA_ "InvalidValue" SG_ 1038 AvarageSpeedTripA "1FFh";
BA_ "GenSigTimeoutTime_ALL" SG_ 1038 TripA 5000;
BA_ "InvalidValue" SG_ 1038 TripA "1FFFFh";
BA_ "GenSigTimeoutTime_ALL" SG_ 1039 AveragePwrConsumpTripB 5000;
BA_ "GenSigTimeoutTime_ALL" SG_ 1039 AverageFuelConsumpTripB 5000;
BA_ "GenSigTimeoutTime_ALL" SG_ 1039 AvarageSpeedTripB 5000;
BA_ "InvalidValue" SG_ 1039 AvarageSpeedTripB "1FFh";
BA_ "GenSigTimeoutTime_ALL" SG_ 1039 TripB 5000;
BA_ "InvalidValue" SG_ 1039 TripB "1FFFFh";
BA_ "GenSigTimeoutTime_ALL" SG_ 1040 AveragePwrConsumpTripAuto 5000;
BA_ "GenSigTimeoutTime_ALL" SG_ 1040 AverageFuelConsumpTripAuto 5000;
BA_ "GenSigTimeoutTime_ALL" SG_ 1040 AvarageSpeedTripAuto 5000;
BA_ "InvalidValue" SG_ 1040 AvarageSpeedTripAuto "1FFh";
BA_ "GenSigTimeoutTime_ALL" SG_ 1040 TripAuto 5000;
BA_ "InvalidValue" SG_ 1040 TripAuto "1FFFFh";
BA_ "GenSigTimeoutTime_ALL" SG_ 1042 eCall_state 2000;
BA_ "GenSigTimeoutTime_ALL" SG_ 1043 CHKSM_FCAM_SensorFault 1500;
BA_ "InvalidValue" SG_ 1043 ALV_FCAM_Sensor_Fault "Fh";
BA_ "GenSigTimeoutTime_ALL" SG_ 1043 ALV_FCAM_Sensor_Fault 1500;
BA_ "InvalidValue" SG_ 1043 FCAM_SRR_RR_Fault "3h";
BA_ "GenSigTimeoutTime_ALL" SG_ 1043 FCAM_SRR_RR_Fault 1500;
BA_ "InvalidValue" SG_ 1043 FCAM_SCAM_Fault "3h";
BA_ "GenSigTimeoutTime_ALL" SG_ 1043 FCAM_SCAM_Fault 1500;
BA_ "InvalidValue" SG_ 1043 FCAM_SRR_FR_Fault "3h";
BA_ "GenSigTimeoutTime_ALL" SG_ 1043 FCAM_SRR_FR_Fault 1500;
BA_ "InvalidValue" SG_ 1043 FCAM_MRR_Fault "3h";
BA_ "GenSigTimeoutTime_ALL" SG_ 1043 FCAM_MRR_Fault 1500;
BA_ "InvalidValue" SG_ 1043 FCAM_SRR_RL_Fault "3h";
BA_ "GenSigTimeoutTime_ALL" SG_ 1043 FCAM_SRR_RL_Fault 1500;
BA_ "InvalidValue" SG_ 1043 FCAM_SRR_FL_Fault "3h";
BA_ "GenSigTimeoutTime_ALL" SG_ 1043 FCAM_SRR_FL_Fault 1500;
BA_ "GenSigTimeoutTime_ALL" SG_ 1043 SECCAN_FCAM_SensorFault 1500;
BA_ "GenSigTimeoutTime_ALL" SG_ 1044 CRC_SW_1 2500;
BA_ "InvalidValue" SG_ 1044 Message_Counter_SW_1 "Fh";
BA_ "GenSigTimeoutTime_ALL" SG_ 1044 Message_Counter_SW_1 2500;
BA_ "GenSigTimeoutTime_ALL" SG_ 1044 Calc_Threshold 2500;
BA_ "GenSigTimeoutTime_ALL" SG_ 1044 Real_Impedence 2500;
BA_ "GenSigTimeoutTime_ALL" SG_ 1044 Immag_Impedence 2500;
BA_ "InvalidValue" SG_ 1044 ERR_ST_HOD "Fh";
BA_ "GenSigTimeoutTime_ALL" SG_ 1044 ERR_ST_HOD 2500;
BA_ "GenSigTimeoutTime_ALL" SG_ 1044 RsErr_HOD 2500;
BA_ "InvalidValue" SG_ 1044 HOD_status "5h";
BA_ "GenSigTimeoutTime_ALL" SG_ 1044 HOD_status 2500;
BA_ "GenSigStartValue" SG_ 1046 BCM_STAT_LeftMirrorPosX 15;
BA_ "GenSigTimeoutTime_ALL" SG_ 1046 BCM_STAT_LeftMirrorPosX 500;
BA_ "InvalidValue" SG_ 1046 BCM_STAT_LeftMirrorPosX "FFh";
BA_ "GenSigStartValue" SG_ 1046 BCM_STAT_LeftMirrorPosY 15;
BA_ "GenSigTimeoutTime_ALL" SG_ 1046 BCM_STAT_LeftMirrorPosY 500;
BA_ "InvalidValue" SG_ 1046 BCM_STAT_LeftMirrorPosY "FFh";
BA_ "GenSigStartValue" SG_ 1046 BCM_STAT_RightMirrorPosX 15;
BA_ "GenSigTimeoutTime_ALL" SG_ 1046 BCM_STAT_RightMirrorPosX 500;
BA_ "InvalidValue" SG_ 1046 BCM_STAT_RightMirrorPosX "FFh";
BA_ "GenSigStartValue" SG_ 1046 BCM_STAT_RightMirrorPosY 15;
BA_ "GenSigTimeoutTime_ALL" SG_ 1046 BCM_STAT_RightMirrorPosY 500;
BA_ "InvalidValue" SG_ 1046 BCM_STAT_RightMirrorPosY "FFh";
BA_ "GenSigTimeoutTime_ALL" SG_ 1046 BCM_STAT_Mirror 500;
BA_ "InvalidValue" SG_ 1046 BCM_STAT_Mirror "3h";
BA_ "GenSigTimeoutTime_ALL" SG_ 1046 BCM_STAT_MirrorAdjustLeft 500;
BA_ "InvalidValue" SG_ 1046 BCM_STAT_MirrorAdjustLeft "3h";
BA_ "GenSigTimeoutTime_ALL" SG_ 1046 BCM_STAT_MirrorAdjustRight 500;
BA_ "InvalidValue" SG_ 1046 BCM_STAT_MirrorAdjustRight "3h";
BA_ "GenSigSendType" SG_ 1049 SHVU_STAT_SeatHeatingFrontL 3;
BA_ "InvalidValue" SG_ 1049 SHVU_STAT_SeatHeatingFrontL "4h";
BA_ "GenSigSendType" SG_ 1049 SHVU_STAT_SeatHeatingFrontR 3;
BA_ "InvalidValue" SG_ 1049 SHVU_STAT_SeatHeatingFrontR "4h";
BA_ "GenSigSendType" SG_ 1049 SHVU_STAT_SeatCoolingFrontL 3;
BA_ "InvalidValue" SG_ 1049 SHVU_STAT_SeatCoolingFrontL "4h";
BA_ "GenSigSendType" SG_ 1049 SHVU_STAT_SeatCoolingFrontR 3;
BA_ "InvalidValue" SG_ 1049 SHVU_STAT_SeatCoolingFrontR "4h";
BA_ "GenSigSendType" SG_ 1049 SHVU_STAT_FrontSeatVentSts 3;
BA_ "InvalidValue" SG_ 1049 SHVU_STAT_FrontSeatVentSts "3h";
BA_ "GenSigSendType" SG_ 1050 SHVU_STAT_SeatCoolingRearL 3;
BA_ "InvalidValue" SG_ 1050 SHVU_STAT_SeatCoolingRearL "4h";
BA_ "GenSigSendType" SG_ 1050 SHVU_STAT_SeatCoolingRearR 3;
BA_ "InvalidValue" SG_ 1050 SHVU_STAT_SeatCoolingRearR "4h";
BA_ "GenSigSendType" SG_ 1050 SHVU_STAT_SeatHeatingReartL 3;
BA_ "InvalidValue" SG_ 1050 SHVU_STAT_SeatHeatingReartL "4h";
BA_ "GenSigSendType" SG_ 1050 SHVU_STAT_SeatHeatingRearR 3;
BA_ "InvalidValue" SG_ 1050 SHVU_STAT_SeatHeatingRearR "4h";
BA_ "GenSigSendType" SG_ 1050 SHVU_STAT_RearSeatVentSts 3;
BA_ "InvalidValue" SG_ 1050 SHVU_STAT_RearSeatVentSts "3h";
BA_ "GenSigTimeoutTime_ALL" SG_ 1052 CHKSM_PSM_SEAT_POSITION 5000;
BA_ "GenSigTimeoutTime_ALL" SG_ 1052 AVL_PSM_SEAT_POSITION 5000;
BA_ "InvalidValue" SG_ 1052 AVL_PSM_SEAT_POSITION "Fh";
BA_ "GenSigTimeoutTime_ALL" SG_ 1052 PSM_Seat_track_pos_Dri 5000;
BA_ "InvalidValue" SG_ 1052 PSM_Seat_track_pos_Dri "3h";
BA_ "GenSigTimeoutTime_ALL" SG_ 1052 PSM_Seat_track_posPas 5000;
BA_ "InvalidValue" SG_ 1052 PSM_Seat_track_posPas "3h";
BA_ "GenSigStartValue" SG_ 1053 BCM_STAT_AutoRearWiper 1;
BA_ "GenSigTimeoutTime_ALL" SG_ 1053 BCM_STAT_AutoRearWiper 500;
BA_ "InvalidValue" SG_ 1053 BCM_STAT_AutoRearWiper "3h";
BA_ "GenSigStartValue" SG_ 1053 BCM_STAT_MirrorFoldSetting 3;
BA_ "GenSigTimeoutTime_ALL" SG_ 1053 BCM_STAT_MirrorFoldSetting 500;
BA_ "InvalidValue" SG_ 1053 BCM_STAT_MirrorFoldSetting "3h";
BA_ "GenSigTimeoutTime_ALL" SG_ 1053 BCM_STAT_IMMO_KeyfobID2 500;
BA_ "GenSigTimeoutTime_ALL" SG_ 1053 BCM_STAT_MirrorAutoUnfold 500;
BA_ "InvalidValue" SG_ 1053 BCM_STAT_MirrorAutoUnfold "3h";
BA_ "GenSigTimeoutTime_ALL" SG_ 1053 BCM_STAT_MirrorReverseLink 500;
BA_ "GenSigTimeoutTime_ALL" SG_ 1053 BCM_STAT_MirrorDefaultSTATting 500;
BA_ "InvalidValue" SG_ 1053 BCM_STAT_MirrorDefaultSTATting "3h";
BA_ "GenSigTimeoutTime_ALL" SG_ 1053 BCM_STAT_WelcomeTriggerCondition 500;
BA_ "InvalidValue" SG_ 1053 BCM_STAT_WelcomeTriggerCondition "3h";
BA_ "GenSigStartValue" SG_ 1053 BCM_STAT_FrontDomeLamp 1;
BA_ "GenSigTimeoutTime_ALL" SG_ 1053 BCM_STAT_FrontDomeLamp 500;
BA_ "InvalidValue" SG_ 1053 BCM_STAT_FrontDomeLamp "3h";
BA_ "GenSigTimeoutTime_ALL" SG_ 1053 BCM_STAT_FollowMeHome 500;
BA_ "InvalidValue" SG_ 1053 BCM_STAT_FollowMeHome "5h";
BA_ "GenSigTimeoutTime_ALL" SG_ 1053 BCM_STAT_ExteriorLight 500;
BA_ "InvalidValue" SG_ 1053 BCM_STAT_ExteriorLight "4h";
BA_ "GenSigStartValue" SG_ 1053 BCM_STAT_RemoteLockFeedback 7;
BA_ "GenSigTimeoutTime_ALL" SG_ 1053 BCM_STAT_RemoteLockFeedback 500;
BA_ "InvalidValue" SG_ 1053 BCM_STAT_RemoteLockFeedback "7h";
BA_ "GenSigStartValue" SG_ 1053 BCM_STAT_RemoteDoorUnlock 3;
BA_ "GenSigTimeoutTime_ALL" SG_ 1053 BCM_STAT_RemoteDoorUnlock 500;
BA_ "InvalidValue" SG_ 1053 BCM_STAT_RemoteDoorUnlock "3h";
BA_ "GenSigStartValue" SG_ 1053 BCM_STAT_AutoDoorUnlock 3;
BA_ "GenSigTimeoutTime_ALL" SG_ 1053 BCM_STAT_AutoDoorUnlock 500;
BA_ "InvalidValue" SG_ 1053 BCM_STAT_AutoDoorUnlock "3h";
BA_ "GenSigTimeoutTime_ALL" SG_ 1053 BCM_STAT_WalkawayDoorLock 500;
BA_ "GenSigSendType" SG_ 1053 BCM_STAT_WalkawayDoorLock 2;
BA_ "GenSigStartValue" SG_ 1053 BCM_STAT_AmbientLightBrighness 80;
BA_ "GenSigTimeoutTime_ALL" SG_ 1053 BCM_STAT_AmbientLightBrighness 500;
BA_ "InvalidValue" SG_ 1053 BCM_STAT_AmbientLightBrighness "7Fh";
BA_ "GenSigStartValue" SG_ 1053 BCM_STAT_WiperServiceMode 3;
BA_ "GenSigTimeoutTime_ALL" SG_ 1053 BCM_STAT_WiperServiceMode 500;
BA_ "InvalidValue" SG_ 1053 BCM_STAT_WiperServiceMode "3h";
BA_ "GenSigStartValue" SG_ 1053 BCM_STAT_IMMO_KeyfobID 3;
BA_ "GenSigTimeoutTime_ALL" SG_ 1053 BCM_STAT_IMMO_KeyfobID 500;
BA_ "InvalidValue" SG_ 1053 BCM_STAT_IMMO_KeyfobID "3h";
BA_ "GenSigTimeoutTime_ALL" SG_ 1053 BCM_STAT_RearHeatedWindowMirror 500;
BA_ "InvalidValue" SG_ 1053 BCM_STAT_RearHeatedWindowMirror "3h";
BA_ "GenSigStartValue" SG_ 1053 BCM_STAT_AntiTheftMode 3;
BA_ "GenSigTimeoutTime_ALL" SG_ 1053 BCM_STAT_AntiTheftMode 500;
BA_ "InvalidValue" SG_ 1053 BCM_STAT_AntiTheftMode "4h";
BA_ "GenSigTimeoutTime_ALL" SG_ 1053 BCM_STAT_ClimateKeepOnSts 500;
BA_ "InvalidValue" SG_ 1053 BCM_STAT_ClimateKeepOnSts "null";
BA_ "GenSigTimeoutTime_ALL" SG_ 1053 BCM_STAT_FKSfeedback 500;
BA_ "InvalidValue" SG_ 1053 BCM_STAT_FKSfeedback "3h";
BA_ "GenSigTimeoutTime_ALL" SG_ 1053 SECCAN_CmftCnfrm 500;
BA_ "InvalidValue" SG_ 1053 SECCAN_CmftCnfrm "null";
BA_ "GenSigTimeoutTime_ALL" SG_ 1054 HUD_UIColor 1500;
BA_ "GenSigTimeoutTime_ALL" SG_ 1054 HUD_UIContent 1500;
BA_ "GenSigTimeoutTime_ALL" SG_ 1054 HUD_OperationState 1500;
BA_ "GenSigStartValue" SG_ 1054 HUD_HeightLvl 11;
BA_ "GenSigTimeoutTime_ALL" SG_ 1054 HUD_HeightLvl 1500;
BA_ "GenSigTimeoutTime_ALL" SG_ 1054 HUD_UI_Size 1500;
BA_ "GenSigTimeoutTime_ALL" SG_ 1054 HUD_UIContentMediaInfo 1500;
BA_ "GenSigTimeoutTime_ALL" SG_ 1054 HUD_UIContentCallInfor 1500;
BA_ "GenSigTimeoutTime_ALL" SG_ 1054 HUD_UIContentPowerRegen 1500;
BA_ "GenSigTimeoutTime_ALL" SG_ 1054 HUD_UIModeSignal 1500;
BA_ "InvalidValue" SG_ 1054 HUD_UIModeSignal "7h";
BA_ "GenSigTimeoutTime_ALL" SG_ 1054 HUD_WorkingMode 1500;
BA_ "GenSigTimeoutTime_ALL" SG_ 1054 HUD_ActualBrightnes 1500;
BA_ "GenSigTimeoutTime_ALL" SG_ 1054 HUD_RotateAngleLvl 1500;
BA_ "GenSigStartValue" SG_ 1054 HUD_UserSetBrightnessLvl 5;
BA_ "GenSigTimeoutTime_ALL" SG_ 1054 HUD_UserSetBrightnessLvl 1500;
BA_ "GenSigTimeoutTime_ALL" SG_ 1054 HUD_Language 1500;
BA_ "GenSigSendType" SG_ 1054 HUD_TurnSigOnOff_Feed 4;
BA_ "GenSigTimeoutTime_ALL" SG_ 1054 HUD_TurnSigOnOff_Feed 1500;
BA_ "GenSigSendType" SG_ 1054 HUD_BSDOnOff_Feed 4;
BA_ "GenSigTimeoutTime_ALL" SG_ 1054 HUD_BSDOnOff_Feed 1500;
BA_ "GenSigSendType" SG_ 1054 HUD_RCTAOnOff_Feed 4;
BA_ "GenSigTimeoutTime_ALL" SG_ 1054 HUD_RCTAOnOff_Feed 1500;
BA_ "GenSigTimeoutTime_ALL" SG_ 1054 HUD_Mileage_Unit 1500;
BA_ "GenSigStartValue" SG_ 1054 HUD_UserProfileId 1;
BA_ "GenSigTimeoutTime_ALL" SG_ 1054 HUD_UserProfileId 1500;
BA_ "InvalidValue" SG_ 1054 HUD_UserProfileId "Fh";
BA_ "GenSigTimeoutTime_ALL" SG_ 1054 HUD_DimmingDelayTime 1500;
BA_ "GenSigTimeoutTime_ALL" SG_ 1055 CHKSM_PAS_SensorFault 1500;
BA_ "InvalidValue" SG_ 1055 ALV_PAS_Sensor_Fault "Fh";
BA_ "GenSigTimeoutTime_ALL" SG_ 1055 ALV_PAS_Sensor_Fault 1500;
BA_ "InvalidValue" SG_ 1055 PAS_SVM_LCamera_Fault "3h";
BA_ "GenSigTimeoutTime_ALL" SG_ 1055 PAS_SVM_LCamera_Fault 1500;
BA_ "InvalidValue" SG_ 1055 PAS_SVM_FCamera_Fault "3h";
BA_ "GenSigTimeoutTime_ALL" SG_ 1055 PAS_SVM_FCamera_Fault 1500;
BA_ "GenSigTimeoutTime_ALL" SG_ 1055 SECCAN_PAS_SensorFault 1500;
BA_ "InvalidValue" SG_ 1055 PAS_SVM_RCamera_Fault "3h";
BA_ "GenSigTimeoutTime_ALL" SG_ 1055 PAS_SVM_RCamera_Fault 1500;
BA_ "InvalidValue" SG_ 1055 PAS_SVM_RightCamera_Fault "3h";
BA_ "GenSigTimeoutTime_ALL" SG_ 1055 PAS_SVM_RightCamera_Fault 1500;
BA_ "GenSigTimeoutTime_ALL" SG_ 1058 CHKSM_MHU_STAT 5000;
BA_ "InvalidValue" SG_ 1058 CHKSM_MHU_STAT "null";
BA_ "GenSigTimeoutTime_ALL" SG_ 1058 ALV_MHU_STAT 5000;
BA_ "InvalidValue" SG_ 1058 ALV_MHU_STAT "Fh";
BA_ "GenSigTimeoutTime_ALL" SG_ 1058 MHU_STAT_Cluster 5000;
BA_ "InvalidValue" SG_ 1058 MHU_STAT_Cluster "3h";
BA_ "GenSigTimeoutTime_ALL" SG_ 1058 MHU_STAT_Infotainment 5000;
BA_ "InvalidValue" SG_ 1058 MHU_STAT_Infotainment "3h";
BA_ "GenSigStartValue" SG_ 1058 MHU_STAT_MileageUnit 3;
BA_ "GenSigTimeoutTime_ALL" SG_ 1058 MHU_STAT_MileageUnit 5000;
BA_ "InvalidValue" SG_ 1058 MHU_STAT_MileageUnit "3h";
BA_ "GenSigStartValue" SG_ 1058 MHU_STAT_PressureUnit 3;
BA_ "GenSigTimeoutTime_ALL" SG_ 1058 MHU_STAT_PressureUnit 5000;
BA_ "InvalidValue" SG_ 1058 MHU_STAT_PressureUnit "3h";
BA_ "GenSigStartValue" SG_ 1058 MHU_STAT_TemperatureUnit 3;
BA_ "GenSigTimeoutTime_ALL" SG_ 1058 MHU_STAT_TemperatureUnit 5000;
BA_ "InvalidValue" SG_ 1058 MHU_STAT_TemperatureUnit "3h";
BA_ "GenSigStartValue" SG_ 1058 MHU_STAT_DateTimeFormat 3;
BA_ "GenSigTimeoutTime_ALL" SG_ 1058 MHU_STAT_DateTimeFormat 5000;
BA_ "InvalidValue" SG_ 1058 MHU_STAT_DateTimeFormat "3h";
BA_ "GenSigTimeoutTime_ALL" SG_ 1058 MHU_Operation_State 5000;
BA_ "InvalidValue" SG_ 1058 MHU_Operation_State "7h";
BA_ "GenSigStartValue" SG_ 1058 MHU_STAT_Language 31;
BA_ "GenSigTimeoutTime_ALL" SG_ 1058 MHU_STAT_Language 5000;
BA_ "InvalidValue" SG_ 1058 MHU_STAT_Language "1Fh";
BA_ "GenSigStartValue" SG_ 1058 MHU_STAT_EnergyConsumptionUnit 7;
BA_ "GenSigTimeoutTime_ALL" SG_ 1058 MHU_STAT_EnergyConsumptionUnit 5000;
BA_ "InvalidValue" SG_ 1058 MHU_STAT_EnergyConsumptionUnit "Fh";
BA_ "GenSigTimeoutTime_ALL" SG_ 1058 BAS_version 5000;
BA_ "InvalidValue" SG_ 1058 BAS_version "";
BA_ "GenSigStartValue" SG_ 1058 MHU_STAT_SaleCountry 1023;
BA_ "GenSigTimeoutTime_ALL" SG_ 1058 MHU_STAT_SaleCountry 5000;
BA_ "InvalidValue" SG_ 1058 MHU_STAT_SaleCountry "3FFh";
BA_ "GenSigTimeoutTime_ALL" SG_ 1058 MHU_STAT_BatLvlPopsetting 5000;
BA_ "InvalidValue" SG_ 1058 MHU_STAT_BatLvlPopsetting "3h";
BA_ "GenSigTimeoutTime_ALL" SG_ 1058 MHU_STAT_DistToEmptyUnit 5000;
BA_ "InvalidValue" SG_ 1058 MHU_STAT_DistToEmptyUnit "3h";
BA_ "GenSigTimeoutTime_ALL" SG_ 1059 AVAS_BatteryUnderVoltage 5000;
BA_ "InvalidValue" SG_ 1059 AVAS_BatteryUnderVoltage "null";
BA_ "GenSigTimeoutTime_ALL" SG_ 1059 AVAS_BatteryOverVoltage 5000;
BA_ "InvalidValue" SG_ 1059 AVAS_BatteryOverVoltage "null";
BA_ "GenSigTimeoutTime_ALL" SG_ 1059 AVAS_VINInfoNotPrgm 5000;
BA_ "InvalidValue" SG_ 1059 AVAS_VINInfoNotPrgm "null";
BA_ "GenSigTimeoutTime_ALL" SG_ 1059 AVAS_AMPVoltSplDrvOperationFail 5000;
BA_ "InvalidValue" SG_ 1059 AVAS_AMPVoltSplDrvOperationFail "null";
BA_ "GenSigTimeoutTime_ALL" SG_ 1059 AVAS_AMPIntFaultOverCurr 5000;
BA_ "InvalidValue" SG_ 1059 AVAS_AMPIntFaultOverCurr "null";
BA_ "GenSigTimeoutTime_ALL" SG_ 1059 AVAS_AMPInternalFaultDCError 5000;
BA_ "InvalidValue" SG_ 1059 AVAS_AMPInternalFaultDCError "null";
BA_ "GenSigTimeoutTime_ALL" SG_ 1059 AVAS_AMPInternalFaultOverTemp 5000;
BA_ "InvalidValue" SG_ 1059 AVAS_AMPInternalFaultOverTemp "null";
BA_ "GenSigTimeoutTime_ALL" SG_ 1059 AVAS_AMPInternalFaultClockError 5000;
BA_ "InvalidValue" SG_ 1059 AVAS_AMPInternalFaultClockError "null";
BA_ "GenSigTimeoutTime_ALL" SG_ 1059 AVAS_SpkrMntPwrSwDrvHighFlt 5000;
BA_ "InvalidValue" SG_ 1059 AVAS_SpkrMntPwrSwDrvHighFlt "null";
BA_ "GenSigTimeoutTime_ALL" SG_ 1059 AVAS_SpkrMntPwrSwDrvLowFlt 5000;
BA_ "InvalidValue" SG_ 1059 AVAS_SpkrMntPwrSwDrvLowFlt "null";
BA_ "GenSigTimeoutTime_ALL" SG_ 1059 AVAS_InternalSpeakerOpen 5000;
BA_ "InvalidValue" SG_ 1059 AVAS_InternalSpeakerOpen "null";
BA_ "GenSigTimeoutTime_ALL" SG_ 1059 AVAS_ECUMalFlshOperationErr 5000;
BA_ "InvalidValue" SG_ 1059 AVAS_ECUMalFlshOperationErr "null";
BA_ "GenSigTimeoutTime_ALL" SG_ 1059 AVAS_ECUMalfunctionRamFailure 5000;
BA_ "InvalidValue" SG_ 1059 AVAS_ECUMalfunctionRamFailure "null";
BA_ "GenSigTimeoutTime_ALL" SG_ 1059 AVAS_ECUMalEEPROMFailure 5000;
BA_ "InvalidValue" SG_ 1059 AVAS_ECUMalEEPROMFailure "null";
BA_ "GenSigTimeoutTime_ALL" SG_ 1059 AVAS_CANBusOff 5000;
BA_ "InvalidValue" SG_ 1059 AVAS_CANBusOff "null";
BA_ "GenSigTimeoutTime_ALL" SG_ 1059 AVAS_LossCommVehicleSpeed 5000;
BA_ "InvalidValue" SG_ 1059 AVAS_LossCommVehicleSpeed "null";
BA_ "GenSigTimeoutTime_ALL" SG_ 1059 AVAS_LossCommGearPosition 5000;
BA_ "InvalidValue" SG_ 1059 AVAS_LossCommGearPosition "null";
BA_ "GenSigTimeoutTime_ALL" SG_ 1059 AVAS_LossCommAVASCloseCmd 5000;
BA_ "InvalidValue" SG_ 1059 AVAS_LossCommAVASCloseCmd "null";
BA_ "InvalidValue" SG_ 1064 TRMFitted "3";
BA_ "GenSigTimeoutTime_ALL" SG_ 1064 TRMFitted 1000;
BA_ "GenSigStartValue" SG_ 1064 TRMFitted 2;
BA_ "GenSigTimeoutTime_ALL" SG_ 1068 CHSKM_PSM_D_SEAT_CONTROL 1000;
BA_ "InvalidValue" SG_ 1068 CHSKM_PSM_D_SEAT_CONTROL "null";
BA_ "GenSigTimeoutTime_ALL" SG_ 1068 ALV_PSM_D_SEAT_CONTROL 1000;
BA_ "InvalidValue" SG_ 1068 ALV_PSM_D_SEAT_CONTROL "Fh";
BA_ "GenSigTimeoutTime_ALL" SG_ 1068 PSM_D_DrvSeat_Control_Status 1000;
BA_ "InvalidValue" SG_ 1068 PSM_D_DrvSeat_Control_Status "7h";
BA_ "GenSigTimeoutTime_ALL" SG_ 1068 PSM_D_DrvReclinerPos 1000;
BA_ "InvalidValue" SG_ 1068 PSM_D_DrvReclinerPos "7Fh";
BA_ "GenSigTimeoutTime_ALL" SG_ 1068 PSM_D_DrvTiltPos 1000;
BA_ "InvalidValue" SG_ 1068 PSM_D_DrvTiltPos "1Fh";
BA_ "GenSigTimeoutTime_ALL" SG_ 1068 PSM_D_DrvTrackPos 1000;
BA_ "InvalidValue" SG_ 1068 PSM_D_DrvTrackPos "FFh";
BA_ "GenSigTimeoutTime_ALL" SG_ 1068 PSM_D_DrvHeightPos 1000;
BA_ "InvalidValue" SG_ 1068 PSM_D_DrvHeightPos "3Fh";
BA_ "GenSigSendType" SG_ 1069 XGW_WasherFluid_LevelSwitch 3;
BA_ "InvalidValue" SG_ 1069 XGW_WasherFluid_LevelSwitch "3h";
BA_ "GenSigTimeoutTime_ALL" SG_ 1070 CHKSM_XGW_HCMInfo 500;
BA_ "GenSigTimeoutTime_ALL" SG_ 1070 ALV_XGW_HCMInfo 500;
BA_ "InvalidValue" SG_ 1070 ALV_XGW_HCMInfo "Fh";
BA_ "GenSigStartValue" SG_ 1070 XGW_HLVerLvlMode 1;
BA_ "GenSigTimeoutTime_ALL" SG_ 1070 XGW_HLVerLvlMode 500;
BA_ "InvalidValue" SG_ 1070 XGW_HLVerLvlMode "3h";
BA_ "GenSigTimeoutTime_ALL" SG_ 1070 XGW_AutoHeadlamp_LvlSts 500;
BA_ "InvalidValue" SG_ 1070 XGW_AutoHeadlamp_LvlSts "3h";
BA_ "GenSigTimeoutTime_ALL" SG_ 1073 HUD_ECU_Check 500;
BA_ "GenSigTimeoutTime_ALL" SG_ 1073 HUD_ECU_Fault 500;
BA_ "GenSigTimeoutTime_ALL" SG_ 1074 MHU_FOTA_Checksum 2500;
BA_ "InvalidValue" SG_ 1074 MHU_FOTA_Checksum "null";
BA_ "GenSigTimeoutTime_ALL" SG_ 1074 MHU_FOTA_Alive_Counter 2500;
BA_ "InvalidValue" SG_ 1074 MHU_FOTA_Alive_Counter "Fh";
BA_ "GenSigTimeoutTime_ALL" SG_ 1074 MHU_FOTA_State 2500;
BA_ "InvalidValue" SG_ 1074 MHU_FOTA_State "7h";
BA_ "GenSigTimeoutTime_ALL" SG_ 1074 MHU_FOTA_Error_Code 2500;
BA_ "InvalidValue" SG_ 1074 MHU_FOTA_Error_Code "null";
BA_ "GenSigTimeoutTime_ALL" SG_ 1075 MHU_Headlamp_Chksm 2500;
BA_ "InvalidValue" SG_ 1075 MHU_Headlamp_Chksm "Fh";
BA_ "GenSigTimeoutTime_ALL" SG_ 1075 MHU_Headlamp_Aliv 2500;
BA_ "InvalidValue" SG_ 1075 MHU_Headlamp_Aliv "Fh";
BA_ "GenSigStartValue" SG_ 1075 MHU_HLVerLvlMode 1;
BA_ "GenSigTimeoutTime_ALL" SG_ 1075 MHU_HLVerLvlMode 2500;
BA_ "GenSigSendType" SG_ 1077 BCM_SCM_BC_Button 4;
BA_ "InvalidValue" SG_ 1077 BCM_SCM_BC_Button "3h";
BA_ "GenSigSendType" SG_ 1078 MHU_TELStatus 2;
BA_ "GenSigStartValue" SG_ 1078 MHU_TELStatus 7;
BA_ "InvalidValue" SG_ 1078 MHU_TELStatus "7h";
BA_ "GenSigSendType" SG_ 1078 MHU_MUTEStatus 2;
BA_ "InvalidValue" SG_ 1078 MHU_MUTEStatus "3h";
BA_ "GenSigSendType" SG_ 1078 MHU_TEL_source 2;
BA_ "InvalidValue" SG_ 1078 MHU_TEL_source "7h";
BA_ "GenSigSendType" SG_ 1078 SECCAN_HUD_info 2;
BA_ "GenSigTimeoutTime_ALL" SG_ 1079 CRC_VCU_MHU_info_2 1000;
BA_ "GenSigTimeoutTime_ALL" SG_ 1079 ALIV_VCU_MHU_info_2 1000;
BA_ "InvalidValue" SG_ 1079 ALIV_VCU_MHU_info_2 "Fh";
BA_ "GenSigTimeoutTime_ALL" SG_ 1079 VCU_Instant_ConsumEnergy 1000;
BA_ "InvalidValue" SG_ 1079 VCU_Instant_ConsumEnergy "3FFh";
BA_ "GenSigTimeoutTime_ALL" SG_ 1079 VCU_Average_ConsumEnergy 1000;
BA_ "InvalidValue" SG_ 1079 VCU_Average_ConsumEnergy "3FFh";
BA_ "GenSigTimeoutTime_ALL" SG_ 1079 VCU_SpdLimiterSts 1000;
BA_ "GenSigTimeoutTime_ALL" SG_ 1079 VCU_LimiterSpeed 1000;
BA_ "InvalidValue" SG_ 1079 VCU_LimiterSpeed "FFh";
BA_ "GenSigTimeoutTime_ALL" SG_ 1079 VCU_SpdLim_OverrideSts 1000;
BA_ "GenSigTimeoutTime_ALL" SG_ 1080 CHKSM_EDS_Error_FR_A 500;
BA_ "InvalidValue" SG_ 1080 CHKSM_EDS_Error_FR_A "";
BA_ "GenSigTimeoutTime_ALL" SG_ 1080 ALV_EDS_Error_FR_A 500;
BA_ "InvalidValue" SG_ 1080 ALV_EDS_Error_FR_A "Fh";
BA_ "GenSigTimeoutTime_ALL" SG_ 1080 EDS_FailNum_ERR_FWD 500;
BA_ "InvalidValue" SG_ 1080 EDS_FailNum_ERR_FWD "";
BA_ "GenSigTimeoutTime_ALL" SG_ 1080 EDS_FailGrade_ERR_FWD 500;
BA_ "InvalidValue" SG_ 1080 EDS_FailGrade_ERR_FWD "7h";
BA_ "GenSigTimeoutTime_ALL" SG_ 1080 EDS_MotOverTempAlarm_FWD 500;
BA_ "InvalidValue" SG_ 1080 EDS_MotOverTempAlarm_FWD "";
BA_ "GenSigTimeoutTime_ALL" SG_ 1080 EDS_MotOverTempFault_FWD 500;
BA_ "InvalidValue" SG_ 1080 EDS_MotOverTempFault_FWD "";
BA_ "GenSigTimeoutTime_ALL" SG_ 1080 EDS_MotTempSenFault_FWD 500;
BA_ "InvalidValue" SG_ 1080 EDS_MotTempSenFault_FWD "";
BA_ "GenSigTimeoutTime_ALL" SG_ 1080 EDS_EDSOverTempUFault_FWD 500;
BA_ "InvalidValue" SG_ 1080 EDS_EDSOverTempUFault_FWD "";
BA_ "GenSigTimeoutTime_ALL" SG_ 1080 EDS_EDSOverTempVFault_FWD 500;
BA_ "InvalidValue" SG_ 1080 EDS_EDSOverTempVFault_FWD "";
BA_ "GenSigTimeoutTime_ALL" SG_ 1080 EDS_EDSOverTempWFault_FWD 500;
BA_ "InvalidValue" SG_ 1080 EDS_EDSOverTempWFault_FWD "";
BA_ "GenSigTimeoutTime_ALL" SG_ 1080 EDS_EDSOverTempAlarm_FWD 500;
BA_ "InvalidValue" SG_ 1080 EDS_EDSOverTempAlarm_FWD "";
BA_ "GenSigTimeoutTime_ALL" SG_ 1080 EDS_TCoolantOvHi_FWD 500;
BA_ "InvalidValue" SG_ 1080 EDS_TCoolantOvHi_FWD "";
BA_ "GenSigTimeoutTime_ALL" SG_ 1080 EDS_EDSTempCmpAlarm_FWD 500;
BA_ "InvalidValue" SG_ 1080 EDS_EDSTempCmpAlarm_FWD "";
BA_ "GenSigTimeoutTime_ALL" SG_ 1080 EDS_EDSPhaOvCurentHWFault_FWD 500;
BA_ "InvalidValue" SG_ 1080 EDS_EDSPhaOvCurentHWFault_FWD "";
BA_ "GenSigTimeoutTime_ALL" SG_ 1080 EDS_EDSphaOffCalFault_FWD 500;
BA_ "InvalidValue" SG_ 1080 EDS_EDSphaOffCalFault_FWD "";
BA_ "GenSigTimeoutTime_ALL" SG_ 1080 EDS_EDSOverIdcLnkAlarm_FWD 500;
BA_ "InvalidValue" SG_ 1080 EDS_EDSOverIdcLnkAlarm_FWD "";
BA_ "GenSigTimeoutTime_ALL" SG_ 1080 EDS_EDSHVOverVoltageAlarm_FWD 500;
BA_ "InvalidValue" SG_ 1080 EDS_EDSHVOverVoltageAlarm_FWD "";
BA_ "GenSigTimeoutTime_ALL" SG_ 1080 EDS_EDSHVOverVoltageFault_FWD 500;
BA_ "InvalidValue" SG_ 1080 EDS_EDSHVOverVoltageFault_FWD "";
BA_ "GenSigTimeoutTime_ALL" SG_ 1080 EDS_EDSHVUnderVoltageAlarm_FWD 500;
BA_ "InvalidValue" SG_ 1080 EDS_EDSHVUnderVoltageAlarm_FWD "";
BA_ "GenSigTimeoutTime_ALL" SG_ 1080 EDS_EDSHVUnderVoltageFault_FWD 500;
BA_ "InvalidValue" SG_ 1080 EDS_EDSHVUnderVoltageFault_FWD "";
BA_ "GenSigTimeoutTime_ALL" SG_ 1080 EDS_RunToDischaErr_FWD 500;
BA_ "InvalidValue" SG_ 1080 EDS_RunToDischaErr_FWD "";
BA_ "GenSigTimeoutTime_ALL" SG_ 1080 EDS_12VOverVoltageAlarm_FWD 500;
BA_ "InvalidValue" SG_ 1080 EDS_12VOverVoltageAlarm_FWD "";
BA_ "GenSigTimeoutTime_ALL" SG_ 1080 EDS_12VUnderVoltageAlarm_FWD 500;
BA_ "InvalidValue" SG_ 1080 EDS_12VUnderVoltageAlarm_FWD "";
BA_ "GenSigTimeoutTime_ALL" SG_ 1080 EDS_MotOverAlarm_FWD 500;
BA_ "InvalidValue" SG_ 1080 EDS_MotOverAlarm_FWD "";
BA_ "GenSigTimeoutTime_ALL" SG_ 1080 EDS_MotOverFault_FWD 500;
BA_ "InvalidValue" SG_ 1080 EDS_MotOverFault_FWD "";
BA_ "GenSigTimeoutTime_ALL" SG_ 1080 EDS_ResolverOffsetAngle_FWD 500;
BA_ "GenSigTimeoutTime_ALL" SG_ 1080 SECCAN_EDS_Error_FR_A 500;
BA_ "InvalidValue" SG_ 1080 SECCAN_EDS_Error_FR_A "";
BA_ "GenSigTimeoutTime_ALL" SG_ 1081 CHKSM_EDS_Error_RR_A 500;
BA_ "InvalidValue" SG_ 1081 CHKSM_EDS_Error_RR_A "";
BA_ "GenSigTimeoutTime_ALL" SG_ 1081 ALV_EDS_Error_RR_A 500;
BA_ "InvalidValue" SG_ 1081 ALV_EDS_Error_RR_A "Fh";
BA_ "GenSigTimeoutTime_ALL" SG_ 1081 EDS_FailNum_ERR_RWD 500;
BA_ "InvalidValue" SG_ 1081 EDS_FailNum_ERR_RWD "";
BA_ "GenSigTimeoutTime_ALL" SG_ 1081 EDS_FailGrade_ERR_RWD 500;
BA_ "InvalidValue" SG_ 1081 EDS_FailGrade_ERR_RWD "7h";
BA_ "GenSigTimeoutTime_ALL" SG_ 1081 EDS_MotOverTempAlarm_RWD 500;
BA_ "InvalidValue" SG_ 1081 EDS_MotOverTempAlarm_RWD "";
BA_ "GenSigTimeoutTime_ALL" SG_ 1081 EDS_MotOverTempFault_RWD 500;
BA_ "InvalidValue" SG_ 1081 EDS_MotOverTempFault_RWD "";
BA_ "GenSigTimeoutTime_ALL" SG_ 1081 EDS_MotTempSenFault_RWD 500;
BA_ "InvalidValue" SG_ 1081 EDS_MotTempSenFault_RWD "";
BA_ "GenSigTimeoutTime_ALL" SG_ 1081 EDS_EDSOverTempUFault_RWD 500;
BA_ "InvalidValue" SG_ 1081 EDS_EDSOverTempUFault_RWD "";
BA_ "GenSigTimeoutTime_ALL" SG_ 1081 EDS_EDSOverTempVFault_RWD 500;
BA_ "InvalidValue" SG_ 1081 EDS_EDSOverTempVFault_RWD "";
BA_ "GenSigTimeoutTime_ALL" SG_ 1081 EDS_EDSOverTempWFault_RWD 500;
BA_ "InvalidValue" SG_ 1081 EDS_EDSOverTempWFault_RWD "";
BA_ "GenSigTimeoutTime_ALL" SG_ 1081 EDS_EDSOverTempAlarm_RWD 500;
BA_ "InvalidValue" SG_ 1081 EDS_EDSOverTempAlarm_RWD "";
BA_ "GenSigTimeoutTime_ALL" SG_ 1081 EDS_TCoolantOvHi_RWD 500;
BA_ "InvalidValue" SG_ 1081 EDS_TCoolantOvHi_RWD "";
BA_ "GenSigTimeoutTime_ALL" SG_ 1081 EDS_EDSTempCmpAlarm_RWD 500;
BA_ "InvalidValue" SG_ 1081 EDS_EDSTempCmpAlarm_RWD "";
BA_ "GenSigTimeoutTime_ALL" SG_ 1081 EDS_EDSPhaOvCurentHWFault_RWD 500;
BA_ "InvalidValue" SG_ 1081 EDS_EDSPhaOvCurentHWFault_RWD "";
BA_ "GenSigTimeoutTime_ALL" SG_ 1081 EDS_EDSphaOffCalFault_RWD 500;
BA_ "InvalidValue" SG_ 1081 EDS_EDSphaOffCalFault_RWD "";
BA_ "GenSigTimeoutTime_ALL" SG_ 1081 EDS_EDSOverIdcLnkAlarm_RWD 500;
BA_ "InvalidValue" SG_ 1081 EDS_EDSOverIdcLnkAlarm_RWD "";
BA_ "GenSigTimeoutTime_ALL" SG_ 1081 EDS_EDSHVOverVoltageAlarm_RWD 500;
BA_ "InvalidValue" SG_ 1081 EDS_EDSHVOverVoltageAlarm_RWD "";
BA_ "GenSigTimeoutTime_ALL" SG_ 1081 EDS_EDSHVOverVoltageFault_RWD 500;
BA_ "InvalidValue" SG_ 1081 EDS_EDSHVOverVoltageFault_RWD "";
BA_ "GenSigTimeoutTime_ALL" SG_ 1081 EDS_EDSHVUnderVoltageAlarm_RWD 500;
BA_ "InvalidValue" SG_ 1081 EDS_EDSHVUnderVoltageAlarm_RWD "";
BA_ "GenSigTimeoutTime_ALL" SG_ 1081 EDS_EDSHVUnderVoltageFault_RWD 500;
BA_ "InvalidValue" SG_ 1081 EDS_EDSHVUnderVoltageFault_RWD "";
BA_ "GenSigTimeoutTime_ALL" SG_ 1081 EDS_RunToDischaErr_RWD 500;
BA_ "InvalidValue" SG_ 1081 EDS_RunToDischaErr_RWD "";
BA_ "GenSigTimeoutTime_ALL" SG_ 1081 EDS_12VOverVoltageAlarm_RWD 500;
BA_ "InvalidValue" SG_ 1081 EDS_12VOverVoltageAlarm_RWD "";
BA_ "GenSigTimeoutTime_ALL" SG_ 1081 EDS_12VUnderVoltageAlarm_RWD 500;
BA_ "InvalidValue" SG_ 1081 EDS_12VUnderVoltageAlarm_RWD "";
BA_ "GenSigTimeoutTime_ALL" SG_ 1081 EDS_MotOverAlarm_RWD 500;
BA_ "InvalidValue" SG_ 1081 EDS_MotOverAlarm_RWD "";
BA_ "GenSigTimeoutTime_ALL" SG_ 1081 EDS_MotOverFault_RWD 500;
BA_ "InvalidValue" SG_ 1081 EDS_MotOverFault_RWD "";
BA_ "GenSigTimeoutTime_ALL" SG_ 1081 EDS_ResolverOffsetAngle_RWD 500;
BA_ "GenSigTimeoutTime_ALL" SG_ 1081 SECCAN_EDS_Error_RR_A 500;
BA_ "InvalidValue" SG_ 1081 SECCAN_EDS_Error_RR_A "";
BA_ "InvalidValue" SG_ 1082 VCU_AutoP_Feedback "3h";
BA_ "GenSigTimeoutTime_ALL" SG_ 1082 VCU_AutoP_Feedback 500;
BA_ "GenSigTimeoutTime_ALL" SG_ 1082 CRC_VCU_MHU_info 500;
BA_ "InvalidValue" SG_ 1082 CRC_VCU_MHU_info "null";
BA_ "GenSigTimeoutTime_ALL" SG_ 1082 ALIV_VCU_MHU_info 500;
BA_ "InvalidValue" SG_ 1082 ALIV_VCU_MHU_info "Fh";
BA_ "GenSigTimeoutTime_ALL" SG_ 1082 VCU_BrakeRegenMode 500;
BA_ "InvalidValue" SG_ 1082 VCU_BrakeRegenMode "";
BA_ "GenSigTimeoutTime_ALL" SG_ 1082 VCU_CreepDisable_stt 500;
BA_ "InvalidValue" SG_ 1082 VCU_CreepDisable_stt "null";
BA_ "GenSigStartValue" SG_ 1082 VCU_PowerRegenGaugeDisplay 100;
BA_ "GenSigTimeoutTime_ALL" SG_ 1082 VCU_PowerRegenGaugeDisplay 500;
BA_ "InvalidValue" SG_ 1082 VCU_PowerRegenGaugeDisplay "FFh";
BA_ "GenSigTimeoutTime_ALL" SG_ 1082 VCU_Charging_Authen_stt 500;
BA_ "InvalidValue" SG_ 1082 VCU_Charging_Authen_stt "null";
BA_ "GenSigTimeoutTime_ALL" SG_ 1082 VCU_ChgGun_BadConn_stt 500;
BA_ "InvalidValue" SG_ 1082 VCU_ChgGun_BadConn_stt "null";
BA_ "GenSigTimeoutTime_ALL" SG_ 1082 VCU_ChgPort_Open_stt 500;
BA_ "InvalidValue" SG_ 1082 VCU_ChgPort_Open_stt "null";
BA_ "GenSigStartValue" SG_ 1082 VCU_Regen_available 1;
BA_ "GenSigTimeoutTime_ALL" SG_ 1082 VCU_Regen_available 500;
BA_ "InvalidValue" SG_ 1082 VCU_Regen_available "null";
BA_ "GenSigTimeoutTime_ALL" SG_ 1082 VCU_VehChg_STS 500;
BA_ "InvalidValue" SG_ 1082 VCU_VehChg_STS "null";
BA_ "GenSigTimeoutTime_ALL" SG_ 1082 VCU_StoppingMode_stt 500;
BA_ "GenSigTimeoutTime_ALL" SG_ 1082 VCU_SOC_display 500;
BA_ "InvalidValue" SG_ 1082 VCU_SOC_display "null";
BA_ "GenSigStartValue" SG_ 1082 VCU_ChgGun_Status 7;
BA_ "GenSigTimeoutTime_ALL" SG_ 1082 VCU_ChgGun_Status 500;
BA_ "InvalidValue" SG_ 1082 VCU_ChgGun_Status "7h";
BA_ "GenSigTimeoutTime_ALL" SG_ 1082 VCU_ChgPort_Lock_stt 500;
BA_ "InvalidValue" SG_ 1082 VCU_ChgPort_Lock_stt "null";
BA_ "GenSigTimeoutTime_ALL" SG_ 1082 VCU_Hvbatt_charging_stt 500;
BA_ "InvalidValue" SG_ 1082 VCU_Hvbatt_charging_stt "null";
BA_ "GenSigSendType" SG_ 1083 MHU_SET_TiltPos 2;
BA_ "InvalidValue" SG_ 1083 MHU_SET_TiltPos "FFh";
BA_ "GenSigSendType" SG_ 1083 MHU_SET_TelePos 2;
BA_ "InvalidValue" SG_ 1083 MHU_SET_TelePos "FFh";
BA_ "GenSigSendType" SG_ 1083 MHU_SET_SteeringAdjust 2;
BA_ "InvalidValue" SG_ 1083 MHU_SET_SteeringAdjust "null";
BA_ "GenSigSendType" SG_ 1084 EASC_TiltPos 3;
BA_ "InvalidValue" SG_ 1084 EASC_TiltPos "FFh";
BA_ "GenSigSendType" SG_ 1084 EASC_TelePos 3;
BA_ "InvalidValue" SG_ 1084 EASC_TelePos "FFh";
BA_ "GenSigSendType" SG_ 1084 EASC_SteeringAdjust 4;
BA_ "InvalidValue" SG_ 1084 EASC_SteeringAdjust "null";
BA_ "GenSigStartValue" SG_ 1086 MHU_SET_Mediavolume 15;
BA_ "GenSigTimeoutTime_ALL" SG_ 1086 MHU_SET_Mediavolume 500;
BA_ "InvalidValue" SG_ 1086 MHU_SET_Mediavolume "FFh";
BA_ "GenSigTimeoutTime_ALL" SG_ 1086 MHU_SET_Soundzone 500;
BA_ "InvalidValue" SG_ 1086 MHU_SET_Soundzone "0";
BA_ "GenSigStartValue" SG_ 1086 MHU_SET_Bass 6;
BA_ "GenSigTimeoutTime_ALL" SG_ 1086 MHU_SET_Bass 500;
BA_ "InvalidValue" SG_ 1086 MHU_SET_Bass "1Fh";
BA_ "GenSigStartValue" SG_ 1086 MHU_SET_Fader 10;
BA_ "GenSigTimeoutTime_ALL" SG_ 1086 MHU_SET_Fader 500;
BA_ "InvalidValue" SG_ 1086 MHU_SET_Fader "1Fh";
BA_ "GenSigStartValue" SG_ 1086 MHU_SET_MediaMute 1;
BA_ "GenSigTimeoutTime_ALL" SG_ 1086 MHU_SET_MediaMute 500;
BA_ "InvalidValue" SG_ 1086 MHU_SET_MediaMute "3h";
BA_ "GenSigStartValue" SG_ 1086 MHU_SET_MidPitch 6;
BA_ "GenSigTimeoutTime_ALL" SG_ 1086 MHU_SET_MidPitch 500;
BA_ "InvalidValue" SG_ 1086 MHU_SET_MidPitch "1Fh";
BA_ "GenSigStartValue" SG_ 1086 MHU_SET_Treble 6;
BA_ "GenSigTimeoutTime_ALL" SG_ 1086 MHU_SET_Treble 500;
BA_ "InvalidValue" SG_ 1086 MHU_SET_Treble "1Fh";
BA_ "GenSigStartValue" SG_ 1086 MHU_SET_Balance 10;
BA_ "GenSigTimeoutTime_ALL" SG_ 1086 MHU_SET_Balance 500;
BA_ "InvalidValue" SG_ 1086 MHU_SET_Balance "1Fh";
BA_ "GenSigStartValue" SG_ 1087 MHU_SET_EQ_1000HZ 6;
BA_ "GenSigTimeoutTime_ALL" SG_ 1087 MHU_SET_EQ_1000HZ 500;
BA_ "InvalidValue" SG_ 1087 MHU_SET_EQ_1000HZ "1Fh";
BA_ "GenSigTimeoutTime_ALL" SG_ 1087 MHU_SET_EQ_16000HZ 500;
BA_ "InvalidValue" SG_ 1087 MHU_SET_EQ_16000HZ "1Fh";
BA_ "GenSigStartValue" SG_ 1087 MHU_SET_EQ_250HZ 6;
BA_ "GenSigTimeoutTime_ALL" SG_ 1087 MHU_SET_EQ_250HZ 500;
BA_ "InvalidValue" SG_ 1087 MHU_SET_EQ_250HZ "1Fh";
BA_ "GenSigTimeoutTime_ALL" SG_ 1087 MHU_SET_EQ_4000HZ 500;
BA_ "InvalidValue" SG_ 1087 MHU_SET_EQ_4000HZ "1Fh";
BA_ "GenSigStartValue" SG_ 1087 MHU_SET_EQ_60HZ 6;
BA_ "GenSigTimeoutTime_ALL" SG_ 1087 MHU_SET_EQ_60HZ 500;
BA_ "InvalidValue" SG_ 1087 MHU_SET_EQ_60HZ "1Fh";
BA_ "GenSigTimeoutTime_ALL" SG_ 1087 MHU_SET_EQType 500;
BA_ "InvalidValue" SG_ 1087 MHU_SET_EQType "Fh";
BA_ "GenSigStartValue" SG_ 1088 AMP_SET_EQ_1000HZ 6;
BA_ "GenSigTimeoutTime_ALL" SG_ 1088 AMP_SET_EQ_1000HZ 500;
BA_ "InvalidValue" SG_ 1088 AMP_SET_EQ_1000HZ "1Fh";
BA_ "GenSigTimeoutTime_ALL" SG_ 1088 AMP_SET_EQ_16000HZ 500;
BA_ "InvalidValue" SG_ 1088 AMP_SET_EQ_16000HZ "1Fh";
BA_ "GenSigStartValue" SG_ 1088 AMP_SET_EQ_250HZ 6;
BA_ "GenSigTimeoutTime_ALL" SG_ 1088 AMP_SET_EQ_250HZ 500;
BA_ "InvalidValue" SG_ 1088 AMP_SET_EQ_250HZ "1Fh";
BA_ "GenSigTimeoutTime_ALL" SG_ 1088 AMP_SET_EQ_4000HZ 500;
BA_ "InvalidValue" SG_ 1088 AMP_SET_EQ_4000HZ "1Fh";
BA_ "GenSigStartValue" SG_ 1088 AMP_SET_EQ_60HZ 6;
BA_ "GenSigTimeoutTime_ALL" SG_ 1088 AMP_SET_EQ_60HZ 500;
BA_ "InvalidValue" SG_ 1088 AMP_SET_EQ_60HZ "1Fh";
BA_ "GenSigTimeoutTime_ALL" SG_ 1088 AMP_SET_EQType 500;
BA_ "InvalidValue" SG_ 1088 AMP_SET_EQType "Fh";
BA_ "GenSigTimeoutTime_ALL" SG_ 1090 WLC_IC_Error 2500;
BA_ "InvalidValue" SG_ 1090 WLC_IC_Error "null";
BA_ "GenSigTimeoutTime_ALL" SG_ 1090 WLC_FAN_Error 2500;
BA_ "InvalidValue" SG_ 1090 WLC_FAN_Error "null";
BA_ "GenSigTimeoutTime_ALL" SG_ 1090 WLC_TempSNSR_Error 2500;
BA_ "InvalidValue" SG_ 1090 WLC_TempSNSR_Error "null";
BA_ "GenSigStartValue" SG_ 1090 WLC_Setting_standard 2;
BA_ "GenSigTimeoutTime_ALL" SG_ 1090 WLC_Setting_standard 2500;
BA_ "InvalidValue" SG_ 1090 WLC_Setting_standard "null";
BA_ "GenSigTimeoutTime_ALL" SG_ 1090 Transmit_WLC_situation 2500;
BA_ "InvalidValue" SG_ 1090 Transmit_WLC_situation "null";
BA_ "GenSigTimeoutTime_ALL" SG_ 1090 WLC_VehSpeed_Error 2500;
BA_ "InvalidValue" SG_ 1090 WLC_VehSpeed_Error "null";
BA_ "GenSigTimeoutTime_ALL" SG_ 1090 WLC_Resp_Error 2500;
BA_ "InvalidValue" SG_ 1090 WLC_Resp_Error "null";
BA_ "GenSigTimeoutTime_ALL" SG_ 1090 WLC_FOD_Error 2500;
BA_ "InvalidValue" SG_ 1090 WLC_FOD_Error "null";
BA_ "GenSigTimeoutTime_ALL" SG_ 1090 WLC_Curr_Error 2500;
BA_ "InvalidValue" SG_ 1090 WLC_Curr_Error "null";
BA_ "GenSigTimeoutTime_ALL" SG_ 1090 WLC_Temp_Error 2500;
BA_ "InvalidValue" SG_ 1090 WLC_Temp_Error "null";
BA_ "GenSigTimeoutTime_ALL" SG_ 1091 WLC_IC_Error_2 2500;
BA_ "InvalidValue" SG_ 1091 WLC_IC_Error_2 "null";
BA_ "GenSigTimeoutTime_ALL" SG_ 1091 WLC_FAN_Error_2 2500;
BA_ "InvalidValue" SG_ 1091 WLC_FAN_Error_2 "null";
BA_ "GenSigTimeoutTime_ALL" SG_ 1091 WLC_TempSNSR_Error_2 2500;
BA_ "InvalidValue" SG_ 1091 WLC_TempSNSR_Error_2 "null";
BA_ "GenSigStartValue" SG_ 1091 WLC_Setting_standard_2 2;
BA_ "GenSigTimeoutTime_ALL" SG_ 1091 WLC_Setting_standard_2 2500;
BA_ "InvalidValue" SG_ 1091 WLC_Setting_standard_2 "null";
BA_ "GenSigTimeoutTime_ALL" SG_ 1091 Transmit_WLC_situation_2 2500;
BA_ "InvalidValue" SG_ 1091 Transmit_WLC_situation_2 "null";
BA_ "GenSigTimeoutTime_ALL" SG_ 1091 WLC_VehSpeed_Error_2 2500;
BA_ "InvalidValue" SG_ 1091 WLC_VehSpeed_Error_2 "null";
BA_ "GenSigTimeoutTime_ALL" SG_ 1091 WLC_Resp_Error_2 2500;
BA_ "InvalidValue" SG_ 1091 WLC_Resp_Error_2 "null";
BA_ "GenSigTimeoutTime_ALL" SG_ 1091 WLC_FOD_Error_2 2500;
BA_ "InvalidValue" SG_ 1091 WLC_FOD_Error_2 "null";
BA_ "GenSigTimeoutTime_ALL" SG_ 1091 WLC_Curr_Error_2 2500;
BA_ "InvalidValue" SG_ 1091 WLC_Curr_Error_2 "null";
BA_ "GenSigTimeoutTime_ALL" SG_ 1091 WLC_Temp_Error_2 2500;
BA_ "InvalidValue" SG_ 1091 WLC_Temp_Error_2 "null";
BA_ "GenSigTimeoutTime_ALL" SG_ 1092 Checksum_MHU_ADAS_RP_Ctrl 1000;
BA_ "InvalidValue" SG_ 1092 Checksum_MHU_ADAS_RP_Ctrl "null";
BA_ "GenSigTimeoutTime_ALL" SG_ 1092 Rolling_Counter_MHU_ADAS_RP_Ctrl 1000;
BA_ "InvalidValue" SG_ 1092 Rolling_Counter_MHU_ADAS_RP_Ctrl "Fh";
BA_ "GenSigTimeoutTime_ALL" SG_ 1092 MHU_RPParkingstartReq 1000;
BA_ "GenSigTimeoutTime_ALL" SG_ 1092 MHU_RP_ParkOutModeConfirm 1000;
BA_ "InvalidValue" SG_ 1092 MHU_RP_ParkOutModeConfirm "3h";
BA_ "GenSigTimeoutTime_ALL" SG_ 1092 MHU_RP_ParkOutDircnConfirm 1000;
BA_ "InvalidValue" SG_ 1092 MHU_RP_ParkOutDircnConfirm "3h";
BA_ "GenSigTimeoutTime_ALL" SG_ 1092 MHU_RemoteconnectionSts 1000;
BA_ "InvalidValue" SG_ 1092 MHU_RemoteconnectionSts "3h";
BA_ "GenSigTimeoutTime_ALL" SG_ 1092 MHU_RP_FuncMode 1000;
BA_ "InvalidValue" SG_ 1092 MHU_RP_FuncMode "null";
BA_ "GenSigTimeoutTime_ALL" SG_ 1092 MHU_SMParkingstartReq 1000;
BA_ "InvalidValue" SG_ 1092 MHU_SMParkingstartReq "null";
BA_ "GenSigTimeoutTime_ALL" SG_ 1092 MHU_SMParkingControlReq 1000;
BA_ "InvalidValue" SG_ 1092 MHU_SMParkingControlReq "null";
BA_ "GenSigTimeoutTime_ALL" SG_ 1092 MHU_RP_RecoverParking 1000;
BA_ "GenSigTimeoutTime_ALL" SG_ 1092 MHU_RPStraightParkingDir 1000;
BA_ "InvalidValue" SG_ 1092 MHU_RPStraightParkingDir "3h";
BA_ "GenSigTimeoutTime_ALL" SG_ 1092 MHU_SM_global_path_Status 1000;
BA_ "InvalidValue" SG_ 1092 MHU_SM_global_path_Status "null";
BA_ "GenSigTimeoutTime_ALL" SG_ 1092 MHU_SM_QuitReq 1000;
BA_ "InvalidValue" SG_ 1092 MHU_SM_QuitReq "null";
BA_ "GenSigTimeoutTime_ALL" SG_ 1092 MHU_RPParkingControlReq 1000;
BA_ "GenSigTimeoutTime_ALL" SG_ 1092 MHU_RP_QuitReq 1000;
BA_ "GenSigTimeoutTime_ALL" SG_ 1092 SECCAN_ADAS_RP_Ctrl 1000;
BA_ "GenSigTimeoutTime_ALL" SG_ 1093 RS_Sol_L 500;
BA_ "InvalidValue" SG_ 1093 RS_Sol_L "FFh";
BA_ "GenSigTimeoutTime_ALL" SG_ 1093 RS_Sol_R 500;
BA_ "InvalidValue" SG_ 1093 RS_Sol_R "FFh";
BA_ "GenSigTimeoutTime_ALL" SG_ 1093 RS_F_LightSensor 500;
BA_ "GenSigTimeoutTime_ALL" SG_ 1093 RS_F_HUD_Sensor 500;
BA_ "InvalidValue" SG_ 1093 RS_F_HUD_Sensor "null";
BA_ "GenSigTimeoutTime_ALL" SG_ 1093 RS_St_LampReq 500;
BA_ "InvalidValue" SG_ 1093 RS_St_LampReq "3h";
BA_ "GenSigTimeoutTime_ALL" SG_ 1093 RS_St_CurrentRain 500;
BA_ "InvalidValue" SG_ 1093 RS_St_CurrentRain "7h";
BA_ "GenSigTimeoutTime_ALL" SG_ 1093 RS_HUD_illuminance 500;
BA_ "InvalidValue" SG_ 1093 RS_HUD_illuminance "FFFFh";
BA_ "GenSigSendType" SG_ 1094 MHU_TBT_Icon 1;
BA_ "GenSigSendType" SG_ 1094 MHU_Junction_MsgNum 1;
BA_ "GenSigStartValue" SG_ 1094 MHU_Junction_MsgNum 1;
BA_ "GenSigSendType" SG_ 1094 MHU_Junction_TotalMsg 1;
BA_ "GenSigStartValue" SG_ 1094 MHU_Junction_TotalMsg 1;
BA_ "GenSigSendType" SG_ 1094 MHU_DrivingSide 1;
BA_ "GenSigSendType" SG_ 1094 MHU_Junction_type 1;
BA_ "InvalidValue" SG_ 1094 MHU_Junction_type "3h";
BA_ "GenSigSendType" SG_ 1094 MHU_JunctionElement1 1;
BA_ "InvalidValue" SG_ 1094 MHU_JunctionElement1 "1Fh";
BA_ "GenSigSendType" SG_ 1094 MHU_JunctionElement0 1;
BA_ "InvalidValue" SG_ 1094 MHU_JunctionElement0 "1Fh";
BA_ "GenSigSendType" SG_ 1094 MHU_JunctionElement2 1;
BA_ "InvalidValue" SG_ 1094 MHU_JunctionElement2 "1Fh";
BA_ "GenSigSendType" SG_ 1094 MHU_JunctionElement4 1;
BA_ "InvalidValue" SG_ 1094 MHU_JunctionElement4 "1Fh";
BA_ "GenSigSendType" SG_ 1094 MHU_JunctionElement3 1;
BA_ "InvalidValue" SG_ 1094 MHU_JunctionElement3 "1Fh";
BA_ "GenSigSendType" SG_ 1094 MHU_JunctionElement5 1;
BA_ "InvalidValue" SG_ 1094 MHU_JunctionElement5 "1Fh";
BA_ "GenSigSendType" SG_ 1094 MHU_JunctionElement6 1;
BA_ "InvalidValue" SG_ 1094 MHU_JunctionElement6 "1Fh";
BA_ "GenSigTimeoutTime_ALL" SG_ 1095 MHU_SET_TransportMode 1000;
BA_ "InvalidValue" SG_ 1095 MHU_SET_TransportMode "3h";
BA_ "GenSigTimeoutTime_ALL" SG_ 1095 CHKSM_MHU_SET_CarMode 1000;
BA_ "InvalidValue" SG_ 1095 CHKSM_MHU_SET_CarMode "null";
BA_ "GenSigTimeoutTime_ALL" SG_ 1095 ALV_MHU_SET_CarMode 1000;
BA_ "InvalidValue" SG_ 1095 ALV_MHU_SET_CarMode "Fh";
BA_ "GenSigTimeoutTime_ALL" SG_ 1095 MHU_Request_CarOFF 1000;
BA_ "InvalidValue" SG_ 1095 MHU_Request_CarOFF "3h";
BA_ "GenSigTimeoutTime_ALL" SG_ 1095 MHU_SET_ChildMode 1000;
BA_ "InvalidValue" SG_ 1095 MHU_SET_ChildMode "3h";
BA_ "GenSigTimeoutTime_ALL" SG_ 1095 MHU_SET_GameMode 1000;
BA_ "InvalidValue" SG_ 1095 MHU_SET_GameMode "3h";
BA_ "GenSigTimeoutTime_ALL" SG_ 1095 MHU_SET_KaraokeMode 1000;
BA_ "InvalidValue" SG_ 1095 MHU_SET_KaraokeMode "3h";
BA_ "GenSigStartValue" SG_ 1095 MHU_Req_StoppingMode 4;
BA_ "GenSigTimeoutTime_ALL" SG_ 1095 MHU_Req_StoppingMode 1000;
BA_ "InvalidValue" SG_ 1095 MHU_Req_StoppingMode "7h";
BA_ "GenSigTimeoutTime_ALL" SG_ 1095 MHU_SET_WashMode 1000;
BA_ "InvalidValue" SG_ 1095 MHU_SET_WashMode "3h";
BA_ "GenSigTimeoutTime_ALL" SG_ 1095 MHU_SET_StopMode 1000;
BA_ "InvalidValue" SG_ 1095 MHU_SET_StopMode "3h";
BA_ "GenSigTimeoutTime_ALL" SG_ 1095 MHU_AVH_Sw 1000;
BA_ "InvalidValue" SG_ 1095 MHU_AVH_Sw "3h";
BA_ "GenSigTimeoutTime_ALL" SG_ 1096 CHKSM_EDS_Error_FR_B 500;
BA_ "InvalidValue" SG_ 1096 CHKSM_EDS_Error_FR_B "null";
BA_ "GenSigTimeoutTime_ALL" SG_ 1096 ALV_EDS_Error_FR_B 500;
BA_ "InvalidValue" SG_ 1096 ALV_EDS_Error_FR_B "Fh";
BA_ "GenSigTimeoutTime_ALL" SG_ 1096 EDS_iDcLnkOvCLimFail_FWD 500;
BA_ "InvalidValue" SG_ 1096 EDS_iDcLnkOvCLimFail_FWD "null";
BA_ "GenSigTimeoutTime_ALL" SG_ 1096 EDS_MotBlockedFault_FWD 500;
BA_ "InvalidValue" SG_ 1096 EDS_MotBlockedFault_FWD "null";
BA_ "GenSigTimeoutTime_ALL" SG_ 1096 EDS_RSLErr_FWD 500;
BA_ "InvalidValue" SG_ 1096 EDS_RSLErr_FWD "null";
BA_ "GenSigTimeoutTime_ALL" SG_ 1096 EDS_MotTrqLimFault_FWD 500;
BA_ "InvalidValue" SG_ 1096 EDS_MotTrqLimFault_FWD "null";
BA_ "GenSigTimeoutTime_ALL" SG_ 1096 EDS_VCUChksumFault_FWD 500;
BA_ "InvalidValue" SG_ 1096 EDS_VCUChksumFault_FWD "null";
BA_ "GenSigTimeoutTime_ALL" SG_ 1096 EDS_IGBTFault_FWD 500;
BA_ "InvalidValue" SG_ 1096 EDS_IGBTFault_FWD "null";
BA_ "GenSigTimeoutTime_ALL" SG_ 1096 EDS_CANBusoffFault_FWD 500;
BA_ "InvalidValue" SG_ 1096 EDS_CANBusoffFault_FWD "null";
BA_ "GenSigTimeoutTime_ALL" SG_ 1096 EDS_TDrvBoardOvHiWarn_FWD 500;
BA_ "InvalidValue" SG_ 1096 EDS_TDrvBoardOvHiWarn_FWD "null";
BA_ "GenSigTimeoutTime_ALL" SG_ 1096 EDS_TIGBTOvHiFault_FWD 500;
BA_ "InvalidValue" SG_ 1096 EDS_TIGBTOvHiFault_FWD "null";
BA_ "GenSigTimeoutTime_ALL" SG_ 1096 EDS_TIGBTOvHiWarn_FWD 500;
BA_ "InvalidValue" SG_ 1096 EDS_TIGBTOvHiWarn_FWD "null";
BA_ "GenSigTimeoutTime_ALL" SG_ 1096 EDS_IOHWABSampFail_FWD 500;
BA_ "InvalidValue" SG_ 1096 EDS_IOHWABSampFail_FWD "null";
BA_ "GenSigTimeoutTime_ALL" SG_ 1096 EDS_EDSOpenFault_FWD 500;
BA_ "InvalidValue" SG_ 1096 EDS_EDSOpenFault_FWD "null";
BA_ "GenSigTimeoutTime_ALL" SG_ 1096 EDS_MotorOpenFault_FWD 500;
BA_ "InvalidValue" SG_ 1096 EDS_MotorOpenFault_FWD "null";
BA_ "GenSigTimeoutTime_ALL" SG_ 1096 EDS_EparkSampFail_FWD 500;
BA_ "InvalidValue" SG_ 1096 EDS_EparkSampFail_FWD "null";
BA_ "GenSigTimeoutTime_ALL" SG_ 1096 EDS_EmacBlkdWarn_FWD 500;
BA_ "InvalidValue" SG_ 1096 EDS_EmacBlkdWarn_FWD "null";
BA_ "GenSigTimeoutTime_ALL" SG_ 1096 EDS_VerMatchFailureErr_FWD 500;
BA_ "InvalidValue" SG_ 1096 EDS_VerMatchFailureErr_FWD "null";
BA_ "GenSigTimeoutTime_ALL" SG_ 1096 EDS_DiashCirNoPsblErr_FWD 500;
BA_ "InvalidValue" SG_ 1096 EDS_DiashCirNoPsblErr_FWD "null";
BA_ "GenSigTimeoutTime_ALL" SG_ 1096 EDS_OperOutdRngErr_FWD 500;
BA_ "InvalidValue" SG_ 1096 EDS_OperOutdRngErr_FWD "null";
BA_ "GenSigTimeoutTime_ALL" SG_ 1096 EDS_PhaseLossFaultErr_FWD 500;
BA_ "InvalidValue" SG_ 1096 EDS_PhaseLossFaultErr_FWD "null";
BA_ "GenSigTimeoutTime_ALL" SG_ 1096 EDS_CPLDFault_FWD 500;
BA_ "InvalidValue" SG_ 1096 EDS_CPLDFault_FWD "null";
BA_ "GenSigTimeoutTime_ALL" SG_ 1096 EDS_CPLDFaultBaseSpd_FWD 500;
BA_ "InvalidValue" SG_ 1096 EDS_CPLDFaultBaseSpd_FWD "null";
BA_ "GenSigTimeoutTime_ALL" SG_ 1096 EDS_IOHWABNen33Fail_FWD 500;
BA_ "InvalidValue" SG_ 1096 EDS_IOHWABNen33Fail_FWD "null";
BA_ "GenSigTimeoutTime_ALL" SG_ 1096 EDS_HvMcuSlightFault_FWD 500;
BA_ "InvalidValue" SG_ 1096 EDS_HvMcuSlightFault_FWD "null";
BA_ "GenSigTimeoutTime_ALL" SG_ 1096 EDS_HvMcuSevFault_FWD 500;
BA_ "InvalidValue" SG_ 1096 EDS_HvMcuSevFault_FWD "null";
BA_ "GenSigTimeoutTime_ALL" SG_ 1096 EDS_EDSPhaSampHWFault_FWD 500;
BA_ "InvalidValue" SG_ 1096 EDS_EDSPhaSampHWFault_FWD "null";
BA_ "GenSigTimeoutTime_ALL" SG_ 1096 EDS_IsOvHiErr_FWD 500;
BA_ "InvalidValue" SG_ 1096 EDS_IsOvHiErr_FWD "null";
BA_ "GenSigTimeoutTime_ALL" SG_ 1096 EDS_CanRollingCounterErr_FWD 500;
BA_ "InvalidValue" SG_ 1096 EDS_CanRollingCounterErr_FWD "null";
BA_ "GenSigTimeoutTime_ALL" SG_ 1096 EDS_CanTimeoutErr_FWD 500;
BA_ "InvalidValue" SG_ 1096 EDS_CanTimeoutErr_FWD "null";
BA_ "GenSigTimeoutTime_ALL" SG_ 1096 EDS_CrashFault_FWD 500;
BA_ "InvalidValue" SG_ 1096 EDS_CrashFault_FWD "null";
BA_ "GenSigTimeoutTime_ALL" SG_ 1096 EDS_PCFSlightFault_FWD 500;
BA_ "InvalidValue" SG_ 1096 EDS_PCFSlightFault_FWD "null";
BA_ "GenSigTimeoutTime_ALL" SG_ 1096 EDS_PCFSerFault_FWD 500;
BA_ "InvalidValue" SG_ 1096 EDS_PCFSerFault_FWD "null";
BA_ "GenSigTimeoutTime_ALL" SG_ 1096 SECCAN_EDS_Error_FR_B 500;
BA_ "InvalidValue" SG_ 1096 SECCAN_EDS_Error_FR_B "null";
BA_ "GenSigTimeoutTime_ALL" SG_ 1097 CHKSM_EDS_Error_RR_B 500;
BA_ "InvalidValue" SG_ 1097 CHKSM_EDS_Error_RR_B "null";
BA_ "GenSigTimeoutTime_ALL" SG_ 1097 ALV_EDS_Error_RR_B 500;
BA_ "InvalidValue" SG_ 1097 ALV_EDS_Error_RR_B "Fh";
BA_ "GenSigTimeoutTime_ALL" SG_ 1097 EDS_iDcLnkOvCLimFail_RWD 500;
BA_ "InvalidValue" SG_ 1097 EDS_iDcLnkOvCLimFail_RWD "null";
BA_ "GenSigTimeoutTime_ALL" SG_ 1097 EDS_MotBlockedFault_RWD 500;
BA_ "InvalidValue" SG_ 1097 EDS_MotBlockedFault_RWD "null";
BA_ "GenSigTimeoutTime_ALL" SG_ 1097 EDS_RSLErr_RWD 500;
BA_ "InvalidValue" SG_ 1097 EDS_RSLErr_RWD "null";
BA_ "GenSigTimeoutTime_ALL" SG_ 1097 EDS_MotTrqLimFault_RWD 500;
BA_ "InvalidValue" SG_ 1097 EDS_MotTrqLimFault_RWD "null";
BA_ "GenSigTimeoutTime_ALL" SG_ 1097 EDS_VCUChksumFault_RWD 500;
BA_ "InvalidValue" SG_ 1097 EDS_VCUChksumFault_RWD "null";
BA_ "GenSigTimeoutTime_ALL" SG_ 1097 EDS_IGBTFault_RWD 500;
BA_ "InvalidValue" SG_ 1097 EDS_IGBTFault_RWD "null";
BA_ "GenSigTimeoutTime_ALL" SG_ 1097 EDS_CANBusoffFault_RWD 500;
BA_ "InvalidValue" SG_ 1097 EDS_CANBusoffFault_RWD "null";
BA_ "GenSigTimeoutTime_ALL" SG_ 1097 EDS_TDrvBoardOvHiWarn_RWD 500;
BA_ "InvalidValue" SG_ 1097 EDS_TDrvBoardOvHiWarn_RWD "null";
BA_ "GenSigTimeoutTime_ALL" SG_ 1097 EDS_TIGBTOvHiFault_RWD 500;
BA_ "InvalidValue" SG_ 1097 EDS_TIGBTOvHiFault_RWD "null";
BA_ "GenSigTimeoutTime_ALL" SG_ 1097 EDS_TIGBTOvHiWarn_RWD 500;
BA_ "InvalidValue" SG_ 1097 EDS_TIGBTOvHiWarn_RWD "null";
BA_ "GenSigTimeoutTime_ALL" SG_ 1097 EDS_IOHWABSampFail_RWD 500;
BA_ "InvalidValue" SG_ 1097 EDS_IOHWABSampFail_RWD "null";
BA_ "GenSigTimeoutTime_ALL" SG_ 1097 EDS_EDSOpenFault_RWD 500;
BA_ "InvalidValue" SG_ 1097 EDS_EDSOpenFault_RWD "null";
BA_ "GenSigTimeoutTime_ALL" SG_ 1097 EDS_MotorOpenFault_RWD 500;
BA_ "InvalidValue" SG_ 1097 EDS_MotorOpenFault_RWD "null";
BA_ "GenSigTimeoutTime_ALL" SG_ 1097 EDS_EparkSampFail_RWD 500;
BA_ "InvalidValue" SG_ 1097 EDS_EparkSampFail_RWD "null";
BA_ "GenSigTimeoutTime_ALL" SG_ 1097 EDS_EmacBlkdWarn_RWD 500;
BA_ "InvalidValue" SG_ 1097 EDS_EmacBlkdWarn_RWD "null";
BA_ "GenSigTimeoutTime_ALL" SG_ 1097 EDS_VerMatchFailureErr_RWD 500;
BA_ "InvalidValue" SG_ 1097 EDS_VerMatchFailureErr_RWD "null";
BA_ "GenSigTimeoutTime_ALL" SG_ 1097 EDS_DiashCirNoPsblErr_RWD 500;
BA_ "InvalidValue" SG_ 1097 EDS_DiashCirNoPsblErr_RWD "null";
BA_ "GenSigTimeoutTime_ALL" SG_ 1097 EDS_OperOutdRngErr_RWD 500;
BA_ "InvalidValue" SG_ 1097 EDS_OperOutdRngErr_RWD "null";
BA_ "GenSigTimeoutTime_ALL" SG_ 1097 EDS_PhaseLossFaultErr_RWD 500;
BA_ "InvalidValue" SG_ 1097 EDS_PhaseLossFaultErr_RWD "null";
BA_ "GenSigTimeoutTime_ALL" SG_ 1097 EDS_CPLDFault_RWD 500;
BA_ "InvalidValue" SG_ 1097 EDS_CPLDFault_RWD "null";
BA_ "GenSigTimeoutTime_ALL" SG_ 1097 EDS_CPLDFaultBaseSpd_RWD 500;
BA_ "InvalidValue" SG_ 1097 EDS_CPLDFaultBaseSpd_RWD "null";
BA_ "GenSigTimeoutTime_ALL" SG_ 1097 EDS_IOHWABNen33Fail_RWD 500;
BA_ "InvalidValue" SG_ 1097 EDS_IOHWABNen33Fail_RWD "null";
BA_ "GenSigTimeoutTime_ALL" SG_ 1097 EDS_HvMcuSlightFault_RWD 500;
BA_ "InvalidValue" SG_ 1097 EDS_HvMcuSlightFault_RWD "null";
BA_ "GenSigTimeoutTime_ALL" SG_ 1097 EDS_HvMcuSevFault_RWD 500;
BA_ "InvalidValue" SG_ 1097 EDS_HvMcuSevFault_RWD "null";
BA_ "GenSigTimeoutTime_ALL" SG_ 1097 EDS_EDSPhaSampHWFault_RWD 500;
BA_ "InvalidValue" SG_ 1097 EDS_EDSPhaSampHWFault_RWD "null";
BA_ "GenSigTimeoutTime_ALL" SG_ 1097 EDS_IsOvHiErr_RWD 500;
BA_ "InvalidValue" SG_ 1097 EDS_IsOvHiErr_RWD "null";
BA_ "GenSigTimeoutTime_ALL" SG_ 1097 EDS_CanRollingCounterErr_RWD 500;
BA_ "InvalidValue" SG_ 1097 EDS_CanRollingCounterErr_RWD "null";
BA_ "GenSigTimeoutTime_ALL" SG_ 1097 EDS_CanTimeoutErr_RWD 500;
BA_ "InvalidValue" SG_ 1097 EDS_CanTimeoutErr_RWD "null";
BA_ "GenSigTimeoutTime_ALL" SG_ 1097 EDS_CrashFault_RWD 500;
BA_ "InvalidValue" SG_ 1097 EDS_CrashFault_RWD "null";
BA_ "GenSigTimeoutTime_ALL" SG_ 1097 EDS_PCFSlightFault_RWD 500;
BA_ "InvalidValue" SG_ 1097 EDS_PCFSlightFault_RWD "null";
BA_ "GenSigTimeoutTime_ALL" SG_ 1097 EDS_PCFSerFault_RWD 500;
BA_ "InvalidValue" SG_ 1097 EDS_PCFSerFault_RWD "null";
BA_ "GenSigSendType" SG_ 1104 MHU_SET_WindowLifterFrontL 2;
BA_ "InvalidValue" SG_ 1104 MHU_SET_WindowLifterFrontL "7h";
BA_ "GenSigSendType" SG_ 1104 MHU_SET_WindowLifterFrontR 2;
BA_ "InvalidValue" SG_ 1104 MHU_SET_WindowLifterFrontR "7h";
BA_ "GenSigSendType" SG_ 1104 MHU_SET_WindowLifterRearL 2;
BA_ "InvalidValue" SG_ 1104 MHU_SET_WindowLifterRearL "7h";
BA_ "GenSigSendType" SG_ 1104 MHU_SET_WindowLifterRearR 2;
BA_ "InvalidValue" SG_ 1104 MHU_SET_WindowLifterRearR "7h";
BA_ "GenSigSendType" SG_ 1104 MHU_SET_WindowAutoClose 2;
BA_ "InvalidValue" SG_ 1104 MHU_SET_WindowAutoClose "3h";
BA_ "GenSigTimeoutTime_ALL" SG_ 1105 Checksum_RSSI 1000;
BA_ "InvalidValue" SG_ 1105 Checksum_RSSI "null";
BA_ "GenSigTimeoutTime_ALL" SG_ 1105 Rolling_Counter_RSSI 1000;
BA_ "InvalidValue" SG_ 1105 Rolling_Counter_RSSI "Fh";
BA_ "GenSigTimeoutTime_ALL" SG_ 1105 RSSI_Value 1000;
BA_ "InvalidValue" SG_ 1105 RSSI_Value "Fh";
BA_ "GenSigTimeoutTime_ALL" SG_ 1105 SECCAN_RSSI 1000;
BA_ "GenSigTimeoutTime_ALL" SG_ 1106 MHU_SET_ANN1_MODE 500;
BA_ "InvalidValue" SG_ 1106 MHU_SET_ANN1_MODE "null";
BA_ "GenSigTimeoutTime_ALL" SG_ 1107 MHU_SET_ANN1_PROMPTS_SPEAKER 500;
BA_ "InvalidValue" SG_ 1107 MHU_SET_ANN1_PROMPTS_SPEAKER "null";
BA_ "GenSigTimeoutTime_ALL" SG_ 1108 MHU_SET_ANN2_CEN_Mute 500;
BA_ "InvalidValue" SG_ 1108 MHU_SET_ANN2_CEN_Mute "0";
BA_ "GenSigTimeoutTime_ALL" SG_ 1108 MHU_SET_ANN2_RR_Mute 500;
BA_ "InvalidValue" SG_ 1108 MHU_SET_ANN2_RR_Mute "0";
BA_ "GenSigTimeoutTime_ALL" SG_ 1108 MHU_SET_ANN2_RL_Mute 500;
BA_ "InvalidValue" SG_ 1108 MHU_SET_ANN2_RL_Mute "0";
BA_ "GenSigTimeoutTime_ALL" SG_ 1108 MHU_SET_ANN2_FR_Mute 500;
BA_ "InvalidValue" SG_ 1108 MHU_SET_ANN2_FR_Mute "0";
BA_ "GenSigTimeoutTime_ALL" SG_ 1108 MHU_SET_ANN2_FL_Mute 500;
BA_ "InvalidValue" SG_ 1108 MHU_SET_ANN2_FL_Mute "0";
BA_ "GenSigStartValue" SG_ 1109 AMP_SET_Mediavolume 15;
BA_ "GenSigTimeoutTime_ALL" SG_ 1109 AMP_SET_Mediavolume 500;
BA_ "InvalidValue" SG_ 1109 AMP_SET_Mediavolume "FFh";
BA_ "GenSigTimeoutTime_ALL" SG_ 1109 AMP_SET_Soundzone 500;
BA_ "InvalidValue" SG_ 1109 AMP_SET_Soundzone "0";
BA_ "GenSigTimeoutTime_ALL" SG_ 1109 AMP_SET_Bass 500;
BA_ "InvalidValue" SG_ 1109 AMP_SET_Bass "1Fh";
BA_ "GenSigTimeoutTime_ALL" SG_ 1109 AMP_SET_Fader 500;
BA_ "InvalidValue" SG_ 1109 AMP_SET_Fader "1Fh";
BA_ "GenSigTimeoutTime_ALL" SG_ 1109 AMP_SET_MediaMute 500;
BA_ "InvalidValue" SG_ 1109 AMP_SET_MediaMute "3h";
BA_ "GenSigTimeoutTime_ALL" SG_ 1109 AMP_SET_MidPitch 500;
BA_ "InvalidValue" SG_ 1109 AMP_SET_MidPitch "1Fh";
BA_ "GenSigTimeoutTime_ALL" SG_ 1109 AMP_SET_Treble 500;
BA_ "InvalidValue" SG_ 1109 AMP_SET_Treble "1Fh";
BA_ "GenSigTimeoutTime_ALL" SG_ 1109 AMP_SET_Balance 500;
BA_ "InvalidValue" SG_ 1109 AMP_SET_Balance "1Fh";
BA_ "GenSigSendType" SG_ 1110 OP_WISW_SZL_LIN 3;
BA_ "InvalidValue" SG_ 1110 OP_WISW_SZL_LIN "null";
BA_ "GenSigSendType" SG_ 1110 COMM_ERR_SZL_LIN 3;
BA_ "InvalidValue" SG_ 1110 COMM_ERR_SZL_LIN "null";
BA_ "GenSigSendType" SG_ 1110 BCM_Wiper_Front_Status 3;
BA_ "InvalidValue" SG_ 1110 BCM_Wiper_Front_Status "null";
BA_ "GenSigSendType" SG_ 1110 OP_WIPO_SZL_LIN 3;
BA_ "InvalidValue" SG_ 1110 OP_WIPO_SZL_LIN "null";
BA_ "GenSigSendType" SG_ 1110 OP_COLS_SZL_LIN 3;
BA_ "InvalidValue" SG_ 1110 OP_COLS_SZL_LIN "null";
BA_ "GenSigSendType" SG_ 1110 NOD_ERR_SZL_LIN 3;
BA_ "InvalidValue" SG_ 1110 NOD_ERR_SZL_LIN "null";
BA_ "GenSigSendType" SG_ 1110 BCM_Wiper_Rear_Status 3;
BA_ "InvalidValue" SG_ 1110 BCM_Wiper_Rear_Status "3h";
BA_ "GenSigSendType" SG_ 1110 ALIV_WISW_SZL_LIN 3;
BA_ "InvalidValue" SG_ 1110 ALIV_WISW_SZL_LIN "Fh";
BA_ "GenSigSendType" SG_ 1111 AmbLight_Error_Z5 3;
BA_ "InvalidValue" SG_ 1111 AmbLight_Error_Z5 "null";
BA_ "GenSigSendType" SG_ 1111 AmbLight_Error_Z4 3;
BA_ "InvalidValue" SG_ 1111 AmbLight_Error_Z4 "null";
BA_ "GenSigSendType" SG_ 1111 AmbLight_Error_Z3 3;
BA_ "InvalidValue" SG_ 1111 AmbLight_Error_Z3 "null";
BA_ "GenSigSendType" SG_ 1111 AmbLight_Error_Z2 3;
BA_ "InvalidValue" SG_ 1111 AmbLight_Error_Z2 "null";
BA_ "GenSigSendType" SG_ 1111 AmbLight_Error_Z1 3;
BA_ "InvalidValue" SG_ 1111 AmbLight_Error_Z1 "null";
BA_ "GenSigSendType" SG_ 1112 AmbLightColorZoneReq 2;
BA_ "InvalidValue" SG_ 1112 AmbLightColorZoneReq "null";
BA_ "GenSigSendType" SG_ 1112 AmbLightColorRed 2;
BA_ "InvalidValue" SG_ 1112 AmbLightColorRed "null";
BA_ "GenSigSendType" SG_ 1112 AmbLightColorGreen 2;
BA_ "InvalidValue" SG_ 1112 AmbLightColorGreen "null";
BA_ "GenSigSendType" SG_ 1112 AmbLightColorBlue 2;
BA_ "InvalidValue" SG_ 1112 AmbLightColorBlue "null";
BA_ "GenSigSendType" SG_ 1112 SECCAN_BCM_Clr_Rq 2;
BA_ "InvalidValue" SG_ 1112 SECCAN_BCM_Clr_Rq "null";
BA_ "GenSigSendType" SG_ 1113 AmbLightIntensityTimingZoneReq 2;
BA_ "InvalidValue" SG_ 1113 AmbLightIntensityTimingZoneReq "null";
BA_ "GenSigSendType" SG_ 1113 AmbLightIntensityTimingTypeReq 2;
BA_ "InvalidValue" SG_ 1113 AmbLightIntensityTimingTypeReq "null";
BA_ "GenSigSendType" SG_ 1113 AmbLightIntenTimingBrightReq 2;
BA_ "InvalidValue" SG_ 1113 AmbLightIntenTimingBrightReq "null";
BA_ "GenSigSendType" SG_ 1113 AmbLightIntensityTimingT1Req 2;
BA_ "InvalidValue" SG_ 1113 AmbLightIntensityTimingT1Req "null";
BA_ "GenSigSendType" SG_ 1113 AmbLightIntensityTimingT2Req 2;
BA_ "InvalidValue" SG_ 1113 AmbLightIntensityTimingT2Req "null";
BA_ "GenSigSendType" SG_ 1113 AmbLightIntensityTimingT3Req 2;
BA_ "InvalidValue" SG_ 1113 AmbLightIntensityTimingT3Req "null";
BA_ "GenSigSendType" SG_ 1113 AmbLightIntensityTimingT4Req 2;
BA_ "InvalidValue" SG_ 1113 AmbLightIntensityTimingT4Req "null";
BA_ "GenSigSendType" SG_ 1113 AmbLightIntensityTimingN2Req 2;
BA_ "InvalidValue" SG_ 1113 AmbLightIntensityTimingN2Req "null";
BA_ "GenSigSendType" SG_ 1113 AmbLightIntensityTimingN1Req 2;
BA_ "InvalidValue" SG_ 1113 AmbLightIntensityTimingN1Req "null";
BA_ "InvalidValue" SG_ 1115 HOD_steering_wheel_type "Fh";
BA_ "GenSigTimeoutTime_ALL" SG_ 1115 HOD_steering_wheel_type 2500;
BA_ "InvalidValue" SG_ 1115 HOD_vehicle_type "FFh";
BA_ "GenSigTimeoutTime_ALL" SG_ 1115 HOD_vehicle_type 2500;
BA_ "GenSigTimeoutTime_ALL" SG_ 1115 ADAS_HOD_state_requesting 2500;
BA_ "InvalidValue" SG_ 1115 ADAS_HOD_state_requesting "3h";
BA_ "GenSigTimeoutTime_ALL" SG_ 1124 LDML_LampAssemblySts 500;
BA_ "InvalidValue" SG_ 1124 LDML_LampAssemblySts "3h";
BA_ "GenSigTimeoutTime_ALL" SG_ 1124 LDML_PosLmpSts 500;
BA_ "InvalidValue" SG_ 1124 LDML_PosLmpSts "3h";
BA_ "GenSigTimeoutTime_ALL" SG_ 1124 LDML_ControllerSts 500;
BA_ "InvalidValue" SG_ 1124 LDML_ControllerSts "3h";
BA_ "GenSigTimeoutTime_ALL" SG_ 1124 LDML_TurnIndicatorSts 500;
BA_ "InvalidValue" SG_ 1124 LDML_TurnIndicatorSts "3h";
BA_ "GenSigTimeoutTime_ALL" SG_ 1124 LDML_AuxLBSts 500;
BA_ "InvalidValue" SG_ 1124 LDML_AuxLBSts "3h";
BA_ "GenSigTimeoutTime_ALL" SG_ 1124 LDML_LowBeamSts 500;
BA_ "InvalidValue" SG_ 1124 LDML_LowBeamSts "3h";
BA_ "GenSigTimeoutTime_ALL" SG_ 1124 LDML_HighBeamSts 500;
BA_ "InvalidValue" SG_ 1124 LDML_HighBeamSts "3h";
BA_ "GenSigTimeoutTime_ALL" SG_ 1124 LDML_DayRunningLampSts 500;
BA_ "InvalidValue" SG_ 1124 LDML_DayRunningLampSts "3h";
BA_ "GenSigTimeoutTime_ALL" SG_ 1124 LDML_DayTimeRunningLightFbSts 500;
BA_ "InvalidValue" SG_ 1124 LDML_DayTimeRunningLightFbSts "3h";
BA_ "GenSigTimeoutTime_ALL" SG_ 1124 LDML_AutoLvlFbSts 500;
BA_ "InvalidValue" SG_ 1124 LDML_AutoLvlFbSts "3h";
BA_ "GenSigTimeoutTime_ALL" SG_ 1124 LDML_AdptvDrvBeamFbSts 500;
BA_ "InvalidValue" SG_ 1124 LDML_AdptvDrvBeamFbSts "3h";
BA_ "GenSigTimeoutTime_ALL" SG_ 1124 LDML_AuxHBSts 500;
BA_ "InvalidValue" SG_ 1124 LDML_AuxHBSts "3h";
BA_ "GenSigTimeoutTime_ALL" SG_ 1124 LDML_FollowMeHomeFbSts 500;
BA_ "InvalidValue" SG_ 1124 LDML_FollowMeHomeFbSts "5h";
BA_ "GenSigTimeoutTime_ALL" SG_ 1124 LDML_ExteriorLightFbSts 500;
BA_ "InvalidValue" SG_ 1124 LDML_ExteriorLightFbSts "4h";
BA_ "GenSigStartValue" SG_ 1124 LDML_AHB_ICON_Feed 3;
BA_ "GenSigTimeoutTime_ALL" SG_ 1124 LDML_AHB_ICON_Feed 500;
BA_ "InvalidValue" SG_ 1124 LDML_AHB_ICON_Feed "3h";
BA_ "GenSigTimeoutTime_ALL" SG_ 1125 LDMR_LampAssemblySts 500;
BA_ "InvalidValue" SG_ 1125 LDMR_LampAssemblySts "3h";
BA_ "GenSigTimeoutTime_ALL" SG_ 1125 LDMR_PosLmpSts 500;
BA_ "InvalidValue" SG_ 1125 LDMR_PosLmpSts "3h";
BA_ "GenSigTimeoutTime_ALL" SG_ 1125 LDMR_ControllerSts 500;
BA_ "InvalidValue" SG_ 1125 LDMR_ControllerSts "3h";
BA_ "GenSigTimeoutTime_ALL" SG_ 1125 LDMR_TurnIndicatorSts 500;
BA_ "InvalidValue" SG_ 1125 LDMR_TurnIndicatorSts "3h";
BA_ "GenSigTimeoutTime_ALL" SG_ 1125 LDMR_AuxLBSts 500;
BA_ "InvalidValue" SG_ 1125 LDMR_AuxLBSts "3h";
BA_ "GenSigTimeoutTime_ALL" SG_ 1125 LDMR_LowBeamSts 500;
BA_ "InvalidValue" SG_ 1125 LDMR_LowBeamSts "3h";
BA_ "GenSigTimeoutTime_ALL" SG_ 1125 LDMR_HighBeamSts 500;
BA_ "InvalidValue" SG_ 1125 LDMR_HighBeamSts "3h";
BA_ "GenSigTimeoutTime_ALL" SG_ 1125 LDMR_DayRunningLampSts 500;
BA_ "InvalidValue" SG_ 1125 LDMR_DayRunningLampSts "3h";
BA_ "GenSigTimeoutTime_ALL" SG_ 1125 LDMR_DayTimeRunningLightFbSts 500;
BA_ "InvalidValue" SG_ 1125 LDMR_DayTimeRunningLightFbSts "3h";
BA_ "GenSigTimeoutTime_ALL" SG_ 1125 LDMR_AutoLvlFbSts 500;
BA_ "InvalidValue" SG_ 1125 LDMR_AutoLvlFbSts "3h";
BA_ "GenSigTimeoutTime_ALL" SG_ 1125 LDMR_AdptvDrvBeamFbSts 500;
BA_ "InvalidValue" SG_ 1125 LDMR_AdptvDrvBeamFbSts "3h";
BA_ "GenSigTimeoutTime_ALL" SG_ 1125 LDMR_AuxHBSts 500;
BA_ "InvalidValue" SG_ 1125 LDMR_AuxHBSts "3h";
BA_ "GenSigTimeoutTime_ALL" SG_ 1125 LDMR_FollowMeHomeFbSts 500;
BA_ "InvalidValue" SG_ 1125 LDMR_FollowMeHomeFbSts "5h";
BA_ "GenSigTimeoutTime_ALL" SG_ 1125 LDMR_ExteriorLightFbSts 500;
BA_ "InvalidValue" SG_ 1125 LDMR_ExteriorLightFbSts "4h";
BA_ "GenSigStartValue" SG_ 1125 LDMR_AHB_ICON_Feed 3;
BA_ "GenSigTimeoutTime_ALL" SG_ 1125 LDMR_AHB_ICON_Feed 500;
BA_ "InvalidValue" SG_ 1125 LDMR_AHB_ICON_Feed "3h";
BA_ "GenSigTimeoutTime_ALL" SG_ 1136 AMP_SET_ANN1_MODE 500;
BA_ "InvalidValue" SG_ 1136 AMP_SET_ANN1_MODE "null";
BA_ "GenSigTimeoutTime_ALL" SG_ 1137 AMP_SET_ANN1_PROMPTS_SPEAKER 500;
BA_ "InvalidValue" SG_ 1137 AMP_SET_ANN1_PROMPTS_SPEAKER "null";
BA_ "GenSigTimeoutTime_ALL" SG_ 1138 AMP_SET_ANN2_CEN_Mute 500;
BA_ "InvalidValue" SG_ 1138 AMP_SET_ANN2_CEN_Mute "null";
BA_ "GenSigTimeoutTime_ALL" SG_ 1138 AMP_SET_ANN2_RR_Mute 500;
BA_ "InvalidValue" SG_ 1138 AMP_SET_ANN2_RR_Mute "null";
BA_ "GenSigTimeoutTime_ALL" SG_ 1138 AMP_SET_ANN2_RL_Mute 500;
BA_ "InvalidValue" SG_ 1138 AMP_SET_ANN2_RL_Mute "null";
BA_ "GenSigTimeoutTime_ALL" SG_ 1138 AMP_SET_ANN2_FR_Mute 500;
BA_ "InvalidValue" SG_ 1138 AMP_SET_ANN2_FR_Mute "null";
BA_ "GenSigTimeoutTime_ALL" SG_ 1138 AMP_SET_ANN2_FL_Mute 500;
BA_ "InvalidValue" SG_ 1138 AMP_SET_ANN2_FL_Mute "null";
BA_ "GenSigSendType" SG_ 1152 CHKSM_PSM_WARNING_MSG 3;
BA_ "GenSigTimeoutTime_ALL" SG_ 1152 CHKSM_PSM_WARNING_MSG 5000;
BA_ "InvalidValue" SG_ 1152 CHKSM_PSM_WARNING_MSG "null";
BA_ "GenSigSendType" SG_ 1152 ALV_PSM_WARNING_MSG 3;
BA_ "GenSigTimeoutTime_ALL" SG_ 1152 ALV_PSM_WARNING_MSG 5000;
BA_ "InvalidValue" SG_ 1152 ALV_PSM_WARNING_MSG "Fh";
BA_ "GenSigSendType" SG_ 1152 PSM_DrvSeatMissalignment 4;
BA_ "GenSigTimeoutTime_ALL" SG_ 1152 PSM_DrvSeatMissalignment 5000;
BA_ "InvalidValue" SG_ 1152 PSM_DrvSeatMissalignment "null";
BA_ "GenSigSendType" SG_ 1152 PSM_PasSeatMisalignment 4;
BA_ "GenSigTimeoutTime_ALL" SG_ 1152 PSM_PasSeatMisalignment 5000;
BA_ "InvalidValue" SG_ 1152 PSM_PasSeatMisalignment "null";
BA_ "GenSigSendType" SG_ 1152 PSM_WflagRes3 4;
BA_ "GenSigTimeoutTime_ALL" SG_ 1152 PSM_WflagRes3 5000;
BA_ "InvalidValue" SG_ 1152 PSM_WflagRes3 "null";
BA_ "GenSigSendType" SG_ 1152 PSM_WflagRes4 4;
BA_ "GenSigTimeoutTime_ALL" SG_ 1152 PSM_WflagRes4 5000;
BA_ "InvalidValue" SG_ 1152 PSM_WflagRes4 "3h";
BA_ "GenSigSendType" SG_ 1152 PSM_WflagRes5 4;
BA_ "GenSigTimeoutTime_ALL" SG_ 1152 PSM_WflagRes5 5000;
BA_ "InvalidValue" SG_ 1152 PSM_WflagRes5 "null";
BA_ "GenSigSendType" SG_ 1152 PSM_WflagRes6 4;
BA_ "GenSigTimeoutTime_ALL" SG_ 1152 PSM_WflagRes6 5000;
BA_ "InvalidValue" SG_ 1152 PSM_WflagRes6 "null";
BA_ "GenSigSendType" SG_ 1152 PSM_WflagRes7 4;
BA_ "GenSigTimeoutTime_ALL" SG_ 1152 PSM_WflagRes7 5000;
BA_ "InvalidValue" SG_ 1152 PSM_WflagRes7 "null";
BA_ "GenSigSendType" SG_ 1152 PSM_WflagRes8 4;
BA_ "GenSigTimeoutTime_ALL" SG_ 1152 PSM_WflagRes8 5000;
BA_ "InvalidValue" SG_ 1152 PSM_WflagRes8 "null";
BA_ "GenSigSendType" SG_ 1152 PSM_WflagRes9 4;
BA_ "GenSigTimeoutTime_ALL" SG_ 1152 PSM_WflagRes9 5000;
BA_ "InvalidValue" SG_ 1152 PSM_WflagRes9 "null";
BA_ "GenSigSendType" SG_ 1152 PSM_WflagRes10 4;
BA_ "GenSigTimeoutTime_ALL" SG_ 1152 PSM_WflagRes10 5000;
BA_ "InvalidValue" SG_ 1152 PSM_WflagRes10 "null";
BA_ "GenSigSendType" SG_ 1152 PSM_WflagRes11 4;
BA_ "GenSigTimeoutTime_ALL" SG_ 1152 PSM_WflagRes11 5000;
BA_ "InvalidValue" SG_ 1152 PSM_WflagRes11 "null";
BA_ "GenSigSendType" SG_ 1152 PSM_WflagRes12 4;
BA_ "GenSigTimeoutTime_ALL" SG_ 1152 PSM_WflagRes12 5000;
BA_ "InvalidValue" SG_ 1152 PSM_WflagRes12 "null";
VAL_ 1030 MHU_SET_SeatHeatingFrontL 0 "OFF" 1 "Level1" 2 "Level2" 3 "Level3" 4 "Signal invalid";
VAL_ 1030 MHU_SET_SeatHeatingFrontR 0 "OFF" 1 "Level1" 2 "Level2" 3 "Level3" 4 "Signal invalid";
VAL_ 1030 MHU_SET_SeatHeatingReartL 0 "OFF" 1 "Level1" 2 "Level2" 3 "Level3" 4 "Signal invalid";
VAL_ 1030 MHU_SET_SeatHeatingRearR 0 "OFF" 1 "Level1" 2 "Level2" 3 "Level3" 4 "Signal invalid";
VAL_ 1030 MHU_SET_SeatCoolingFrontL 0 "OFF" 1 "Level1" 2 "Level2" 3 "Level3" 4 "Signal invalid";
VAL_ 1030 MHU_SET_SeatCoolingFrontR 0 "OFF" 1 "Level1" 2 "Level2" 3 "Level3" 4 "Signal invalid";
VAL_ 1030 MHU_SET_SeatCoolingRearL 0 "OFF" 1 "Level1" 2 "Level2" 3 "Level3" 4 "Signal invalid";
VAL_ 1030 MHU_SET_SeatCoolingRearR 0 "OFF" 1 "Level1" 2 "Level2" 3 "Level3" 4 "Signal invalid";
VAL_ 1032 MHU_SET_MirrorAuto 0 "OFF" 1 "ON" 2 "Reserved" 3 "Signal invalid";
VAL_ 1032 MHU_SET_MirrorAutoUnfold 0 "Vehicle Unlock" 1 "Driver walk toward" 2 "OFF" 3 "Signal invalid";
VAL_ 1032 MHU_SET_WLC 0 "OFF" 1 "ON" 2 "Reserved" 3 "Signal invalid";
VAL_ 1032 MHU_SET_AutoRearWiper 0 "OFF" 1 "ON" 2 "Reserved" 3 "Signal invalid";
VAL_ 1032 MHU_SET_RearHeatedWindow 0 "Not pressed" 1 "Pressed" 2 "Reserved" 3 "Signal invalid";
VAL_ 1032 MHU_TPMSReset 0 "Noreset" 1 "Reset" 2 "Reserved" 3 "Signal invalid";
VAL_ 1032 MHU_SET_MirrorDefaultSetting 0 "Not pressed" 1 "Pressed" 2 "Reserved" 3 "Signal invalid";
VAL_ 1032 MHU_SET_MirrorReverseLink 0 "OFF" 1 "Right Mirror" 2 "Left Mirror" 3 "Both Mirror";
VAL_ 1032 MHU_SET_AntiTheftMode 0 "OFF" 1 "Light Only" 2 "Horn Only" 3 "Light and Horn";
VAL_ 1032 MHU_SET_WLCReminder 0 "OFF" 1 "ON" 2 "Reserved" 3 "Signal invalid";
VAL_ 1032 MHU_SET_ClimateKeepOn 0 "OFF" 1 "PET" 2 "CAMP" 3 "REMOTE CONTROL";
VAL_ 1032 MHU_SET_WLC2 0 "OFF" 1 "ON" 2 "Reserved" 3 "Signal invalid";
VAL_ 1032 MHU_SET_WLC2Reminder 0 "OFF" 1 "ON" 2 "Reserved" 3 "Signal invalid";
VAL_ 1032 MHU_IntrusionAlertStatus 0 "OFF" 1 "ON" 2 "Stop Alarm" 3 "Signal invalid";
VAL_ 1034 MHU_SET_HudTurnSigOnOff 0 "OFF" 1 "ON";
VAL_ 1034 MHU_SET_HudBSDOnOff  0 "OFF" 1 "ON";
VAL_ 1034 MHU_SET_HudRCTAOnOff 0 "OFF" 1 "ON";
VAL_ 1034 MHU_SET_HudUIContent 0 "Default (Only speed)" 1 "+ADAS" 2 "+Navigation" 3 "+ADAS + Navigation" 4 "+ Power-Regen gauge" 5 "+ Power-Regen gauge + ADAS" 6 "+ Power-Regen gauge + Navigation" 7 "+ Power-Regen + ADAS + Navigation";
VAL_ 1034 MHU_SET_HudUIColor 0 "White (Default)" 1 "Green" 2 "Orange";
VAL_ 1034 MHU_SET_HudScreenOnOFF 0 "OFF" 1 "ON" 2 "Reserved" 3 "Signal invalid";
VAL_ 1034 MHU_SET_UserBrightnessLvl 0 "No action" 1 "Level 1" 2 "Level 2" 3 "Level 3" 4 "Level 4" 5 "Level 5" 6 "Level 6" 7 "Level 7" 8 "Level 8 " 9 "Level 9" 10 "Level 10" 11 "Level 11" 12 "Level 12" 13 "Level 13" 14 "Level 14" 15 "Level 15" 16 "Level 16" 17 "Level 17" 18 "Level 18" 19 "Level 19" 20 "Level 20" 21 "Level 21 " 22 "Reserved" 23 "Reserved" 24 "Reserved" 25 "Reserved" 26 "Reserved" 27 "Reserved" 28 "Reserved" 29 "Reserved" 30 "Reserved" 31 "Reserved";
VAL_ 1034 MHU_SET_HudWorkingMode 0 "Working Mode" 1 "Position adjustment Mode" 2 "EOL Mode" 3 "Engineering mode";
VAL_ 1034 MHU_SET_HudUISize 0 "Small" 1 "Mid" 2 "Large" 3 "Reserved";
VAL_ 1034 MHU_SET_UIContentMediaInfo 0 "OFF" 1 "ON";
VAL_ 1034 MHU_SET_UIContentCallInfo 0 "OFF" 1 "ON";
VAL_ 1034 MHU_SET_UIContentPoweRegen 0 "OFF" 1 "ON";
VAL_ 1035 MHU_SET_AvasSound 0 "Enhanced" 1 "Normal" 2 "Minimized" 3 "OFF";
VAL_ 1036 MHU_DrvSeat_Control_Status 0 "Idle" 1 "Request seat moving" 2 "Reserved" 3 "Invalid value";
VAL_ 1042 eCall_state 0 "Off/Inactive" 1 "Faulted/Error" 2 "On/Active - Call Not Triggered Automatically" 3 "On/Active - Call Automatically Triggered" 4 "On/Active - eCall Ongoing" ;
VAL_ 1043 FCAM_SRR_RR_Fault 0 "No fault" 1 "Temp fault(clean fix)" 2 "Temp fault(Environment)" 3 "Permanent fault" ;
VAL_ 1043 FCAM_SCAM_Fault 0 "No fault" 1 "Temp fault(clean fix)" 2 "Temp fault(Environment)" 3 "Permanent fault" ;
VAL_ 1043 FCAM_SRR_FR_Fault 0 "No fault" 1 "Temp fault(clean fix)" 2 "Temp fault(Environment)" 3 "Permanent fault" ;
VAL_ 1043 FCAM_MRR_Fault 0 "No fault" 1 "Temp fault(clean fix)" 2 "Temp fault(Environment)" 3 "Permanent fault" ;
VAL_ 1043 FCAM_SRR_RL_Fault 0 "No fault" 1 "Temp fault(clean fix)" 2 "Temp fault(Environment)" 3 "Permanent fault" ;
VAL_ 1043 FCAM_SRR_FL_Fault 0 "No fault" 1 "Temp fault(clean fix)" 2 "Temp fault(Environment)" 3 "Permanent fault" ;
VAL_ 1044 ERR_ST_HOD 0 "NO_ERROR" 1 "HOD_EEPROM_ERROR" 2 "HOD_ROM_ERROR" 3 "HOD_WATCHDOG_ERROR" 4 "HOD_CPU_ERROR" 5 "HOD_GUARD_INTERRUPTION_ERROR" 6 "HOD_SENSE_INTERRUPTION_ERROR" 7 "HOD_CPU_DEFECT_OR_MAT_SHORTAGE" 8 "UNDERVOLTAGE_ERROR" 9 "OVERVOLTAGE_ERROR" 10 "HOD_CODING_ERROR" 11 "HOD_GENERIC_SYSTEM_ERROR" 15 "Not Available" ;
VAL_ 1044 RsErr_HOD 0 "No_error" 1 "error" ;
VAL_ 1044 HOD_status 0 "Init" 1 "Hands OFF" 2 "Hands ON" 3 "Energie_Save_Mode" 4 "HOD error" 5 "Invalid value" 6 "Reserved" 7 "Reserved" 8 "Reserved" 9 "Reserved" 10 "Reserved" 11 "Reserved" 12 "Reserved" 13 "Reserved" 14 "Reserved" 15 "Reserved" ;
VAL_ 1046 BCM_STAT_Mirror 0 "Fold" 1 "Unfold" 2 "Reserved" 3 "Signal Invalid";
VAL_ 1046 BCM_STAT_MirrorAdjustLeft 0 "OFF" 1 "ON" 2 "Reserved" 3 "Signal invalid";
VAL_ 1046 BCM_STAT_MirrorAdjustRight 0 "OFF" 1 "ON" 2 "Reserved" 3 "Signal invalid";
VAL_ 1049 SHVU_STAT_SeatHeatingFrontL 0 "OFF" 1 "Level1" 2 "Level2" 3 "Level3" 4 "Signal invalid";
VAL_ 1049 SHVU_STAT_SeatHeatingFrontR 0 "OFF" 1 "Level1" 2 "Level2" 3 "Level3" 4 "Signal invalid";
VAL_ 1049 SHVU_STAT_SeatCoolingFrontL 0 "OFF" 1 "Level1" 2 "Level2" 3 "Level3" 4 "Signal invalid";
VAL_ 1049 SHVU_STAT_SeatCoolingFrontR 0 "OFF" 1 "Level1" 2 "Level2" 3 "Level3" 4 "Signal invalid";
VAL_ 1049 SHVU_STAT_FrontSeatVentSts 0 "Normal Operation" 1 "Failure" 2 "Reserved" 3 "Signal invalid";
VAL_ 1050 SHVU_STAT_SeatCoolingRearL 0 "OFF" 1 "Level1" 2 "Level2" 3 "Level3" 4 "Signal invalid";
VAL_ 1050 SHVU_STAT_SeatCoolingRearR 0 "OFF" 1 "Level1" 2 "Level2" 3 "Level3" 4 "Signal invalid";
VAL_ 1050 SHVU_STAT_SeatHeatingReartL 0 "OFF" 1 "Level1" 2 "Level2" 3 "Level3" 4 "Signal invalid";
VAL_ 1050 SHVU_STAT_SeatHeatingRearR 0 "OFF" 1 "Level1" 2 "Level2" 3 "Level3" 4 "Signal invalid";
VAL_ 1050 SHVU_STAT_RearSeatVentSts 0 "Normal Operation" 1 "Failure" 2 "Reserved" 3 "Signal invalid";
VAL_ 1052 PSM_Seat_track_pos_Dri 0 "Front position" 1 "Not Front position" 2 "Failure" 3 "Invalid Value";
VAL_ 1052 PSM_Seat_track_posPas 0 "Front position" 1 "Not Front position" 2 "Failure" 3 "Invalid Value";
VAL_ 1053 BCM_STAT_AutoRearWiper 0 "OFF" 1 "ON" 2 "Reserved" 3 "Signal invalid";
VAL_ 1053 BCM_STAT_MirrorFoldSetting 0 "Auto Fold OFF" 1 "Auto Fold ON" 2 "Reserved" 3 "Signal invalid";
VAL_ 1053 BCM_STAT_IMMO_KeyfobID2 0 "No trigger from MHU" 1 "Fob1" 2 "Fob2" 3 "key illegal" 4 "No key found" 5 "Searching" 6 "Reserved" 7 "Signal invalid";
VAL_ 1053 BCM_STAT_MirrorAutoUnfold 0 "Vehicle Unlock" 1 "Driver walk toward" 2 "OFF" 3 "Signal invalid";
VAL_ 1053 BCM_STAT_MirrorReverseLink 0 "OFF" 1 "Right Mirror" 2 "Left Mirror" 3 "Both Mirror";
VAL_ 1053 BCM_STAT_MirrorDefaultSTATting 0 "Not pressed" 1 "Pressed" 2 "Reserved" 3 "Signal invalid";
VAL_ 1053 BCM_STAT_WelcomeTriggerCondition 0 "Vehicle unLock" 1 "Driver walk toward" 2 "OFF" 3 "Signal invalid";
VAL_ 1053 BCM_STAT_FrontDomeLamp 0 "OFF" 1 "ON" 2 "AUTO" 3 "Signal invalid";
VAL_ 1053 BCM_STAT_FollowMeHome 0 "OFF" 1 "30 secs" 2 "60 secs" 3 "90 secs" 4 "120 secs" 5 "Signal invalid";
VAL_ 1053 BCM_STAT_ExteriorLight 0 "OFF" 1 "Parking" 2 "ON" 3 "AUTO" 4 "Signal invalid";
VAL_ 1053 BCM_STAT_RemoteLockFeedback 0 "OFF" 1 "Lights and Horn" 2 "Lights Only" 3 "Horn Only" 4 "Reserved" 5 "Reserved" 6 "Reserved" 7 "Signal invalid";
VAL_ 1053 BCM_STAT_RemoteDoorUnlock 0 "Reserved" 1 "Driver door" 2 "All doors" 3 "Signal invalid";
VAL_ 1053 BCM_STAT_WalkawayDoorLock 0 "OFF" 1 "ON";
VAL_ 1053 BCM_STAT_AutoDoorUnlock 0 "OFF" 1 "ON" 2 "Reserved" 3 "Signal invalid";
VAL_ 1053 BCM_STAT_WiperServiceMode 0 "OFF" 1 "ON" 2 "Reserved" 3 "Signal Invalid";
VAL_ 1053 BCM_STAT_IMMO_KeyfobID 0 "No Key Found" 1 "ID1" 2 "ID2" 3 "Signal Invalid";
VAL_ 1053 BCM_STAT_RearHeatedWindowMirror 0 "OFF" 1 "ON" 2 "Reserved" 3 "Signal invalid";
VAL_ 1053 BCM_STAT_AntiTheftMode 0 "OFF" 1 "Light Only" 2 "Horn Only" 3 "Light and Horn" 4 "Signal invalid";
VAL_ 1053 BCM_STAT_ClimateKeepOnSts 0 "OFF" 1 "PET" 2 "CAMP" 3 "REMOTE CONTROL";
VAL_ 1053 BCM_STAT_FKSfeedback 0 "OFF" 1 "ON" 2 "Reserved" 3 "Signal Invalid";
VAL_ 1054 HUD_UIColor 0 "White (Default)" 1 "Green" 2 "Orange";
VAL_ 1054 HUD_UIContent 0 "Default (Only speed)" 1 "+ADAS" 2 "+Navigation" 3 "+ADAS + Navigation" 4 "+ Power-Regen gauge" 5 "+ Power-Regen gauge + ADAS" 6 "+ Power-Regen gauge + Navigation" 7 "+ Power-Regen + ADAS + Navigation";
VAL_ 1054 HUD_OperationState 0 "Invalid" 1 "Standby" 2 "Screen ON" 3 "Reserved";
VAL_ 1054 HUD_HeightLvl 0 "No action" 1 "Level 1" 2 "Level 2" 3 "Level 3" 4 "Level 4" 5 "Level 5" 6 "Level 6" 7 "Level 7" 8 "Level 8" 9 "Level 9" 10 "Level 10" 11 "Level 11" 12 "Level 12" 13 "Level 13" 14 "Level 14" 15 "Level 15" 16 "Level 16" 17 "Level 17" 18 "Level 18" 19 "Level 19" 20 "Level 20" 21 "Level 21" 22 "Reserved";
VAL_ 1054 HUD_UI_Size 0 "Small" 1 "Mid" 2 "Big" 3 "Reserved";
VAL_ 1054 HUD_UIContentMediaInfo 0 "OFF" 1 "ON";
VAL_ 1054 HUD_UIContentCallInfor 0 "OFF" 1 "ON";
VAL_ 1054 HUD_UIContentPowerRegen 0 "OFF" 1 "ON";
VAL_ 1054 HUD_TurnSigOnOff_Feed 0 "OFF" 1 "ON";
VAL_ 1054 HUD_BSDOnOff_Feed 0 "OFF" 1 "ON";
VAL_ 1054 HUD_RCTAOnOff_Feed 0 "OFF" 1 "ON";
VAL_ 1054 HUD_UIModeSignal 0 "Normal" 1 "Reserved" 2 "Reserved" 3 "Reserved" 4 "Reserved" 5 "Reserved" 6 "Reserved" 7 "Reserved";
VAL_ 1054 HUD_WorkingMode 0 "Working Mode" 1 "Position adjustment Mode" 2 "EOL Mode" 3 "Engineering mode";
VAL_ 1054 HUD_RotateAngleLvl 0 "No action" 1 "Level 1" 2 "Level 2" 3 "Level 3" 4 "Level 4" 5 "Level 5" 6 "Level 6" 7 "Level 7" 8 "Level 8 " 9 "Level 9" 10 "Level 10" 11 "Level 11" 12 "Level 12" 13 "Level 13" 14 "Level 14" 15 "Level 15";
VAL_ 1054 HUD_UserSetBrightnessLvl 0 "No action" 1 "Level 1" 2 "Level 2" 3 "Level 3" 4 "Level 4" 5 "Level 5" 6 "Level 6" 7 "Level 7" 8 "Level 8 " 9 "Level 9" 10 "Level 10" 11 "Level 11" 12 "Level 12" 13 "Level 13" 14 "Level 14" 15 "Level 15" 16 "Level 16" 17 "Level 17" 18 "Level 18" 19 "Level 19" 20 "Level 20" 21 "Level 21 " 22 "Reserved" 23 "Reserved" 24 "Reserved" 25 "Reserved" 26 "Reserved" 27 "Reserved" 28 "Reserved" 29 "Reserved" 30 "Reserved" 31 "Reserved";
VAL_ 1054 HUD_Language 0 "Vietnamese" 1 "English" 2 "Spanish" 3 "French" 4 "German" 5 "Dutch" 6 "English (CANADA)" 7 "French (CANADA)" 8 "Russian" 9 "Spanish (Latin America)" 10 "Portuguese" 11 "Portuguese (Brasil)" 12 "Chinese, simplipied" 13 "Chinese, traditional" 14 "Reserved" 15 "Reserved" 16 "Reserved" 17 "Reserved" 18 "Reserved" 19 "Reserved" 20 "Reserved" 21 "Reserved" 22 "Reserved" 23 "Reserved" 24 "Reserved" 25 "Reserved" 26 "Reserved" 27 "Reserved" 28 "Reserved" 29 "Reserved" 30 "Reserved" 31 "Signal invalid";
VAL_ 1054 HUD_Mileage_Unit 0 "Km" 1 "Mile";
VAL_ 1054 HUD_UserProfileId 0 "User 1 - Guess mode" 1 "User 2 - Valet mode" 2 "User 3" 3 "User 4" 4 "User 5" 5 "User 6" 6 "User 7" 7 "User 8" 8 "User 9" 9 "User 10" 10 "User 11" 11 "User 12" 12 "User 13" 13 "User 14" 14 "User 15" 15 "Invalid Value";
VAL_ 1054 HUD_DimmingDelayTime 0 "No delay" 1 "0.5" 2 "Reserved" 3 "Reserved";
VAL_ 1055 PAS_SVM_LCamera_Fault 0 "No fault" 1 "Temp fault(clean fix)" 2 "Temp fault(Environment)" 3 "Permanent fault" ;
VAL_ 1055 PAS_SVM_FCamera_Fault 0 "No fault" 1 "Temp fault(clean fix)" 2 "Temp fault(Environment)" 3 "Permanent fault" ;
VAL_ 1055 PAS_SVM_RCamera_Fault 0 "No fault" 1 "Temp fault(clean fix)" 2 "Temp fault(Environment)" 3 "Permanent fault" ;
VAL_ 1055 PAS_SVM_RightCamera_Fault 0 "No fault" 1 "Temp fault(Environment" 2 "Permanent Fault" ;
VAL_ 1058 MHU_STAT_Cluster 0 "OFF" 1 "ON" 2 "Reserved" 3 "Signal invalid";
VAL_ 1058 MHU_STAT_Infotainment 0 "OFF" 1 "ON" 2 "Reserved" 3 "Signal invalid";
VAL_ 1058 MHU_STAT_MileageUnit 0 "Mile" 1 "KM" 2 "Reserved" 3 "Signal invalid";
VAL_ 1058 MHU_STAT_PressureUnit 0 "Bar" 1 "Psi" 2 "Kpa" 3 "Signal invalid";
VAL_ 1058 MHU_STAT_TemperatureUnit 0 "Celcius" 1 "Fahrenheit" 2 "Reserved" 3 "Signal invalid";
VAL_ 1058 MHU_STAT_DateTimeFormat 0 "24H" 1 "12H" 2 "Reserved" 3 "Signal invalid";
VAL_ 1058 MHU_Operation_State 0 "Sleep - Low power mode" 1 "Standby/Screen OFF" 2 "Booting/Rebooting" 3 "Running" 4 "Standby/Fullscreen" 5 "OTA progess" 6 "Fault" 7 "Signal Invalid";
VAL_ 1058 MHU_STAT_Language 0 "Vietnamese" 1 "English" 2 "Spanish" 3 "French" 4 "German" 5 "Dutch" 6 "English (CANADA)" 7 "French (CANADA)" 8 "Russian" 9 "Spanish (Latin America)" 10 "Portuguese" 11 "Portuguese (Brasil)" 12 "Chinese, simplipied" 13 "Chinese, traditional" 14 "Reserved" 15 "Reserved" 16 "Reserved" 17 "Reserved" 18 "Reserved" 19 "Reserved" 20 "Reserved" 21 "Reserved" 22 "Reserved" 23 "Reserved" 24 "Reserved" 25 "Reserved" 26 "Reserved" 27 "Reserved" 28 "Reserved" 29 "Reserved" 30 "Reserved" 31 "Signal invalid";
VAL_ 1058 MHU_STAT_EnergyConsumptionUnit 0 "KWH/100KM" 1 "KM/KWH" 2 "Mile per KWH" 3 "KWH/100mil" 4 "Reserved" 5 "Reserved" 6 "Reserved" 7 "Signal invalid";
VAL_ 1058 MHU_STAT_BatLvlPopsetting 0 "20%" 1 "30%" 2 "40%" 3 "50%" 4 "60%" 5 "70%" 6 "Signal Invalid";
VAL_ 1058 MHU_STAT_DistToEmptyUnit 0 "%percentage" 1 "KM/Mi" 2 "Reserved" 3 "Signal Invalid";
VAL_ 1059 AVAS_BatteryUnderVoltage 0 "Normal" 1 "Failure";
VAL_ 1059 AVAS_BatteryOverVoltage 0 "Normal" 1 "Failure";
VAL_ 1059 AVAS_VINInfoNotPrgm 0 "Normal" 1 "Failure";
VAL_ 1059 AVAS_AMPVoltSplDrvOperationFail 0 "Normal" 1 "Failure";
VAL_ 1059 AVAS_AMPIntFaultOverCurr 0 "Normal" 1 "Failure";
VAL_ 1059 AVAS_AMPInternalFaultDCError 0 "Normal" 1 "Failure";
VAL_ 1059 AVAS_AMPInternalFaultOverTemp 0 "Normal" 1 "Failure";
VAL_ 1059 AVAS_AMPInternalFaultClockError 0 "Normal" 1 "Failure";
VAL_ 1059 AVAS_SpkrMntPwrSwDrvHighFlt 0 "Normal" 1 "Failure";
VAL_ 1059 AVAS_SpkrMntPwrSwDrvLowFlt 0 "Normal" 1 "Failure";
VAL_ 1059 AVAS_InternalSpeakerOpen 0 "Normal" 1 "Failure";
VAL_ 1059 AVAS_ECUMalFlshOperationErr 0 "Normal" 1 "Failure";
VAL_ 1059 AVAS_ECUMalfunctionRamFailure 0 "Normal" 1 "Failure";
VAL_ 1059 AVAS_ECUMalEEPROMFailure 0 "Normal" 1 "Failure";
VAL_ 1059 AVAS_CANBusOff 0 "Normal" 1 "Failure";
VAL_ 1059 AVAS_LossCommVehicleSpeed 0 "Normal" 1 "Failure";
VAL_ 1059 AVAS_LossCommGearPosition 0 "Normal" 1 "Failure";
VAL_ 1059 AVAS_LossCommAVASCloseCmd 0 "Normal" 1 "Failure";
VAL_ 1064 TRMFitted 0 "Unsupported" 1 "Fitted" 2 "Not Fitted" 3 "SNA" ;
VAL_ 1068 PSM_D_DrvSeat_Control_Status 0 "Idle" 1 "Moving by MHU" 2 "Moving by switch" 3 "Failure" 4 "Reserved" 5 "Reserved" 6 "Reserved" 7 "Invalid";
VAL_ 1069 XGW_WasherFluid_LevelSwitch 0 "Empty" 1 "Not Empty" 2 "error" 3 "Invalid signal";
VAL_ 1070 XGW_HLVerLvlMode 0 "OFF" 1 "AUTO Head lamp leveling ON" 2 "Reserved" 3 "Invalid";
VAL_ 1070 XGW_AutoHeadlamp_LvlSts 0 "Inactive" 1 "Active" 2 "Error" 3 "Signal invalid";
VAL_ 1073 HUD_ECU_Check 0 "Normal" 1 "LCD fail" 2 "LCD overhead" 3 "Step motor lost step" 4 "Low temperature";
VAL_ 1073 HUD_ECU_Fault 0 "Normal" 1 "Abnormal";
VAL_ 1074 MHU_FOTA_State 0 "INIT" 1 "NORMAL" 2 "FOTA FLASHING" 3 "FOTA-SUSPENDED" 4 "FAIL-SAFE-ERROR" 5 "SHUTDOWN" 6 "REMOTE DIAGNOSTICS" 7 "Invalid";
VAL_ 1075 MHU_HLVerLvlMode 0 "OFF" 1 "AUTO Head lamp enable" 2 "Reserved" 3 "Invalid";
VAL_ 1077 BCM_SCM_BC_Button 0 "Button not Pressed" 1 "Short Press" 2 "Long Press" 3 "Signal invalid";
VAL_ 1078 MHU_TELStatus 0 "Incomming" 1 "Outgoing" 2 "Connect" 3 "End" 4 "Reserved" 5 "Reserved" 6 "Reserved" 7 "Signal invalid";
VAL_ 1078 MHU_MUTEStatus 0 "MUTE OFF" 1 "MUTE ON" 2 "Reserved" 3 "Signal invalid";
VAL_ 1078 MHU_TEL_source 0 "Bluetooth" 1 "Android Auto" 2 "Carplay" 3 "T-BOX" 4 "VNC" 5 "Reserved" 6 "Reserved" 7 "Signal Invalid";
VAL_ 1079 VCU_SpdLimiterSts 0 "OFF" 1 "Standby" 2 "Active" 3 "Override" 4 "Fault" 5 "Reserved" 6 "Reserved" ;
VAL_ 1079 VCU_LimiterSpeed 255 "Signal Invalid";
VAL_ 1079 VCU_SpdLim_OverrideSts 0 "OFF" 1 "10km/h" 2 "20km/h" 3 "30km/h" 4 "Reserved" 5 "Invalid";
VAL_ 1080 EDS_FailGrade_ERR_FWD 0 "No fault" 1 "First-Level warning" 2 "Second Fault Limited power" 3 "Third Fault Limp" 4 "Forth Fault, ZeroTorque" 5 "Fifth Fault, Delayed power off" 6 "Invaild" 7 "Invaild";
VAL_ 1080 EDS_MotOverTempAlarm_FWD 0 "Normal" 1 "Error";
VAL_ 1080 EDS_MotOverTempFault_FWD 0 "Normal" 1 "Error";
VAL_ 1080 EDS_MotTempSenFault_FWD 0 "Normal" 1 "Error";
VAL_ 1080 EDS_EDSOverTempUFault_FWD 0 "Normal" 1 "Error";
VAL_ 1080 EDS_EDSOverTempVFault_FWD 0 "Normal" 1 "Error";
VAL_ 1080 EDS_EDSOverTempWFault_FWD 0 "Normal" 1 "Error";
VAL_ 1080 EDS_EDSOverTempAlarm_FWD 0 "Normal" 1 "Error";
VAL_ 1080 EDS_TCoolantOvHi_FWD 0 "Normal" 1 "Error";
VAL_ 1080 EDS_EDSTempCmpAlarm_FWD 0 "Normal" 1 "Error";
VAL_ 1080 EDS_EDSPhaOvCurentHWFault_FWD 0 "Normal" 1 "Error";
VAL_ 1080 EDS_EDSphaOffCalFault_FWD 0 "Normal" 1 "Error";
VAL_ 1080 EDS_EDSOverIdcLnkAlarm_FWD 0 "Normal" 1 "Error";
VAL_ 1080 EDS_EDSHVOverVoltageAlarm_FWD 0 "Normal" 1 "Error";
VAL_ 1080 EDS_EDSHVOverVoltageFault_FWD 0 "Normal" 1 "Error";
VAL_ 1080 EDS_EDSHVUnderVoltageAlarm_FWD 0 "Normal" 1 "Error";
VAL_ 1080 EDS_EDSHVUnderVoltageFault_FWD 0 "Normal" 1 "Error";
VAL_ 1080 EDS_RunToDischaErr_FWD 0 "Normal" 1 "Error";
VAL_ 1080 EDS_12VOverVoltageAlarm_FWD 0 "Normal" 1 "Error";
VAL_ 1080 EDS_12VUnderVoltageAlarm_FWD 0 "Normal" 1 "Error";
VAL_ 1080 EDS_MotOverAlarm_FWD 0 "Normal" 1 "Error";
VAL_ 1080 EDS_MotOverFault_FWD 0 "Normal" 1 "Error";
VAL_ 1080 EDS_ResolverOffsetAngle_FWD 0 "Normal" 1 "Error";
VAL_ 1081 EDS_FailGrade_ERR_RWD 0 "No fault" 1 "First-Level warning" 2 "Second Fault Limited power" 3 "Third Fault, Limp" 4 "Forth Fault, ZeroTorque" 5 "Fifth Fault, Delayed power off" 6 "Invaild" 7 "Invaild";
VAL_ 1081 EDS_MotOverTempAlarm_RWD 0 "Normal" 1 "Error";
VAL_ 1081 EDS_MotOverTempFault_RWD 0 "Normal" 1 "Error";
VAL_ 1081 EDS_MotTempSenFault_RWD 0 "Normal" 1 "Error";
VAL_ 1081 EDS_EDSOverTempUFault_RWD 0 "Normal" 1 "Error";
VAL_ 1081 EDS_EDSOverTempVFault_RWD 0 "Normal" 1 "Error";
VAL_ 1081 EDS_EDSOverTempWFault_RWD 0 "Normal" 1 "Error";
VAL_ 1081 EDS_EDSOverTempAlarm_RWD 0 "Normal" 1 "Error";
VAL_ 1081 EDS_TCoolantOvHi_RWD 0 "Normal" 1 "Error";
VAL_ 1081 EDS_EDSTempCmpAlarm_RWD 0 "Normal" 1 "Error";
VAL_ 1081 EDS_EDSPhaOvCurentHWFault_RWD 0 "Normal" 1 "Error";
VAL_ 1081 EDS_EDSphaOffCalFault_RWD 0 "Normal" 1 "Error";
VAL_ 1081 EDS_EDSOverIdcLnkAlarm_RWD 0 "Normal" 1 "Error";
VAL_ 1081 EDS_EDSHVOverVoltageAlarm_RWD 0 "Normal" 1 "Error";
VAL_ 1081 EDS_EDSHVOverVoltageFault_RWD 0 "Normal" 1 "Error";
VAL_ 1081 EDS_EDSHVUnderVoltageAlarm_RWD 0 "Normal" 1 "Error";
VAL_ 1081 EDS_EDSHVUnderVoltageFault_RWD 0 "Normal" 1 "Error";
VAL_ 1081 EDS_RunToDischaErr_RWD 0 "Normal" 1 "Error";
VAL_ 1081 EDS_12VOverVoltageAlarm_RWD 0 "Normal" 1 "Error";
VAL_ 1081 EDS_12VUnderVoltageAlarm_RWD 0 "Normal" 1 "Error";
VAL_ 1081 EDS_MotOverAlarm_RWD 0 "Normal" 1 "Error";
VAL_ 1081 EDS_MotOverFault_RWD 0 "Normal" 1 "Error";
VAL_ 1081 EDS_ResolverOffsetAngle_RWD 0 "Normal" 1 "Error";
VAL_ 1082 VCU_BrakeRegenMode 0 "HIGH" 1 "MID" 2 "LOW" 3 "OFF";
VAL_ 1082 VCU_AutoP_Feedback 3 "Signal Invalid" 2 "Reserved" 1 "OFF" 0 "ON" ;
VAL_ 1082 VCU_CreepDisable_stt 0 "Enable" 1 "Disable";
VAL_ 1082 VCU_Charging_Authen_stt 0 "Not authencating" 1 "Authenticating" 2 "Authen success" 3 "Authen failed" 4 "Forbidden vehicle" 5 "reserved" 6 "reserved" 7 "reserved";
VAL_ 1082 VCU_ChgGun_BadConn_stt 0 "No error" 1 "Bad connection";
VAL_ 1082 VCU_ChgPort_Open_stt 0 "Closed" 1 "Opening";
VAL_ 1082 VCU_Regen_available 0 "Not available" 1 "Available" 2 "Regen limit" 3 "Regen faut";
VAL_ 1082 VCU_VehChg_STS 0 "Charging not in progress and gun not plug-in" 1 "Charging in progress" 2 "Charging complete" 3 "Charge fault" 4 "Gun plugged-in, Standby" 5 "Gun plugged-in, Waiting" 6 "Reserved" 7 "Signal Invalid";
VAL_ 1082 VCU_StoppingMode_stt 0 "Off" 1 "CreepMode" 2 "RollMode" 3 "HoldMode" 4 "Reserved" 5 "Reserved" 6 "Reserved" 7 "Reserved";
VAL_ 1082 VCU_ChgGun_Status 0 "Charging gun not plugged" 1 "Locked" 2 "Released" 3 "Error due to plug voltage is higher than 60V." 4 "Error due to electrical failure of lock motor drive pins." 5 "Error due to electrical failure of lock feedback pins" 6 "Error plug lock feedback is received as error from BSW" 7 "Invalid";
VAL_ 1082 VCU_ChgPort_Lock_stt 0 "Locked" 1 "Released";
VAL_ 1082 VCU_Hvbatt_charging_stt 0 "Not charging" 1 "Charging";
VAL_ 1083 MHU_SET_SteeringAdjust 0 "OFF" 1 "ON" 2 "No Request" 3 "Restore steering pos";
VAL_ 1084 EASC_SteeringAdjust 0 "OFF" 1 "ON" 2 "Reserved" 3 "Restore steering pos";
VAL_ 1086 MHU_SET_Soundzone 0 "Invalid" 1 "Front" 2 "Rear" 3 "ALL";
VAL_ 1086 MHU_SET_MediaMute 0 "Invalid" 1 "Mute" 2 "Unmute" 3 "Reserved";
VAL_ 1087 MHU_SET_EQType 0 "Flat" 1 "Pop" 2 "Rock" 3 "Jazz" 4 "Classic" 5 "Vocal" 6 "Custom" 15 "Invalid";
VAL_ 1088 AMP_SET_EQType 0 "Flat" 1 "Pop" 2 "Rock" 3 "Jazz" 4 "Classic" 5 "Vocal" 6 "Custom" 15 "Invalid";
VAL_ 1090 WLC_IC_Error 0 "No Error" 1 "Error";
VAL_ 1090 WLC_FAN_Error 0 "No Error" 1 "Error";
VAL_ 1090 WLC_TempSNSR_Error 0 "No Error" 1 "Error";
VAL_ 1090 WLC_Setting_standard 0 "OFF (Disable)" 1 "ON (Enable)" 2 "Default" 3 "Invalid";
VAL_ 1090 Transmit_WLC_situation 0 "Power OFF" 1 "Cellphone reminder" 2 "Charging" 3 "Charging complete" 4 "Wakeup" 5 "Error" 6 "Reserved" 7 "Invalid";
VAL_ 1090 WLC_VehSpeed_Error 0 "No Error" 1 "Error";
VAL_ 1090 WLC_Resp_Error 0 "No Error" 1 "Error";
VAL_ 1090 WLC_FOD_Error 0 "No Error" 1 "Error";
VAL_ 1090 WLC_Curr_Error 0 "No Error" 1 "Error";
VAL_ 1090 WLC_Temp_Error 0 "No Error" 1 "Error";
VAL_ 1091 WLC_IC_Error_2 0 "No Error" 1 "Error";
VAL_ 1091 WLC_FAN_Error_2 0 "No Error" 1 "Error";
VAL_ 1091 WLC_TempSNSR_Error_2 0 "No Error" 1 "Error";
VAL_ 1091 WLC_Setting_standard_2 0 "OFF (Disable)" 1 "ON (Enable)" 2 "Default" 3 "Invalid";
VAL_ 1091 Transmit_WLC_situation_2 0 "Power OFF" 1 "Cellphone reminder" 2 "Charging" 3 "Charging complete" 4 "Wakeup" 5 "Error" 6 "Reserved" 7 "Invalid";
VAL_ 1091 WLC_VehSpeed_Error_2 0 "No Error" 1 "Error";
VAL_ 1091 WLC_Resp_Error_2 0 "No Error" 1 "Error";
VAL_ 1091 WLC_FOD_Error_2 0 "No Error" 1 "Error";
VAL_ 1091 WLC_Curr_Error_2 0 "No Error" 1 "Error";
VAL_ 1091 WLC_Temp_Error_2 0 "No Error" 1 "Error";
VAL_ 1092 MHU_RPParkingstartReq 0 "no request" 1 "request";
VAL_ 1092 MHU_RP_ParkOutModeConfirm 0 "No request" 1 "Perpendicular parking" 2 "parallel parking" 3 "Angled parking";
VAL_ 1092 MHU_RP_ParkOutDircnConfirm 0 "No request" 1 "left" 2 "right";
VAL_ 1092 MHU_RemoteconnectionSts 0 "Disconnect" 1 "Connect";
VAL_ 1092 MHU_RP_FuncMode 0 "No function" 1 "Parking in" 2 "parking out" 3 "drag parking" 4 "Straight in straight out";
VAL_ 1092 MHU_SMParkingstartReq 0 "no request" 1 "request";
VAL_ 1092 MHU_SMParkingControlReq 0 "no request" 1 "request";
VAL_ 1092 MHU_RP_RecoverParking 0 "no request" 1 "request";
VAL_ 1092 MHU_RPStraightParkingDir 0 "-" 1 "forward" 2 "back";
VAL_ 1092 MHU_SM_global_path_Status 0 "not available" 1 "available" 2 "Reserved";
VAL_ 1092 MHU_SM_QuitReq 0 "No request" 1 "request exit" 2 "request exit and flameout";
VAL_ 1092 MHU_RPParkingControlReq 0 "no request" 1 "request";
VAL_ 1092 MHU_RP_QuitReq 0 "no request" 1 "request exit" 2 "request exit and flameout";
VAL_ 1093 RS_Sol_L 254 "HW failure solar sensor" 255 "Signal invalid";
VAL_ 1093 RS_Sol_R 254 "HW failure solar sensor" 255 "Signal invalid";
VAL_ 1093 RS_F_LightSensor 0 "No error" 1 "Light sensor error";
VAL_ 1093 RS_F_HUD_Sensor 0 "No error" 1 "HUD error";
VAL_ 1093 RS_St_LampReq 0 "OFF" 1 "ON" 2 "Reserved" 3 "Invalid";
VAL_ 1093 RS_St_CurrentRain 0 "No rain" 1 "level 1(light rain)" 2 "level 2(moderate rain)" 3 "level 3(heavy rain)" 4 "Reserved" 5 "Reserved" 6 "Reserved" 7 "Signal invalid";
VAL_ 1093 RS_HUD_illuminance 65535 "Invalid";
VAL_ 1094 MHU_DrivingSide 0 "Left handside" 1 "Right handside";
VAL_ 1094 MHU_Junction_type 0 "Single intersection" 1 "Roundabout" 2 "Reserved" 3 "Signal Invalid";
VAL_ 1094 MHU_JunctionElement1 0 "No direction" 1 "direction 1 (162deg)" 2 "direction 2 (144deg)" 3 "direction 3 (126deg)" 4 "direction 4 (108deg)" 5 "direction 5 (90deg) - Right" 6 "direction 6 (72deg)" 7 "direction 7 (54deg)" 8 "direction 8 (36deg)" 9 "direction 9 (18deg)" 10 "direction 10 (0 deg) - Top" 11 "direction 11 (-18deg)" 12 "direction 12 (-36deg)" 13 "direction 13 (-54deg)" 14 "direction 14 (-72deg)" 15 "direction 15 (-90) - Left" 16 "direction 16 (-108)" 17 "direction 17 (-126)" 18 "direction 18 (-144)" 19 "direction 19 (-162)" 20 "Left U-turn (-180)" 21 "Right U-turn (180)";
VAL_ 1094 MHU_JunctionElement0 0 "No direction" 1 "direction 1 (162deg)" 2 "direction 2 (144deg)" 3 "direction 3 (126deg)" 4 "direction 4 (108deg)" 5 "direction 5 (90deg) - Right" 6 "direction 6 (72deg)" 7 "direction 7 (54deg)" 8 "direction 8 (36deg)" 9 "direction 9 (18deg)" 10 "direction 10 (0 deg) - Top" 11 "direction 11 (-18deg)" 12 "direction 12 (-36deg)" 13 "direction 13 (-54deg)" 14 "direction 14 (-72deg)" 15 "direction 15 (-90) - Left" 16 "direction 16 (-108)" 17 "direction 17 (-126)" 18 "direction 18 (-144)" 19 "direction 19 (-162)" 20 "Left U-turn (-180)" 21 "Right U-turn (180)";
VAL_ 1094 MHU_JunctionElement2 0 "No direction" 1 "direction 1 (162deg)" 2 "direction 2 (144deg)" 3 "direction 3 (126deg)" 4 "direction 4 (108deg)" 5 "direction 5 (90deg) - Right" 6 "direction 6 (72deg)" 7 "direction 7 (54deg)" 8 "direction 8 (36deg)" 9 "direction 9 (18deg)" 10 "direction 10 (0 deg) - Top" 11 "direction 11 (-18deg)" 12 "direction 12 (-36deg)" 13 "direction 13 (-54deg)" 14 "direction 14 (-72deg)" 15 "direction 15 (-90) - Left" 16 "direction 16 (-108)" 17 "direction 17 (-126)" 18 "direction 18 (-144)" 19 "direction 19 (-162)" 20 "Left U-turn (-180)" 21 "Right U-turn (180)";
VAL_ 1094 MHU_JunctionElement4 0 "No direction" 1 "direction 1 (162deg)" 2 "direction 2 (144deg)" 3 "direction 3 (126deg)" 4 "direction 4 (108deg)" 5 "direction 5 (90deg) - Right" 6 "direction 6 (72deg)" 7 "direction 7 (54deg)" 8 "direction 8 (36deg)" 9 "direction 9 (18deg)" 10 "direction 10 (0 deg) - Top" 11 "direction 11 (-18deg)" 12 "direction 12 (-36deg)" 13 "direction 13 (-54deg)" 14 "direction 14 (-72deg)" 15 "direction 15 (-90) - Left" 16 "direction 16 (-108)" 17 "direction 17 (-126)" 18 "direction 18 (-144)" 19 "direction 19 (-162)" 20 "Left U-turn (-180)" 21 "Right U-turn (180)";
VAL_ 1094 MHU_JunctionElement3 0 "No direction" 1 "direction 1 (162deg)" 2 "direction 2 (144deg)" 3 "direction 3 (126deg)" 4 "direction 4 (108deg)" 5 "direction 5 (90deg) - Right" 6 "direction 6 (72deg)" 7 "direction 7 (54deg)" 8 "direction 8 (36deg)" 9 "direction 9 (18deg)" 10 "direction 10 (0 deg) - Top" 11 "direction 11 (-18deg)" 12 "direction 12 (-36deg)" 13 "direction 13 (-54deg)" 14 "direction 14 (-72deg)" 15 "direction 15 (-90) - Left" 16 "direction 16 (-108)" 17 "direction 17 (-126)" 18 "direction 18 (-144)" 19 "direction 19 (-162)" 20 "Left U-turn (-180)" 21 "Right U-turn (180)";
VAL_ 1094 MHU_JunctionElement5 0 "No direction" 1 "direction 1 (162deg)" 2 "direction 2 (144deg)" 3 "direction 3 (126deg)" 4 "direction 4 (108deg)" 5 "direction 5 (90deg) - Right" 6 "direction 6 (72deg)" 7 "direction 7 (54deg)" 8 "direction 8 (36deg)" 9 "direction 9 (18deg)" 10 "direction 10 (0 deg) - Top" 11 "direction 11 (-18deg)" 12 "direction 12 (-36deg)" 13 "direction 13 (-54deg)" 14 "direction 14 (-72deg)" 15 "direction 15 (-90) - Left" 16 "direction 16 (-108)" 17 "direction 17 (-126)" 18 "direction 18 (-144)" 19 "direction 19 (-162)" 20 "Left U-turn (-180)" 21 "Right U-turn (180)";
VAL_ 1094 MHU_JunctionElement6 0 "No direction" 1 "direction 1 (162deg)" 2 "direction 2 (144deg)" 3 "direction 3 (126deg)" 4 "direction 4 (108deg)" 5 "direction 5 (90deg) - Right" 6 "direction 6 (72deg)" 7 "direction 7 (54deg)" 8 "direction 8 (36deg)" 9 "direction 9 (18deg)" 10 "direction 10 (0 deg) - Top" 11 "direction 11 (-18deg)" 12 "direction 12 (-36deg)" 13 "direction 13 (-54deg)" 14 "direction 14 (-72deg)" 15 "direction 15 (-90) - Left" 16 "direction 16 (-108)" 17 "direction 17 (-126)" 18 "direction 18 (-144)" 19 "direction 19 (-162)" 20 "Left U-turn (-180)" 21 "Right U-turn (180)";
VAL_ 1095 MHU_SET_TransportMode 0 "No request" 1 "Request ON" 2 "Request OFF" 3 "Signal Invalid" ;
VAL_ 1095 MHU_Request_CarOFF 0 "Not Request" 1 "Request Car goes to OFF" 2 "Reserved" 3 "Signal Invalid";
VAL_ 1095 MHU_SET_ChildMode 0 "Child Mode OFF" 1 "Child mode ON" 2 "Reserved" 3 "Signal Invalid";
VAL_ 1095 MHU_SET_GameMode 0 "Game mode OFF" 1 "Game mode ON" 2 "Reserved" 3 "Signal Invalid";
VAL_ 1095 MHU_SET_KaraokeMode 0 "Karaoke mode OFF" 1 "Karaoke ON" 2 "Reserved" 3 "Signal Invalid";
VAL_ 1095 MHU_Req_StoppingMode 0 "Off" 1 "CreepMode" 2 "RollMode" 3 "HoldMode" 4 "NoRequest" 5 "Reserved" 6 "Reserved" 7 "Invalid";
VAL_ 1095 MHU_SET_WashMode 0 "Wash mode OFFt" 1 "Wash mode ON" 2 "Reserved" 3 "Signal Invalid";
VAL_ 1095 MHU_SET_StopMode 0 "Creep" 1 "Hold" 2 "Roll" 3 "Signal Invalid";
VAL_ 1095 MHU_AVH_Sw 0 "No Action" 1 "ON" 2 "OFF" 3 "Reserved";
VAL_ 1096 EDS_iDcLnkOvCLimFail_FWD 0 "Normal" 1 "Error";
VAL_ 1096 EDS_MotBlockedFault_FWD 0 "Normal" 1 "Error";
VAL_ 1096 EDS_RSLErr_FWD 0 "Normal" 1 "Error";
VAL_ 1096 EDS_MotTrqLimFault_FWD 0 "Normal" 1 "Error";
VAL_ 1096 EDS_VCUChksumFault_FWD 0 "Normal" 1 "Error";
VAL_ 1096 EDS_IGBTFault_FWD 0 "Normal" 1 "Error";
VAL_ 1096 EDS_CANBusoffFault_FWD 0 "Normal" 1 "Error";
VAL_ 1096 EDS_TDrvBoardOvHiWarn_FWD 0 "Normal" 1 "Error";
VAL_ 1096 EDS_TIGBTOvHiFault_FWD 0 "Normal" 1 "Error";
VAL_ 1096 EDS_TIGBTOvHiWarn_FWD 0 "Normal" 1 "Error";
VAL_ 1096 EDS_IOHWABSampFail_FWD 0 "Normal" 1 "Error";
VAL_ 1096 EDS_EDSOpenFault_FWD 0 "Normal" 1 "Error";
VAL_ 1096 EDS_MotorOpenFault_FWD 0 "Normal" 1 "Error";
VAL_ 1096 EDS_EparkSampFail_FWD 0 "Normal" 1 "Error";
VAL_ 1096 EDS_EmacBlkdWarn_FWD 0 "Normal" 1 "Error";
VAL_ 1096 EDS_VerMatchFailureErr_FWD 0 "Normal" 1 "Error";
VAL_ 1096 EDS_DiashCirNoPsblErr_FWD 0 "Normal" 1 "Error";
VAL_ 1096 EDS_OperOutdRngErr_FWD 0 "Normal" 1 "Error";
VAL_ 1096 EDS_PhaseLossFaultErr_FWD 0 "Normal" 1 "Error";
VAL_ 1096 EDS_CPLDFault_FWD 0 "Normal" 1 "Error";
VAL_ 1096 EDS_CPLDFaultBaseSpd_FWD 0 "Normal" 1 "Error";
VAL_ 1096 EDS_IOHWABNen33Fail_FWD 0 "Normal" 1 "Error";
VAL_ 1096 EDS_HvMcuSlightFault_FWD 0 "Normal" 1 "Error";
VAL_ 1096 EDS_HvMcuSevFault_FWD 0 "Normal" 1 "Error";
VAL_ 1096 EDS_EDSPhaSampHWFault_FWD 0 "Normal" 1 "Error";
VAL_ 1096 EDS_IsOvHiErr_FWD 0 "Normal" 1 "Error";
VAL_ 1096 EDS_CanRollingCounterErr_FWD 0 "Normal" 1 "Error";
VAL_ 1096 EDS_CanTimeoutErr_FWD 0 "Normal" 1 "Error";
VAL_ 1096 EDS_CrashFault_FWD 0 "Normal" 1 "Error";
VAL_ 1096 EDS_PCFSlightFault_FWD 0 "Normal" 1 "Error";
VAL_ 1096 EDS_PCFSerFault_FWD 0 "Normal" 1 "Error";
VAL_ 1097 EDS_iDcLnkOvCLimFail_RWD 0 "Normal" 1 "Error";
VAL_ 1097 EDS_MotBlockedFault_RWD 0 "Normal" 1 "Error";
VAL_ 1097 EDS_RSLErr_RWD 0 "Normal" 1 "Error";
VAL_ 1097 EDS_MotTrqLimFault_RWD 0 "Normal" 1 "Error";
VAL_ 1097 EDS_VCUChksumFault_RWD 0 "Normal" 1 "Error";
VAL_ 1097 EDS_IGBTFault_RWD 0 "Normal" 1 "Error";
VAL_ 1097 EDS_CANBusoffFault_RWD 0 "Normal" 1 "Error";
VAL_ 1097 EDS_TDrvBoardOvHiWarn_RWD 0 "Normal" 1 "Error";
VAL_ 1097 EDS_TIGBTOvHiFault_RWD 0 "Normal" 1 "Error";
VAL_ 1097 EDS_TIGBTOvHiWarn_RWD 0 "Normal" 1 "Error";
VAL_ 1097 EDS_IOHWABSampFail_RWD 0 "Normal" 1 "Error";
VAL_ 1097 EDS_EDSOpenFault_RWD 0 "Normal" 1 "Error";
VAL_ 1097 EDS_MotorOpenFault_RWD 0 "Normal" 1 "Error";
VAL_ 1097 EDS_EparkSampFail_RWD 0 "Normal" 1 "Error";
VAL_ 1097 EDS_EmacBlkdWarn_RWD 0 "Normal" 1 "Error";
VAL_ 1097 EDS_VerMatchFailureErr_RWD 0 "Normal" 1 "Error";
VAL_ 1097 EDS_DiashCirNoPsblErr_RWD 0 "Normal" 1 "Error";
VAL_ 1097 EDS_OperOutdRngErr_RWD 0 "Normal" 1 "Error";
VAL_ 1097 EDS_PhaseLossFaultErr_RWD 0 "Normal" 1 "Error";
VAL_ 1097 EDS_CPLDFault_RWD 0 "Normal" 1 "Error";
VAL_ 1097 EDS_CPLDFaultBaseSpd_RWD 0 "Normal" 1 "Error";
VAL_ 1097 EDS_IOHWABNen33Fail_RWD 0 "Normal" 1 "Error";
VAL_ 1097 EDS_HvMcuSlightFault_RWD 0 "Normal" 1 "Error";
VAL_ 1097 EDS_HvMcuSevFault_RWD 0 "Normal" 1 "Error";
VAL_ 1097 EDS_EDSPhaSampHWFault_RWD 0 "Normal" 1 "Error";
VAL_ 1097 EDS_IsOvHiErr_RWD 0 "Normal" 1 "Error";
VAL_ 1097 EDS_CanRollingCounterErr_RWD 0 "Normal" 1 "Error";
VAL_ 1097 EDS_CanTimeoutErr_RWD 0 "Normal" 1 "Error";
VAL_ 1097 EDS_CrashFault_RWD 0 "Normal" 1 "Error";
VAL_ 1097 EDS_PCFSlightFault_RWD 0 "Normal" 1 "Error";
VAL_ 1097 EDS_PCFSerFault_RWD 0 "Normal" 1 "Error";
VAL_ 1104 MHU_SET_WindowLifterFrontL 0 "No action" 1 "Manual open" 2 "Automatic open" 3 "Manual close" 4 "Automatic close" 5 "Slightly open" 6 "Reserved" 7 "Signal invalid";
VAL_ 1104 MHU_SET_WindowLifterFrontR 0 "No action" 1 "Manual open" 2 "Automatic open" 3 "Manual close" 4 "Automatic close" 5 "Slightly open" 6 "Reserved" 7 "Signal invalid";
VAL_ 1104 MHU_SET_WindowLifterRearL 0 "No action" 1 "Manual open" 2 "Automatic open" 3 "Manual close" 4 "Automatic close" 5 "Slightly open" 6 "Reserved" 7 "Signal invalid";
VAL_ 1104 MHU_SET_WindowLifterRearR 0 "No action" 1 "Manual open" 2 "Automatic open" 3 "Manual close" 4 "Automatic close" 5 "Slightly open" 6 "Reserved" 7 "Signal invalid";
VAL_ 1104 MHU_SET_WindowAutoClose 0 "OFF" 1 "ON" 2 "Reserved" 3 "Signal invalid";
VAL_ 1106 MHU_SET_ANN1_MODE 0 "Invalid" 1 "Navigation" 2 "Telephone" 3 "Prompts";
VAL_ 1107 MHU_SET_ANN1_PROMPTS_SPEAKER 0 "Invalid" 1 "Select FL_FR" 2 "Select CEN" 3 "Select FL_FR_CEN" 4 "Select RL_RR" 5 "Select All" 6 "Reserved";
VAL_ 1108 MHU_SET_ANN2_CEN_Mute 0 "Invalid" 1 "Mute ANN2 CEN" 2 "UnMute ANN2 CEN";
VAL_ 1108 MHU_SET_ANN2_RR_Mute 0 "Invalid" 1 "Mute ANN2 RR" 2 "UnMute ANN2 RR";
VAL_ 1108 MHU_SET_ANN2_RL_Mute 0 "Invalid" 1 "Mute ANN2 RL" 2 "Unmute ANN2 RL";
VAL_ 1108 MHU_SET_ANN2_FR_Mute 0 "Invalid" 1 "Mute ANN2 FR" 2 "UnMute ANN2 FR";
VAL_ 1108 MHU_SET_ANN2_FL_Mute 0 "Invalid" 1 "Mute ANN2 FL" 2 "UnMute ANN2 FL";
VAL_ 1109 AMP_SET_Soundzone 0 "Invalid" 1 "Front" 2 "Rear" 3 "ALL";
VAL_ 1109 AMP_SET_MediaMute 0 "Invalid" 1 "Mute" 2 "Unmute" 3 "Reserved";
VAL_ 1110 OP_WISW_SZL_LIN 0 "No action" 255 "Signal Invalid";
VAL_ 1110 COMM_ERR_SZL_LIN 0 "No error" 1 "Error active";
VAL_ 1110 BCM_Wiper_Front_Status 0 "OFF" 1 "Mist" 2 "IntermittentAuto" 3 "Low Speed" 4 "High Speed" 5 "Reserved" 6 "Reserved" 7 "Invalid";
VAL_ 1110 OP_WIPO_SZL_LIN 0 "Step 1" 1 "Step 2" 2 "Step 3" 4 "Step 4" 7 "Signal Invalid";
VAL_ 1110 OP_COLS_SZL_LIN 0 "No action" 255 "Signal Invalid";
VAL_ 1110 NOD_ERR_SZL_LIN 0 "NO error" 1 "error active" 2 "error Stat change" 3 "Signal invalid";
VAL_ 1110 BCM_Wiper_Rear_Status 0 "OFF" 1 "ON" 2 "Reserved" 3 "Signal Invalid";
VAL_ 1111 AmbLight_Error_Z5 0 "No Error" 1 "Error";
VAL_ 1111 AmbLight_Error_Z4 0 "No Error" 1 "Error";
VAL_ 1111 AmbLight_Error_Z3 0 "No Error" 1 "Error";
VAL_ 1111 AmbLight_Error_Z2 0 "No Error" 1 "Error";
VAL_ 1111 AmbLight_Error_Z1 0 "No Error" 1 "Error";
VAL_ 1112 AmbLightColorZoneReq 0 "no zone" 1 " ALM Zone 1 = CSUV_ALM Cockpit_DSUV_COCKPIT_DRIVER " 2 " ALM Zone 2 = CSUV_ALM Right Front Door_DSUV_COCKPIT_PASSANGER" 3 "ALM Zone 3 = CSUV_ALM Left Front Door_DSUV_FRT_DOOR_LH" 4 "ALM Zone 4 = CSUV_ALM Right Rear Door_DSUV_FRT_DOOR_RH" 5 "ALM Zone 5 = CSUV_ALM Left Rear Door_DSUV_RR_DOOR_RH" 6 "ALM Zone 6 = DSUV_RR_DOOR_RH" 7 "ALM Zone 7 = DSUV_CENTER_CONSOLE_DRIVER" 8 "ALM Zone 8 = DSUV_CENTER_CONSOLE_PASSANGER" 9 "ALM Zone 9 = DSUV_CENTER_CONSOLE_RR_DRIVER" 10 "ALM Zone 10 = DSUV_CENTER_CONSOLE_RR_PASSANGER";
VAL_ 1113 AmbLightIntensityTimingTypeReq 0 "None" 1 "Blinking" 2 "Wave" 3 "Morse" 4 "Fading";
VAL_ 1115 HOD_steering_wheel_type 0 "LEATHER" 1 "Reserved" 2 "Reserved" 3 "Reserved" 15 "Invalid value" ;
VAL_ 1115 HOD_vehicle_type 0 "VFe35" 1 "VFe36" 2 "Reserved" 3 "Reserved" 4 "Reserved" 255 "invalid value" ;
VAL_ 1115 ADAS_HOD_state_requesting 0 "Sleep_mode_requesting" 1 "Reserved" 2 "Normal_mode_requesting" 3 "Invalid value" ;
VAL_ 1124 LDML_LampAssemblySts 0 "Normal" 1 "Fault" 2 "Reserved" 3 "Signal Invalid";
VAL_ 1124 LDML_PosLmpSts 0 "OFF" 1 "ON" 2 "Fault" 3 "Signal Invalid";
VAL_ 1124 LDML_ControllerSts 0 "Normal" 1 "Fault" 2 "Reserved" 3 "Signal Invalid";
VAL_ 1124 LDML_TurnIndicatorSts 0 "OFF" 1 "ON" 2 "Fault" 3 "Signal Invalid";
VAL_ 1124 LDML_AuxLBSts 0 "OFF" 1 "ON" 2 "Fault" 3 "Signal Invalid";
VAL_ 1124 LDML_LowBeamSts 0 "OFF" 1 "ON" 2 "Fault" 3 "Signal Invalid ";
VAL_ 1124 LDML_HighBeamSts 0 "OFF" 1 "ON" 2 "Fault" 3 "Signal Invalid";
VAL_ 1124 LDML_DayRunningLampSts 0 "OFF" 1 "ON" 2 "Fault" 3 "Signal Invalid";
VAL_ 1124 LDML_DayTimeRunningLightFbSts 0 "OFF" 1 "ON" 2 "Reserved" 3 "Signal Invalid";
VAL_ 1124 LDML_AutoLvlFbSts 0 "OFF" 1 "ON" 2 "Reserved" 3 "Signal Invalid";
VAL_ 1124 LDML_AdptvDrvBeamFbSts 0 "OFF" 1 "ON" 2 "Reserved" 3 "Signal Invalid";
VAL_ 1124 LDML_AuxHBSts 0 "OFF" 1 "ON" 2 "Fault" 3 "Signal Invalid";
VAL_ 1124 LDML_FollowMeHomeFbSts 0 "OFF" 1 "30 secs" 2 "60 secs" 3 "90 secs" 4 "120 secs" 5 "Signal Invalid";
VAL_ 1124 LDML_ExteriorLightFbSts 0 "OFF" 1 "Parking" 2 "Low Beam" 3 "AUTO" 4 "Signal Invalid";
VAL_ 1124 LDML_AHB_ICON_Feed 0 "off " 1 "gray icon" 2 "green icon" 3 "SNA";
VAL_ 1125 LDMR_LampAssemblySts 0 "Normal" 1 "Fault" 2 "Reserved" 3 "Signal Invalid";
VAL_ 1125 LDMR_PosLmpSts 0 "OFF" 1 "ON" 2 "Fault" 3 "Signal Invalid";
VAL_ 1125 LDMR_ControllerSts 0 "Normal" 1 "Fault" 2 "Reserved" 3 "Signal Invalid";
VAL_ 1125 LDMR_TurnIndicatorSts 0 "OFF" 1 "ON" 2 "Fault" 3 "Signal Invalid";
VAL_ 1125 LDMR_AuxLBSts 0 "OFF" 1 "ON" 2 "Fault" 3 "Signal Invalid";
VAL_ 1125 LDMR_LowBeamSts 0 "OFF" 1 "ON" 2 "Fault" 3 "Signal Invalid ";
VAL_ 1125 LDMR_HighBeamSts 0 "OFF" 1 "ON" 2 "Fault" 3 "Signal Invalid";
VAL_ 1125 LDMR_DayRunningLampSts 0 "OFF" 1 "ON" 2 "Fault" 3 "Signal Invalid";
VAL_ 1125 LDMR_DayTimeRunningLightFbSts 0 "OFF" 1 "ON" 2 "Reserved" 3 "Signal Invalid";
VAL_ 1125 LDMR_AutoLvlFbSts 0 "OFF" 1 "ON" 2 "Reserved" 3 "Signal Invalid";
VAL_ 1125 LDMR_AdptvDrvBeamFbSts 0 "OFF" 1 "ON" 2 "Reserved" 3 "Signal Invalid";
VAL_ 1125 LDMR_AuxHBSts 0 "OFF" 1 "ON" 2 "Fault" 3 "Signal Invalid";
VAL_ 1125 LDMR_FollowMeHomeFbSts 0 "OFF" 1 "30 secs" 2 "60 secs" 3 "90 secs" 4 "120 secs" 5 "Signal Invalid";
VAL_ 1125 LDMR_ExteriorLightFbSts 0 "OFF" 1 "Parking" 2 "Low Beam" 3 "AUTO" 4 "Signal Invalid";
VAL_ 1125 LDMR_AHB_ICON_Feed 0 "off " 1 "gray icon" 2 "green icon" 3 "SNA";
VAL_ 1136 AMP_SET_ANN1_MODE 0 "Invalid" 1 "Navigation" 2 "Telephone" 3 "Prompts";
VAL_ 1137 AMP_SET_ANN1_PROMPTS_SPEAKER 0 "Invalid" 1 "Select FL_FR" 2 "Select CEN" 3 "Select FL_FR_CEN" 4 "Select RL_RR" 5 "Select All" 6 "Reserved";
VAL_ 1138 AMP_SET_ANN2_CEN_Mute 0 "Invalid" 1 "Mute ANN2 CEN" 2 "UnMute ANN2 CEN";
VAL_ 1138 AMP_SET_ANN2_RR_Mute 0 "Invalid" 1 "Mute ANN2 RR" 2 "UnMute ANN2 RR";
VAL_ 1138 AMP_SET_ANN2_RL_Mute 0 "Invalid" 1 "Mute ANN2 RL" 2 "UnMute ANN2 RL";
VAL_ 1138 AMP_SET_ANN2_FR_Mute 0 "Invalid" 1 "Mute ANN2 FR" 2 "UnMute ANN2 FR";
VAL_ 1138 AMP_SET_ANN2_FL_Mute 0 "Invalid" 1 "Mute ANN2 FL" 2 "UnMute ANN2 FL";
VAL_ 1152 PSM_DrvSeatMissalignment 0 "Off" 1 "Driver Power seat malfunction, Seat Initialization required";
VAL_ 1152 PSM_PasSeatMisalignment 0 "Off" 1 "Passenger Power seat malfunction, Seat Initialization required";
